VERSION ""

NS_ :

BS_:

BU_: ARS_FD SHVU_CCS_FD WPC_FD WPC2_FD SCM_FD SHVU_FRNT_FD GW_SAU_DRV_FD ATS_FD PSB_FD GW_PSU_RR_FD SHVU_RL_FD RWPC_FD CGW_CCU OHCL_FD SHVU_REAR_FD BLTN_CAM_FD GW_PSU_DRV_FD FCS_FD GW_PSU_AST_FD GW_PSU_3RD_FD RCS_FD SHVU_3RD_FD GW_PSU_RL_FD SHVU_RR_FD RCM_FD SGU_FD DCM_FD

BO_ 813 SBCM_DRV_FD_01_200ms: 32 CGW_CCU
 SG_ SBCM_DRV_FD_Crc1Val : 0|16@1+ (1,0) [0|0] ""  GW_PSU_DRV_FD
 SG_ Latch_TypeOption_DRV : 100|2@1+ (1,0) [0|0] ""  RWPC_FD,WPC2_FD,WPC_FD
 SG_ DRV_SWFailAlarm : 102|2@1+ (1,0) [0|0] ""  ATS_FD
 SG_ USM_PwrDRApprOpnSetSta : 104|2@1+ (1,0) [0|0] "" Vector__XXX
 SG_ USM_PwrDRApprOpnSetOpt : 106|2@1+ (1,0) [0|0] "" Vector__XXX
 SG_ USM_PwrDRCloseByRKELockSta : 108|2@1+ (1,0) [0|0] "" Vector__XXX
 SG_ USM_PwrDRCloseByRKELockOpt : 110|2@1+ (1,0) [0|0] "" Vector__XXX
 SG_ USM_PwrDRCloseByBrakeSta : 112|2@1+ (1,0) [0|0] "" Vector__XXX
 SG_ USM_PwrDRCloseByBrakeOpt : 114|2@1+ (1,0) [0|0] "" Vector__XXX
 SG_ USM_PwrDRBuzzerSta : 116|2@1+ (1,0) [0|0] "" Vector__XXX
 SG_ USM_PwrDRBuzzerOpt : 118|2@1+ (1,0) [0|0] "" Vector__XXX
 SG_ PDS_TypeOption_DRV : 120|2@1+ (1,0) [0|0] ""  ATS_FD
 SG_ C_DrvDoorApproachOpen : 122|2@1+ (1,0) [0|0] "" Vector__XXX
 SG_ C_DrvDoorApproachClose : 124|2@1+ (1,0) [0|0] "" Vector__XXX
 SG_ DoorLock_PDSLkSwSta_DRV : 126|2@1+ (1,0) [0|0] "" Vector__XXX
 SG_ SBCM_DRV_DiagSta : 136|2@1+ (1,0) [0|0] "" Vector__XXX
 SG_ DoorLock_CtrlDrLkUnLkSwSta_SBCM : 138|2@1+ (1,0) [0|0] "" Vector__XXX
 SG_ SBCM_PsvDrLkReq : 144|2@1+ (1,0) [0|0] "" Vector__XXX
 SG_ CDMAutoWashModeSet_SBCM : 146|3@1+ (1,0) [0|0] "" Vector__XXX
 SG_ USM_DrvGhostDoorSta : 150|2@1+ (1,0) [0|0] "" Vector__XXX
 SG_ Mirror_LH_FoldingSta : 152|2@1+ (1,0) [0|0] "" Vector__XXX
 SG_ Mirror_LH_UnfoldingSta : 154|2@1+ (1,0) [0|0] "" Vector__XXX
 SG_ DRV_CrashMRActAlarm : 156|2@1+ (1,0) [0|0] "" Vector__XXX
 SG_ AFH_DRV_FldUnFldSta : 158|2@1+ (1,0) [0|0] "" Vector__XXX
 SG_ SBCM_DRV_FD_AlvCnt1Val : 16|8@1+ (1,0) [0|0] ""  GW_PSU_DRV_FD
 SG_ MirrorFldReq : 160|2@1+ (1,0) [0|0] "" Vector__XXX
 SG_ OMU_TypeOption_DRV : 162|2@1+ (1,0) [0|0] "" Vector__XXX
 SG_ IMS_OSMirPlayBackSta_LH : 164|4@1+ (1,0) [0|0] ""  GW_PSU_DRV_FD
 SG_ ECMMRR_PLUS : 168|8@1+ (1,0) [0|0] "" Vector__XXX
 SG_ EHL_TxInfo_SBCM_DRV : 176|3@1+ (1,0) [0|0] "" Vector__XXX
 SG_ IMS_OSMirPlayBackSta_LH_New : 184|4@1+ (1,0) [0|0] ""  GW_PSU_DRV_FD
 SG_ CDM_InsideOpnSwSta : 200|2@1+ (1,0) [0|0] "" Vector__XXX
 SG_ CDM_TypeOption : 202|2@1+ (1,0) [0|0] "" Vector__XXX
 SG_ CDM_ImmeChgSw_SBCM : 208|2@1+ (1,0) [0|0] "" Vector__XXX
 SG_ CDM_FobSrchReq_DRV : 210|2@1+ (1,0) [0|0] "" Vector__XXX
 SG_ CDM_OpnClsState_SBCM : 212|2@1+ (1,0) [0|0] "" Vector__XXX
 SG_ CDM_WarnMsg_SBCM : 214|2@1+ (1,0) [0|0] "" Vector__XXX
 SG_ CDM_AutoWashModeSta : 216|3@1+ (1,0) [0|0] "" Vector__XXX
 SG_ CDM_CmdStatus_SBCM : 220|4@1+ (1,0) [0|0] "" Vector__XXX
 SG_ CDM_OutsideOpnSwSta : 224|2@1+ (1,0) [0|0] "" Vector__XXX
 SG_ PwrDRBuzzerOut_DRV : 226|2@1+ (1,0) [0|0] "" Vector__XXX
 SG_ Warn_HoodSwSta_SBCM : 228|2@1+ (1,0) [0|0] ""  BLTN_CAM_FD
 SG_ Hood_TypeOption : 230|2@1+ (1,0) [0|0] ""  BLTN_CAM_FD
 SG_ SBCM_FrunkSta : 232|2@1+ (1,0) [0|0] "" Vector__XXX
 SG_ Warn_HoodSwFullSta_SBCM : 234|2@1+ (1,0) [0|0] "" Vector__XXX
 SG_ FrunkWarning_SBCM : 236|2@1+ (1,0) [0|0] "" Vector__XXX
 SG_ SBCM_Longkey_DRVDrAtClsSwSta : 238|2@1+ (1,0) [0|0] "" Vector__XXX
 SG_ FrunkReleaseSwSta_SBCM : 24|2@1+ (1,0) [0|0] "" Vector__XXX
 SG_ PwrDRClosingDRVDrSta : 240|3@1+ (1,0) [0|0] ""  ATS_FD
 SG_ Drv_DrLkRetryFail_SBCM : 243|2@1+ (1,0) [0|0] "" Vector__XXX
 SG_ CDM_GbtImmeChgSw_SBCM : 246|2@1+ (1,0) [0|0] "" Vector__XXX
 SG_ CDM_GbtOpnClsState_SBCM : 248|2@1+ (1,0) [0|0] "" Vector__XXX
 SG_ CDM_GbtWarnMsg_SBCM : 250|2@1+ (1,0) [0|0] "" Vector__XXX
 SG_ CDM_GbtOutsideOpnSwSta : 252|2@1+ (1,0) [0|0] "" Vector__XXX
 SG_ DoorLock_DrvLkOutSta_SBCM : 254|2@1+ (1,0) [0|0] "" Vector__XXX
 SG_ FrunkEmergencySwSta_SBCM : 28|2@1+ (1,0) [0|0] "" Vector__XXX
 SG_ DRV_DetectObj_warn_LH : 30|2@1+ (1,0) [0|0] ""  ATS_FD
 SG_ PwrDROpenClosingDdvSdDRSta : 32|3@1+ (1,0) [0|0] ""  ATS_FD
 SG_ PwrDRBuzzerOut_DRV_New : 35|3@1+ (1,0) [0|0] "" Vector__XXX
 SG_ Coach_TypeOption_DRV : 38|2@1+ (1,0) [0|0] ""  ATS_FD,GW_PSU_RL_FD,GW_PSU_RR_FD
 SG_ PwrDrSta_Drv : 40|2@1+ (1,0) [0|0] ""  ATS_FD
 SG_ PwrDrSta_DrvSd : 42|2@1+ (1,0) [0|0] ""  ATS_FD
 SG_ USM_PwrDrOpnTypSta : 44|2@1+ (1,0) [0|0] "" Vector__XXX
 SG_ DischrgDr_OpnClsState_SBCM : 46|2@1+ (1,0) [0|0] "" Vector__XXX
 SG_ SBCM_FL_DoorAngle : 48|7@1+ (1,0) [0|0] "˚"  ATS_FD
 SG_ SBCM_DoorType_DRV : 60|2@1+ (1,0) [0|0] "" Vector__XXX
 SG_ CDM_DrType_DRV : 62|2@1+ (1,0) [0|0] "" Vector__XXX
 SG_ DRVDoorPushAlarm : 72|2@1+ (1,0) [0|0] "" Vector__XXX
 SG_ DRV_CrashUnlockCmd : 74|1@1+ (1,0) [0|0] ""  BLTN_CAM_FD
 SG_ C_ApprOpenStatus : 75|1@1+ (1,0) [0|0] "" Vector__XXX
 SG_ DoorLock_DrvKeyLkSwSta_SBCM : 80|2@1+ (1,0) [0|0] "" Vector__XXX
 SG_ DoorLock_DrvKeyUnLkSwSta_SBCM : 82|2@1+ (1,0) [0|0] "" Vector__XXX
 SG_ Warn_DrvDrSwSta_SBCM : 84|2@1+ (1,0) [0|0] ""  ATS_FD,BLTN_CAM_FD,DCM_FD,GW_PSU_DRV_FD,PSB_FD,RWPC_FD,WPC2_FD,WPC_FD
 SG_ DoorLock_DrvDrUnLkSta_SBCM : 86|2@1+ (1,0) [0|0] ""  ATS_FD,FCS_FD,GW_PSU_DRV_FD
 SG_ DRV_SEAWarn_LH : 88|2@1+ (1,0) [0|0] ""  ATS_FD
 SG_ DRV_SEAWarn_RH : 90|2@1+ (1,0) [0|0] "" Vector__XXX
 SG_ DRV_SEWWarn_LH : 92|2@1+ (1,0) [0|0] "" Vector__XXX
 SG_ DRV_SEWWarn_RH : 94|2@1+ (1,0) [0|0] "" Vector__XXX
 SG_ DRV_MRActivationAlarm : 96|2@1+ (1,0) [0|0] "" Vector__XXX
 SG_ DRV_ReleaseWarn : 98|2@1+ (1,0) [0|0] "" Vector__XXX

BO_ 994 PDC_FD_03_200ms: 16 CGW_CCU
 SG_ PDC_FD_Crc3Val : 0|16@1+ (1,0) [0|0] ""  GW_PSU_DRV_FD
 SG_ PDC_FD_AlvCnt3Val : 16|8@1+ (1,0) [0|0] ""  GW_PSU_DRV_FD
 SG_ Warn_DrvDrSwSta : 64|2@1+ (1,0) [0|0] ""  BLTN_CAM_FD,DCM_FD,GW_PSU_DRV_FD,PSB_FD,RWPC_FD,WPC2_FD,WPC_FD
 SG_ Warn_AsstDrSwSta : 66|2@1+ (1,0) [0|0] ""  BLTN_CAM_FD,DCM_FD,GW_PSU_AST_FD,GW_PSU_RL_FD,GW_SAU_DRV_FD,PSB_FD,RWPC_FD,WPC2_FD,WPC_FD
 SG_ Warn_RrLftDrSwSta : 68|2@1+ (1,0) [0|0] ""  BLTN_CAM_FD,DCM_FD,GW_PSU_AST_FD,GW_PSU_RL_FD,GW_PSU_RR_FD,PSB_FD,RWPC_FD,SHVU_RL_FD,WPC2_FD,WPC_FD
 SG_ Warn_RrRtDrSwSta : 70|2@1+ (1,0) [0|0] ""  BLTN_CAM_FD,DCM_FD,GW_PSU_AST_FD,GW_PSU_RL_FD,GW_PSU_RR_FD,PSB_FD,RWPC_FD,SHVU_RR_FD,WPC2_FD,WPC_FD
 SG_ Warn_HoodSwSta : 72|2@1+ (1,0) [0|0] ""  BLTN_CAM_FD
 SG_ DoorLock_DrvDrUnLkSta : 74|2@1+ (1,0) [0|0] ""  GW_PSU_DRV_FD
 SG_ DoorLock_AsstDrUnLkSta : 76|2@1+ (1,0) [0|0] "" Vector__XXX
 SG_ DoorLock_RrLftDrUnLkSta : 78|2@1+ (1,0) [0|0] "" Vector__XXX
 SG_ DoorLock_RrRtDrUnLkSta : 80|2@1+ (1,0) [0|0] "" Vector__XXX
 SG_ DoorLock_DrvKeyLkSwSta : 82|2@1+ (1,0) [0|0] "" Vector__XXX
 SG_ DoorLock_DrvKeyUnLkSwSta : 84|2@1+ (1,0) [0|0] "" Vector__XXX
 SG_ DoorLock_CtrlDrLkSwSta_ICU : 86|2@1+ (1,0) [0|0] "" Vector__XXX
 SG_ DoorLock_CtrlDrUnLkSwSta_ICU : 88|2@1+ (1,0) [0|0] "" Vector__XXX
 SG_ DoorLock_CtrlDrLkUnLkSwSta_ICU : 90|2@1+ (1,0) [0|0] "" Vector__XXX
 SG_ C_CrashUnlockState : 92|2@1+ (1,0) [0|0] ""  BLTN_CAM_FD
 SG_ Lamp_LedHdLmpSta : 94|2@1+ (1,0) [0|0] "" Vector__XXX
 SG_ Warn_ChaDrSwFrtSta : 96|2@1+ (1,0) [0|0] "" Vector__XXX
 SG_ Warn_ChaDrSwRrSta : 98|2@1+ (1,0) [0|0] "" Vector__XXX

BO_ 1242 CLU_09_00ms: 8 CGW_CCU
 SG_ CLU_Crc9Val : 0|16@1+ (1,0) [0|0] "" Vector__XXX
 SG_ CLU_AlvCnt9Val : 16|8@1+ (1,0) [0|0] "" Vector__XXX
 SG_ USM_MdLmpClrSetReq : 24|4@1+ (1,0) [0|0] "" Vector__XXX
 SG_ USM_RrWiperRevSetReq : 28|2@1+ (1,0) [0|0] "" Vector__XXX
 SG_ USM_RrStRemindSetReq : 30|2@1+ (1,0) [0|0] "" Vector__XXX
 SG_ USM_RrWpcSetReq : 32|2@1+ (1,0) [0|0] "" Vector__XXX
 SG_ USM_WpcSetReq : 34|2@1+ (1,0) [0|0] ""  WPC_FD,WPC2_FD
 SG_ USM_SeqLmpSetReq : 36|2@1+ (1,0) [0|0] "" Vector__XXX
 SG_ USM_UnlckWlcmSetReq : 38|2@1+ (1,0) [0|0] "" Vector__XXX
 SG_ USM_SmrtWlcmSetReq : 40|2@1+ (1,0) [0|0] "" Vector__XXX
 SG_ USM_UipSetReq : 42|2@1+ (1,0) [0|0] "" Vector__XXX
 SG_ USM_DigitalKeyEnblSetReq : 44|2@1+ (1,0) [0|0] "" Vector__XXX
 SG_ USM_OwnerPhnRegSetReq : 46|2@1+ (1,0) [0|0] "" Vector__XXX
 SG_ USM_NFCCard1RegSetReq : 48|2@1+ (1,0) [0|0] "" Vector__XXX
 SG_ USM_NFCCard2RegSetReq : 50|2@1+ (1,0) [0|0] "" Vector__XXX
 SG_ USM_ProcStpReq : 52|1@1+ (1,0) [0|0] "" Vector__XXX
 SG_ USM_PwrAutoOffTimeSetReq : 54|3@1+ (1,0) [0|0] "" Vector__XXX
 SG_ USM_RrStRemindSetReq_RestMode : 57|3@1+ (1,0) [0|0] "" Vector__XXX
 SG_ USM_1stRrStRemindSetReq : 60|2@1+ (1,0) [0|0] "" Vector__XXX
 SG_ USM_Wpc2SetReq : 62|2@1+ (1,0) [0|0] ""  WPC_FD,WPC2_FD

BO_ 811 SBCM_AST_FD_01_200ms: 32 CGW_CCU
 SG_ SBCM_AST_FD_Crc1Val : 0|16@1+ (1,0) [0|0] ""  GW_PSU_DRV_FD
 SG_ USM_AstGhostDoorSta : 100|2@1+ (1,0) [0|0] "" Vector__XXX
 SG_ AST_SWFailAlarm : 102|2@1+ (1,0) [0|0] ""  ATS_FD
 SG_ DoorLock_PDSLkSwSta_AST : 104|2@1+ (1,0) [0|0] "" Vector__XXX
 SG_ PDS_TypeOption_AST : 106|2@1+ (1,0) [0|0] "" Vector__XXX
 SG_ AFCU_AutoWashModeSta_SBCM_AST : 120|3@1+ (1,0) [0|0] "" Vector__XXX
 SG_ CDM_AutoWashModeSta_SBCM_AST : 123|3@1+ (1,0) [0|0] "" Vector__XXX
 SG_ AFH_AST_FldUnFldSta : 126|2@1+ (1,0) [0|0] "" Vector__XXX
 SG_ SBCM_AST_DiagSta : 136|2@1+ (1,0) [0|0] "" Vector__XXX
 SG_ CDM_TypeOption_AST : 138|2@1+ (1,0) [0|0] "" Vector__XXX
 SG_ CDM_ImmeChgSw_AST : 144|2@1+ (1,0) [0|0] "" Vector__XXX
 SG_ CDM_FobSrchReq_AST : 146|2@1+ (1,0) [0|0] "" Vector__XXX
 SG_ CDM_OpnClsState_AST : 148|2@1+ (1,0) [0|0] "" Vector__XXX
 SG_ CDM_WarnMsg_AST : 150|2@1+ (1,0) [0|0] "" Vector__XXX
 SG_ Mirror_RH_FoldingSta : 152|2@1+ (1,0) [0|0] "" Vector__XXX
 SG_ Mirror_RH_UnfoldingSta : 154|2@1+ (1,0) [0|0] "" Vector__XXX
 SG_ CDM_CmdStatus_AST : 156|4@1+ (1,0) [0|0] "" Vector__XXX
 SG_ SBCM_AST_FD_AlvCnt1Val : 16|8@1+ (1,0) [0|0] ""  GW_PSU_DRV_FD
 SG_ AST_CrashMRActAlarm : 160|2@1+ (1,0) [0|0] "" Vector__XXX
 SG_ PwrDRBuzzerOut_AST : 162|2@1+ (1,0) [0|0] "" Vector__XXX
 SG_ IMS_OSMirPlayBackSta_RH : 164|4@1+ (1,0) [0|0] ""  GW_PSU_DRV_FD
 SG_ PwrDRClosingASTDrSta : 168|3@1+ (1,0) [0|0] ""  ATS_FD
 SG_ CDM_OutsideOpnSwSta_AST : 172|2@1+ (1,0) [0|0] "" Vector__XXX
 SG_ SBCM_Longkey_ASTDrAtClsSwSta : 174|2@1+ (1,0) [0|0] "" Vector__XXX
 SG_ Hood_TypeOption_AST : 176|2@1+ (1,0) [0|0] "" Vector__XXX
 SG_ Warn_HoodSwSta_AST : 178|2@1+ (1,0) [0|0] "" Vector__XXX
 SG_ FrunkWarning_AST : 180|2@1+ (1,0) [0|0] "" Vector__XXX
 SG_ SBCM_FrunkSta_AST : 182|2@1+ (1,0) [0|0] "" Vector__XXX
 SG_ IMS_OSMirPlayBackSta_RH_New : 184|4@1+ (1,0) [0|0] ""  GW_PSU_DRV_FD
 SG_ Ast_DrLkRetryFail_SBCM : 188|2@1+ (1,0) [0|0] "" Vector__XXX
 SG_ DoorLock_AstLkOutSta_SBCM : 190|2@1+ (1,0) [0|0] "" Vector__XXX
 SG_ FrunkReleaseSwSta_SBCM_AST : 192|2@1+ (1,0) [0|0] "" Vector__XXX
 SG_ FrunkInsideRelSwSta_SBCM_AST : 194|2@1+ (1,0) [0|0] "" Vector__XXX
 SG_ FrunkEmergencySwSta_SBCM_AST : 196|2@1+ (1,0) [0|0] "" Vector__XXX
 SG_ PwrDrSta_Ast : 24|2@1+ (1,0) [0|0] ""  ATS_FD
 SG_ PwrDrSta_AstSd : 26|2@1+ (1,0) [0|0] ""  ATS_FD
 SG_ DischrgDr_OpnClsState_SBCM_AST : 28|2@1+ (1,0) [0|0] "" Vector__XXX
 SG_ AST_DetectObj_warn_LH : 30|2@1+ (1,0) [0|0] ""  ATS_FD
 SG_ PwrDROpenClosingAstSdDRSta : 32|3@1+ (1,0) [0|0] ""  ATS_FD
 SG_ PwrDRBuzzerOut_AST_New : 35|3@1+ (1,0) [0|0] "" Vector__XXX
 SG_ SBCM_FR_DoorAngle : 40|7@1+ (1,0) [0|0] "˚"  ATS_FD
 SG_ EHL_TxInfo_SBCM_AST : 47|3@1+ (1,0) [0|0] "" Vector__XXX
 SG_ CDM_DrType_AST : 62|2@1+ (1,0) [0|0] "" Vector__XXX
 SG_ ASTDoorPushAlarm : 72|2@1+ (1,0) [0|0] "" Vector__XXX
 SG_ AST_CrashUnlockCmd : 74|1@1+ (1,0) [0|0] ""  BLTN_CAM_FD
 SG_ DoorLock_CtrlDrLkSwSta_SBCM : 80|2@1+ (1,0) [0|0] "" Vector__XXX
 SG_ DoorLock_CtrlDrUnLkSwSta_SBCM : 82|2@1+ (1,0) [0|0] "" Vector__XXX
 SG_ Warn_AsstDrSwSta_SBCM : 84|2@1+ (1,0) [0|0] ""  ATS_FD,BLTN_CAM_FD,DCM_FD,GW_PSU_AST_FD,GW_SAU_DRV_FD,PSB_FD,RWPC_FD,WPC2_FD,WPC_FD
 SG_ DoorLock_AsstDrUnLkSta_SBCM : 86|2@1+ (1,0) [0|0] ""  ATS_FD,FCS_FD
 SG_ AST_SEAWarn_RH : 88|2@1+ (1,0) [0|0] "" Vector__XXX
 SG_ AST_SEAWarn_LH : 90|2@1+ (1,0) [0|0] ""  ATS_FD
 SG_ AST_SEWWarn_LH : 92|2@1+ (1,0) [0|0] "" Vector__XXX
 SG_ AST_SEWWarn_RH : 94|2@1+ (1,0) [0|0] "" Vector__XXX
 SG_ AST_MRActivationAlarm : 96|2@1+ (1,0) [0|0] "" Vector__XXX
 SG_ AST_ReleaseWarn : 98|2@1+ (1,0) [0|0] "" Vector__XXX

BO_ 789 CLU_20_200ms: 16 CGW_CCU
 SG_ CLU_Crc20Val : 0|16@1+ (1,0) [0|0] "" Vector__XXX
 SG_ CLU_AlvCnt20Val : 16|8@1+ (1,0) [0|0] "" Vector__XXX
 SG_ CLU_SndType : 24|2@1- (1,0) [0|0] "" Vector__XXX
 SG_ USM_AdasHDPSetReq : 46|2@1+ (1,0) [0|0] "" Vector__XXX
 SG_ CLU_ClusterUSM : 49|2@1+ (1,0) [0|0] ""  WPC_FD,WPC2_FD

BO_ 849 IAU_FD_04_200ms: 32 CGW_CCU
 SG_ IAU_FD_Crc4Val : 0|16@1+ (1,0) [0|0] "0"  GW_PSU_DRV_FD
 SG_ IAU_DISPWrng : 104|4@1+ (1,0) [0|0] "" Vector__XXX
 SG_ IAU_DigitalKey2Opt : 120|3@1+ (1,0) [0|0] ""  WPC2_FD,WPC_FD
 SG_ IAUwFRULearnState : 124|2@1+ (1,0) [0|0] "" Vector__XXX
 SG_ IAUwFPMLearnState : 126|2@1+ (1,0) [0|0] "" Vector__XXX
 SG_ IAU_ValetDigitalkey : 128|2@1+ (1,0) [0|0] "" Vector__XXX
 SG_ IAU_DigitalKeyNumberOpt : 130|3@1+ (1,0) [0|0] "" Vector__XXX
 SG_ IAU_eSEReprogramSta : 133|2@1+ (1,0) [0|0] "" Vector__XXX
 SG_ IAU_DKOwnerSwapOption : 136|2@1+ (1,0) [0|0] "" Vector__XXX
 SG_ IAU_DgtKeyGrpPrflRval2 : 139|5@1+ (1,0) [0|0] "" Vector__XXX
 SG_ IAU_StartIdentifiedProfile : 144|3@1+ (1,0) [0|0] "" Vector__XXX
 SG_ IAU_DigitalKeyProfileRval2 : 147|5@1+ (1,0) [0|0] "" Vector__XXX
 SG_ IAU_NFCCard1SN : 152|32@1+ (1,0) [0|0] "" Vector__XXX
 SG_ IAU_FD_AlvCnt4Val : 16|8@1+ (1,0) [0|0] "0"  GW_PSU_DRV_FD
 SG_ IAU_StartIdentifiedProfile_Ext : 24|4@1+ (1,0) [0|0] "" Vector__XXX
 SG_ RSPA_UWBRspaExtRngSta : 246|2@1+ (1,0) [0|0] "" Vector__XXX
 SG_ RSPA_CanFltSta : 250|2@1+ (1,0) [0|0] "" Vector__XXX
 SG_ RSPA_BLESigErrSta : 252|2@1+ (1,0) [0|0] "" Vector__XXX
 SG_ RSPA_ConStat : 254|2@1+ (1,0) [0|0] "" Vector__XXX
 SG_ IAU_ProfileIDRVal : 74|4@1+ (1,0) [0|0] ""  BLTN_CAM_FD,GW_PSU_DRV_FD,GW_SAU_DRV_FD,RCM_FD,RWPC_FD,SGU_FD,WPC2_FD,WPC_FD
 SG_ IAU_DigitalKeyProcessingSta : 80|4@1+ (1,0) [0|0] "" Vector__XXX
 SG_ IAU_DigitalKeyExit : 84|4@1+ (1,0) [0|0] "" Vector__XXX
 SG_ IAU_DigitalKeyEnblRVal : 88|2@1+ (1,0) [0|0] "" Vector__XXX
 SG_ IAU_OwnerPhnRegRVal : 90|2@1+ (1,0) [0|0] "" Vector__XXX
 SG_ IAU_NFCCard1RegRVal : 92|2@1+ (1,0) [0|0] "" Vector__XXX
 SG_ IAU_NFCCard2RegRVal : 94|2@1+ (1,0) [0|0] "" Vector__XXX

BO_ 788 RWPC_FD_01_200ms: 16 RWPC_FD
 SG_ RWPC_FD_Crc1Val : 0|16@1+ (1,0) [0|0] "" Vector__XXX
 SG_ RWPC_IndSyncVal : 104|3@1+ (1,0) [0|0] ""  WPC2_FD,WPC_FD
 SG_ RWPC_ResetOpSta : 110|2@1+ (1,0) [0|0] "" Vector__XXX
 SG_ RWPC_FD_AlvCnt1Val : 16|8@1+ (1,0) [0|0] "" Vector__XXX
 SG_ USM_ValCmdSta : 64|2@1+ (1,0) [0|0] ""  ATS_FD,CGW_CCU
 SG_ WPC_PhnLftWrngRWPCSta : 66|3@1+ (1,0) [0|0] ""  ATS_FD,CGW_CCU
 SG_ USM_ValCmdStaforATS : 69|2@1+ (1,0) [0|0] ""  ATS_FD
 SG_ RWPC_SWVerMajor1 : 72|7@1+ (1,0) [0|0] ""  CGW_CCU
 SG_ RWPC_SWVerMinor1 : 80|7@1+ (1,0) [0|0] ""  CGW_CCU
 SG_ RWPC_SWVerMinor2 : 88|7@1+ (1,0) [0|0] ""  CGW_CCU

BO_ 977 BDC_FD_02_200ms: 32 CGW_CCU
 SG_ BDC_FD_Crc2Val : 0|16@1+ (1,0) [0|0] ""  GW_PSU_DRV_FD
 SG_ BDC_FD_AlvCnt2Val : 16|8@1+ (1,0) [0|0] ""  GW_PSU_DRV_FD
 SG_ BCM_KeyInSta : 24|2@1+ (1,0) [0|0] ""  DCM_FD,GW_PSU_3RD_FD,GW_PSU_AST_FD,GW_PSU_DRV_FD,GW_PSU_RL_FD,GW_PSU_RR_FD,GW_SAU_DRV_FD,SGU_FD,SHVU_3RD_FD,SHVU_CCS_FD,SHVU_FRNT_FD,SHVU_REAR_FD,SHVU_RL_FD,SHVU_RR_FD
 SG_ BCM_AccInSta : 26|2@1+ (1,0) [0|0] ""  ATS_FD,DCM_FD,FCS_FD,GW_PSU_3RD_FD,GW_PSU_AST_FD,GW_PSU_DRV_FD,GW_PSU_RL_FD,GW_PSU_RR_FD,GW_SAU_DRV_FD,SCM_FD,SGU_FD,SHVU_3RD_FD,SHVU_CCS_FD,SHVU_FRNT_FD,SHVU_REAR_FD,SHVU_RL_FD,SHVU_RR_FD,WPC2_FD
 SG_ BCM_Ign1InSta : 28|2@1+ (1,0) [0|0] ""  ATS_FD,DCM_FD,FCS_FD,GW_PSU_3RD_FD,GW_PSU_AST_FD,GW_PSU_DRV_FD,GW_PSU_RL_FD,GW_PSU_RR_FD,GW_SAU_DRV_FD,RCM_FD,SCM_FD,SGU_FD,SHVU_3RD_FD,SHVU_CCS_FD,SHVU_FRNT_FD,SHVU_REAR_FD,SHVU_RL_FD,SHVU_RR_FD
 SG_ BCM_Ign2InSta : 30|2@1+ (1,0) [0|0] ""  ATS_FD,DCM_FD,FCS_FD,GW_PSU_3RD_FD,GW_PSU_AST_FD,GW_PSU_DRV_FD,GW_PSU_RL_FD,GW_PSU_RR_FD,GW_SAU_DRV_FD,RCM_FD,SCM_FD,SGU_FD,SHVU_3RD_FD,SHVU_CCS_FD,SHVU_FRNT_FD,SHVU_REAR_FD,SHVU_RL_FD,SHVU_RR_FD
 SG_ IBU_HDPSpprtSWVer : 32|6@1+ (1,0) [0|0] "" Vector__XXX
 SG_ IBU_HDPSpprtRdy : 38|2@1+ (1,0) [0|0] "" Vector__XXX
 SG_ BCM_GearPosPSta : 40|2@1+ (1,0) [0|0] ""  ATS_FD,GW_PSU_3RD_FD,GW_PSU_AST_FD,GW_PSU_DRV_FD,GW_PSU_RL_FD,GW_PSU_RR_FD,SCM_FD,SHVU_RL_FD,SHVU_RR_FD
 SG_ BCM_SmkOptTyp : 42|2@1+ (1,0) [0|0] ""  RWPC_FD,WPC2_FD,WPC_FD
 SG_ BDC_ResetOpSta : 44|2@1+ (1,0) [0|0] "" Vector__XXX
 SG_ IBU_SWVerMajor1 : 48|7@1+ (1,0) [0|0] "" Vector__XXX
 SG_ IBU_SWVerMinor1 : 56|7@1+ (1,0) [0|0] "" Vector__XXX
 SG_ IBU_SWVerMinor2 : 64|7@1+ (1,0) [0|0] "" Vector__XXX
 SG_ BDC_PlatformVerType : 72|4@1+ (1,0) [0|0] "" Vector__XXX
 SG_ BDC_PlatformVerDate : 80|8@1+ (1,0) [0|0] "" Vector__XXX

BO_ 914 WPC2_FD_01_200ms: 16 WPC_FD
 SG_ WPC2_FD_Crc1Val : 0|16@1+ (1,0) [0|0] "" Vector__XXX
 SG_ WPC2_IndSyncVal : 104|3@1+ (1,0) [0|0] ""  RWPC_FD
 SG_ WPC2_ResetOpSta : 110|2@1+ (1,0) [0|0] "" Vector__XXX
 SG_ WPC2_FD_AlvCnt1Val : 16|8@1+ (1,0) [0|0] "" Vector__XXX
 SG_ USM_CmdWPC2Sta : 64|2@1+ (1,0) [0|0] ""  CGW_CCU
 SG_ WPC2_PhnLftWrngSta : 66|3@1+ (1,0) [0|0] ""  CGW_CCU
 SG_ WPC2_OptSta : 76|2@1+ (1,0) [0|0] ""  CGW_CCU
 SG_ WPC2_SWVerMajor1 : 80|7@1+ (1,0) [0|0] ""  CGW_CCU
 SG_ WPC2_SWVerMinor1 : 88|7@1+ (1,0) [0|0] ""  CGW_CCU
 SG_ WPC2_SWVerMinor2 : 96|7@1+ (1,0) [0|0] ""  CGW_CCU

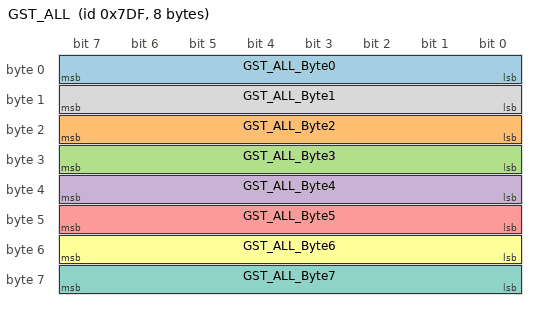
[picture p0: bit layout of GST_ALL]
BO_ 2015 GST_ALL: 8 CGW_CCU
 SG_ GST_ALL_Byte0 : 0|8@1+ (1,0) [0|0] ""  ARS_FD,ATS_FD,FCS_FD,GW_PSU_3RD_FD,GW_PSU_AST_FD,GW_PSU_DRV_FD,GW_PSU_RL_FD,GW_PSU_RR_FD,GW_SAU_DRV_FD,PSB_FD,RCM_FD,RCS_FD,RWPC_FD,SCM_FD,SGU_FD,SHVU_3RD_FD,SHVU_CCS_FD,SHVU_FRNT_FD,SHVU_REAR_FD,SHVU_RL_FD,SHVU_RR_FD,WPC2_FD,WPC_FD
 SG_ GST_ALL_Byte2 : 16|8@1+ (1,0) [0|0] ""  ARS_FD,ATS_FD,FCS_FD,GW_PSU_3RD_FD,GW_PSU_AST_FD,GW_PSU_DRV_FD,GW_PSU_RL_FD,GW_PSU_RR_FD,GW_SAU_DRV_FD,PSB_FD,RCM_FD,RCS_FD,RWPC_FD,SCM_FD,SGU_FD,SHVU_3RD_FD,SHVU_CCS_FD,SHVU_FRNT_FD,SHVU_REAR_FD,SHVU_RL_FD,SHVU_RR_FD,WPC2_FD,WPC_FD
 SG_ GST_ALL_Byte3 : 24|8@1+ (1,0) [0|0] ""  ARS_FD,ATS_FD,FCS_FD,GW_PSU_3RD_FD,GW_PSU_AST_FD,GW_PSU_DRV_FD,GW_PSU_RL_FD,GW_PSU_RR_FD,GW_SAU_DRV_FD,PSB_FD,RCM_FD,RCS_FD,RWPC_FD,SCM_FD,SGU_FD,SHVU_3RD_FD,SHVU_CCS_FD,SHVU_FRNT_FD,SHVU_REAR_FD,SHVU_RL_FD,SHVU_RR_FD,WPC2_FD,WPC_FD
 SG_ GST_ALL_Byte4 : 32|8@1+ (1,0) [0|0] ""  ARS_FD,ATS_FD,FCS_FD,GW_PSU_3RD_FD,GW_PSU_AST_FD,GW_PSU_DRV_FD,GW_PSU_RL_FD,GW_PSU_RR_FD,GW_SAU_DRV_FD,PSB_FD,RCM_FD,RCS_FD,RWPC_FD,SCM_FD,SGU_FD,SHVU_3RD_FD,SHVU_CCS_FD,SHVU_FRNT_FD,SHVU_REAR_FD,SHVU_RL_FD,SHVU_RR_FD,WPC2_FD,WPC_FD
 SG_ GST_ALL_Byte5 : 40|8@1+ (1,0) [0|0] ""  ARS_FD,ATS_FD,FCS_FD,GW_PSU_3RD_FD,GW_PSU_AST_FD,GW_PSU_DRV_FD,GW_PSU_RL_FD,GW_PSU_RR_FD,GW_SAU_DRV_FD,PSB_FD,RCM_FD,RCS_FD,RWPC_FD,SCM_FD,SGU_FD,SHVU_3RD_FD,SHVU_CCS_FD,SHVU_FRNT_FD,SHVU_REAR_FD,SHVU_RL_FD,SHVU_RR_FD,WPC2_FD,WPC_FD
 SG_ GST_ALL_Byte6 : 48|8@1+ (1,0) [0|0] ""  ARS_FD,ATS_FD,FCS_FD,GW_PSU_3RD_FD,GW_PSU_AST_FD,GW_PSU_DRV_FD,GW_PSU_RL_FD,GW_PSU_RR_FD,GW_SAU_DRV_FD,PSB_FD,RCM_FD,RCS_FD,RWPC_FD,SCM_FD,SGU_FD,SHVU_3RD_FD,SHVU_CCS_FD,SHVU_FRNT_FD,SHVU_REAR_FD,SHVU_RL_FD,SHVU_RR_FD,WPC2_FD,WPC_FD
 SG_ GST_ALL_Byte7 : 56|8@1+ (1,0) [0|0] ""  ARS_FD,ATS_FD,FCS_FD,GW_PSU_3RD_FD,GW_PSU_AST_FD,GW_PSU_DRV_FD,GW_PSU_RL_FD,GW_PSU_RR_FD,GW_SAU_DRV_FD,PSB_FD,RCM_FD,RCS_FD,RWPC_FD,SCM_FD,SGU_FD,SHVU_3RD_FD,SHVU_CCS_FD,SHVU_FRNT_FD,SHVU_REAR_FD,SHVU_RL_FD,SHVU_RR_FD,WPC2_FD,WPC_FD
 SG_ GST_ALL_Byte1 : 8|8@1+ (1,0) [0|0] ""  ARS_FD,ATS_FD,FCS_FD,GW_PSU_3RD_FD,GW_PSU_AST_FD,GW_PSU_DRV_FD,GW_PSU_RL_FD,GW_PSU_RR_FD,GW_SAU_DRV_FD,PSB_FD,RCM_FD,RCS_FD,RWPC_FD,SCM_FD,SGU_FD,SHVU_3RD_FD,SHVU_CCS_FD,SHVU_FRNT_FD,SHVU_REAR_FD,SHVU_RL_FD,SHVU_RR_FD,WPC2_FD,WPC_FD

BO_TX_BU_ 914 : WPC_FD,WPC2_FD;
CM_ BO_ 813 "[PE] Periodic and On Event";
CM_ SG_ 813 SBCM_DRV_FD_Crc1Val "SBCM_DRV_FD_CyclicRedundancyCheck1Value";
CM_ SG_ 813 C_DrvDoorApproachOpen "Approach open";
CM_ SG_ 813 DoorLock_CtrlDrLkUnLkSwSta_SBCM "Central Door Lock/Unlock Switch State";
CM_ SG_ 813 CDMAutoWashModeSet_SBCM "Auto wash mode set signal for CDM from SBCM_DRV";
CM_ SG_ 813 SBCM_DRV_FD_AlvCnt1Val "SBCM_DRV_FD_AliveCounter1Value";
CM_ SG_ 813 ECMMRR_PLUS "ECM Voltage value";
CM_ SG_ 813 EHL_TxInfo_SBCM_DRV "Electronic hood latch status signal transfer for dual hood latch type (Copy to CANFD)";
CM_ SG_ 813 CDM_TypeOption "CDM_HS_OptionType";
CM_ SG_ 813 CDM_ImmeChgSw_SBCM "State of Immediate Charging Switch";
CM_ SG_ 813 CDM_OpnClsState_SBCM "CDM_HS_ OpenCloseState";
CM_ SG_ 813 CDM_WarnMsg_SBCM "CDM_HS_WarningMessage";
CM_ SG_ 813 CDM_CmdStatus_SBCM "CDM_HS_CommandStatus";
CM_ SG_ 813 Hood_TypeOption "E-Hood_Option Type";
CM_ SG_ 813 FrunkReleaseSwSta_SBCM "FrunkReleaseState";
CM_ SG_ 813 CDM_GbtImmeChgSw_SBCM "State of Immediate Charging Switch";
CM_ SG_ 813 CDM_GbtOpnClsState_SBCM "CDM_HS_ OpenCloseState";
CM_ SG_ 813 CDM_GbtWarnMsg_SBCM "CDM_HS_WarningMessage";
CM_ SG_ 813 FrunkEmergencySwSta_SBCM "FrunkEmergencySwState";
CM_ SG_ 813 C_ApprOpenStatus "Stop fob searching signal";
CM_ SG_ 813 DoorLock_DrvKeyLkSwSta_SBCM "DoorLock_DriverKeyLockSwitchStatus ##2G## -  - C_DrvKeyLockSw";
CM_ SG_ 813 DoorLock_DrvKeyUnLkSwSta_SBCM "DoorLock_DriverKeyUnLockSwitchStatus ##2G## -  - C_DrvKeyUnlockSw";
CM_ SG_ 813 Warn_DrvDrSwSta_SBCM "DoorLock_DriverDoorSwitchStatus ##2G## -  - C_DrvDrSw,CF_Gway_DrvDrSw,Warn_DrvDrSwSta";
CM_ SG_ 813 DoorLock_DrvDrUnLkSta_SBCM "DoorLock_DriverDoorUnLockStatus ##2G## -  - C_DrvUnlockState,CF_Gway_DrvUnlockState";
CM_ BO_ 994 "[PE] Periodic and On Event";
CM_ SG_ 994 PDC_FD_Crc3Val "PDC_FD_CyclicRedundancyCheck3Value";
CM_ SG_ 994 PDC_FD_AlvCnt3Val "PDC_FD_AliveCounter3Value";
CM_ SG_ 994 Warn_DrvDrSwSta "DoorLock_DriverDoorSwitchStatus ##2G## -  - C_DrvDrSw,CF_Gway_DrvDrSw,Warn_DrvDrSwSta";
CM_ SG_ 994 Warn_AsstDrSwSta "Warn_AssistDoorSwitchStatus ##2G## -  - C_AstDrSw,CF_Gway_AstDrSw,Warn_AsstDrSwSta";
CM_ SG_ 994 Warn_RrLftDrSwSta "Warn_RearLeftDoorSwitchStatus ##2G## -  - C_RLDrSw,CF_Gway_RLDrSw,Warn_RrLftDrSwSta";
CM_ SG_ 994 Warn_RrRtDrSwSta "Warn_RearRightDoorSwitchStatus ##2G## -  - C_RRDrSw,CF_Gway_RRDrSw,Warn_RrRtDrSwSta";
CM_ SG_ 994 Warn_HoodSwSta "Warn_HoodSwitchStatus ##2G## -  - C_HoodSw,CF_Gway_HoodSw";
CM_ SG_ 994 DoorLock_DrvDrUnLkSta "DoorLock_DriverDoorUnLockStatus ##2G## -  - C_DrvUnlockState,CF_Gway_DrvUnlockState";
CM_ SG_ 994 DoorLock_AsstDrUnLkSta "DoorLock_AssistDoorUnLockStatus ##2G## -  - C_AstUnlockState,DoorLock_AsstDrUnLkSta";
CM_ SG_ 994 DoorLock_RrLftDrUnLkSta "DoorLock_RearLeftDoorUnLockStatus ##2G## -  - C_RLUnlockState,DoorLock_RrLftDrUnLkSta";
CM_ SG_ 994 DoorLock_RrRtDrUnLkSta "DoorLock_RearRightDoorUnLockStatus ##2G## -  - C_RRUnlockState,DoorLock_RrRtDrUnLkSta";
CM_ SG_ 994 DoorLock_DrvKeyLkSwSta "DoorLock_DriverKeyLockSwitchStatus ##2G## -  - C_DrvKeyLockSw";
CM_ SG_ 994 DoorLock_DrvKeyUnLkSwSta "DoorLock_DriverKeyUnLockSwitchStatus ##2G## -  - C_DrvKeyUnlockSw";
CM_ SG_ 994 DoorLock_CtrlDrLkSwSta_ICU "Central Door Lock Switch State(DRV or AST or RL or RR Door trim)";
CM_ SG_ 994 DoorLock_CtrlDrUnLkSwSta_ICU "Central Door Unlock Switch State(DRV or AST or RL or RR Door trim)";
CM_ SG_ 994 DoorLock_CtrlDrLkUnLkSwSta_ICU "Central Door Lock/Unlock Switch State(C/PAD, Integrated & self return type)";
CM_ SG_ 994 C_CrashUnlockState "Crash Unlock Active State";
CM_ SG_ 994 Lamp_LedHdLmpSta "Lamp_LedHeadLampStatus ##2G## -  - CF_Afs_LedHLStat";
CM_ SG_ 994 Warn_ChaDrSwFrtSta "##2G## - -  CF_Gway_ChaDrSwFrt";
CM_ SG_ 994 Warn_ChaDrSwRrSta "##2G## -  - CF_Gway_ChaDrSwRr";
CM_ BO_ 1242 "[EC] On Event and On Change";
CM_ SG_ 1242 CLU_Crc9Val "CLU_CyclicRedundancyCheck9Value";
CM_ SG_ 1242 CLU_AlvCnt9Val "CLU_AliveCounter9Value";
CM_ SG_ 1242 USM_MdLmpClrSetReq "USM_MoodLampColorSetRequest";
CM_ SG_ 1242 USM_RrWiperRevSetReq "USM_RearWiperReverseSetRequest";
CM_ SG_ 1242 USM_RrStRemindSetReq "USM_RrseatReminderSetRequest(2nd :General: CLU20/CF_Clu_RrSeatRemindNValueSet)";
CM_ SG_ 1242 USM_RrWpcSetReq "USM_RearWpcSetRequest";
CM_ SG_ 1242 USM_WpcSetReq "USM_WpcSetRequest";
CM_ SG_ 1242 USM_SeqLmpSetReq "USM_SequencialLampSetRequest";
CM_ SG_ 1242 USM_UnlckWlcmSetReq "USM_UnlockWelcomeSetRequest";
CM_ SG_ 1242 USM_SmrtWlcmSetReq "USM_SmartWelcomeSetRequest";
CM_ SG_ 1242 USM_UipSetReq "2nd General: CF_Clu_UIPNValueSet";
CM_ SG_ 1242 USM_DigitalKeyEnblSetReq "Request to set the Digital Key ON or OFF(2nd General DB: CF_Clu_DigitalKeyNValueSet)";
CM_ SG_ 1242 USM_OwnerPhnRegSetReq "2nd general DB: CF_Clu_OwnerPhoneNValueSet";
CM_ SG_ 1242 USM_NFCCard1RegSetReq "2nd General DB:CF_Clu_NFCCard1NValueSet";
CM_ SG_ 1242 USM_NFCCard2RegSetReq "2nd General DB:CF_Clu_NFCCard2NValueSet";
CM_ SG_ 1242 USM_ProcStpReq "2nd General DB:CF_Clu_ProcessStopReq";
CM_ SG_ 1242 USM_PwrAutoOffTimeSetReq "USM_PowerAutoofftimeSetRequest";
CM_ SG_ 1242 USM_RrStRemindSetReq_RestMode "Request to set  Restmod of Rear Seat remind";
CM_ SG_ 1242 USM_1stRrStRemindSetReq "USM_RrseatReminderSetRequest(2nd :General: CLU21/CF_Clu_1stRrSeatRemindNValueSet)";
CM_ SG_ 1242 USM_Wpc2SetReq "USM_Wpc2SetRequest";
CM_ BO_ 811 "[PE] Periodic and On Event";
CM_ SG_ 811 SBCM_AST_FD_Crc1Val "SBCM_AST_FD_CyclicRedundancyCheck1Value";
CM_ SG_ 811 SBCM_AST_FD_AlvCnt1Val "SBCM_AST_FD_AliveCounter1Value";
CM_ SG_ 811 SBCM_Longkey_ASTDrAtClsSwSta "FCS Power Door Long key Status";
CM_ SG_ 811 Hood_TypeOption_AST "E-Hood_Option Type";
CM_ SG_ 811 FrunkReleaseSwSta_SBCM_AST "FrunkReleaseState (SBCM_AST_FD to SBCM_DRV_FD) RHD Spec";
CM_ SG_ 811 FrunkInsideRelSwSta_SBCM_AST "FrunkInsideReleaseSwState (SBCM_AST_FD to SBCM_DRV_FD) RHD Spec";
CM_ SG_ 811 FrunkEmergencySwSta_SBCM_AST "FrunkEmergencySwState (SBCM_AST_FD to SBCM_DRV_FD) RHD Spec";
CM_ SG_ 811 EHL_TxInfo_SBCM_AST "Electronic hood latch status signal transfer for dual hood latch type";
CM_ SG_ 811 AST_CrashUnlockCmd "AssistCrashUnlockCommand";
CM_ SG_ 811 DoorLock_CtrlDrLkSwSta_SBCM "DoorLock_CentralDoorLockAssistSwitchStatus";
CM_ SG_ 811 DoorLock_CtrlDrUnLkSwSta_SBCM "DoorLock_CentralDoorUnLockAssistSwitchStatus";
CM_ SG_ 811 Warn_AsstDrSwSta_SBCM "Warn_AssistDoorSwitchStatus ##2G## -  - C_AstDrSw,CF_Gway_AstDrSw,Warn_AsstDrSwSta";
CM_ SG_ 811 DoorLock_AsstDrUnLkSta_SBCM "DoorLock_AssistDoorUnLockStatus ##2G## -  - C_AstUnlockState,DoorLock_AsstDrUnLkSta";
CM_ SG_ 811 AST_SEAWarn_RH "Assist SEA Warning (LHD)";
CM_ BO_ 789 "[P] Periodic";
CM_ SG_ 789 CLU_Crc20Val "CLU_CyclicRedundancyCheck20Value";
CM_ SG_ 789 CLU_AlvCnt20Val "CLU_AliveCounter20Value";
CM_ SG_ 789 CLU_SndType "CLU_SoundType";
CM_ SG_ 789 USM_AdasHDPSetReq "This signal is used for a request to set the value of USM Menus. This signal requests to change status of HDP Mode.";
CM_ BO_ 849 "[PE] Periodic and On Event";
CM_ SG_ 849 IAU_FD_Crc4Val "IAU_FD_CyclicRedundancyCheck4Value";
CM_ SG_ 849 IAU_DigitalKey2Opt "Digital Key2 Option Signal";
CM_ SG_ 849 IAU_ValetDigitalkey "Digital Key Valet Mode";
CM_ SG_ 849 IAU_DigitalKeyNumberOpt "This signal is for the digital key number type.";
CM_ SG_ 849 IAU_eSEReprogramSta "this signal is to mornitor the state of eSE reprograming.";
CM_ SG_ 849 IAU_DgtKeyGrpPrflRval2 "This signal indiactes digital key group number paired with selected profile";
CM_ SG_ 849 IAU_StartIdentifiedProfile "This signal Indicate Profile of vehicle start Identified";
CM_ SG_ 849 IAU_DigitalKeyProfileRval2 "This signal indiactes digital key number paired with selected profile";
CM_ SG_ 849 IAU_FD_AlvCnt4Val "IAU_FD_AliveCounter4Value";
CM_ SG_ 849 IAU_StartIdentifiedProfile_Ext "This signal indicate Profile of vehicle start Identified";
CM_ SG_ 849 RSPA_UWBRspaExtRngSta "RSPA remote control range of UWB";
CM_ SG_ 849 RSPA_CanFltSta "RSPA_CANErrorState";
CM_ SG_ 849 RSPA_BLESigErrSta "RSPA_RFSignalErrorState";
CM_ SG_ 849 IAU_ProfileIDRVal "This signal Indicate the Current detected Profile ID by IAU.";
CM_ SG_ 849 IAU_DigitalKeyProcessingSta "Digital Key USM settitng Process State";
CM_ SG_ 849 IAU_DigitalKeyExit "Digital Key USM setting Exit Condition";
CM_ SG_ 849 IAU_DigitalKeyEnblRVal "Digital Key Function Enable / Disable flag (Fob is required for changing flag)";
CM_ SG_ 849 IAU_OwnerPhnRegRVal "Vehicle Owner's Phone is Registered for Digital Key function";
CM_ SG_ 849 IAU_NFCCard1RegRVal "NFC Card 1 is Registered for Digital Key function";
CM_ SG_ 849 IAU_NFCCard2RegRVal "NFC Card 2 is Registered for Digital Key function";
CM_ BO_ 788 "[PE] Periodic and On Event";
CM_ SG_ 788 RWPC_FD_Crc1Val "RWPC_FD_CyclicRedundancyCheck1Value";
CM_ SG_ 788 RWPC_ResetOpSta "This signal indicates whether the reset operation has been completed or not";
CM_ SG_ 788 RWPC_FD_AlvCnt1Val "RWPC_FD_AliveCounter1Value";
CM_ SG_ 788 USM_ValCmdSta "USM_ValueCommandStatus";
CM_ SG_ 788 WPC_PhnLftWrngRWPCSta "WPC_PhoneLeftWaringRWPCStatus";
CM_ SG_ 788 USM_ValCmdStaforATS "USM_ValueCommandStatus";
CM_ SG_ 788 RWPC_SWVerMajor1 "First Word(ASCII) in RWPC S/W Ver";
CM_ SG_ 788 RWPC_SWVerMinor1 "Second Word(ASCII) in RWPC S/W Ver";
CM_ SG_ 788 RWPC_SWVerMinor2 "Third Word(ASCII) in RWPC S/W Ver";
CM_ BO_ 977 "[PE] Periodic and On Event";
CM_ SG_ 977 BDC_FD_Crc2Val "BDC_FD_CyclicRedundancyCheck2Value";
CM_ SG_ 977 BDC_FD_AlvCnt2Val "BDC_FD_AliveCounter2Value";
CM_ SG_ 977 BCM_KeyInSta "BCM_KeyInStatus ##2G##BCM - BCMmsg17 - C_KeyInSW";
CM_ SG_ 977 BCM_AccInSta "BCM_AccInputStatus ##2G##BCM - BCMmsg17 - C_Acc";
CM_ SG_ 977 BCM_Ign1InSta "BCM_Ignition1InputStatus ##2G##BCM - BCMmsg17 - C_Ign1";
CM_ SG_ 977 BCM_Ign2InSta "BCM_Ignition1InputStatus ##2G##BCM - BCMmsg17 - C_Ign2";
CM_ SG_ 977 BCM_GearPosPSta "BCM_GearPositionPStatus ##2G##BCM - BCMmsg17 - C_PpositiOn";
CM_ SG_ 977 BCM_SmkOptTyp "BCM_SmkOptionType ##2G##BCM - BCMmsg17 - C_SMKOption";
CM_ SG_ 977 BDC_ResetOpSta "This signal indicates whether the reset operation has been completed or not";
CM_ SG_ 977 IBU_SWVerMajor1 "First Word(ASCII) in IBU S/W Ver";
CM_ SG_ 977 IBU_SWVerMinor1 "Second Word(ASCII) in IBU S/W Ver";
CM_ SG_ 977 IBU_SWVerMinor2 "Third Word(ASCII) in IBU S/W Ver";
CM_ SG_ 977 BDC_PlatformVerType "BDC Platform Type Information";
CM_ SG_ 977 BDC_PlatformVerDate "BDC Platform Version Date Version Information";
CM_ BO_ 914 "[PE] Periodic and On Event";
CM_ SG_ 914 WPC2_FD_Crc1Val "WPC2_FD_CyclicRedundancyCheck1Value";
CM_ SG_ 914 WPC2_ResetOpSta "This signal indicates whether the reset operation has been completed or not";
CM_ SG_ 914 WPC2_FD_AlvCnt1Val "WPC2_FD_AliveCounter1Value";
CM_ SG_ 914 USM_CmdWPC2Sta "USM_CommandWPC2Status";
CM_ SG_ 914 WPC2_PhnLftWrngSta "WPC2_PhoneLeftWarningStatus";
CM_ SG_ 914 WPC2_SWVerMajor1 "First Word(ASCII) in WPC2 S/W Ver";
CM_ SG_ 914 WPC2_SWVerMinor1 "Second Word(ASCII) in WPC2 S/W Ver";
CM_ SG_ 914 WPC2_SWVerMinor2 "Third Word(ASCII) in WPC2 S/W Ver";
CM_ BO_ 2015 "[TP] Transport Protocol";
BA_DEF_ BO_  "CANFD_BRS" ENUM  "0","1";
BA_DEF_ BO_  "GenMsgEVName" STRING ;
BA_DEF_ BO_  "NmAsrMessage" ENUM  "No","Yes";
BA_DEF_ BO_  "DiagState" ENUM  "No","Yes";
BA_DEF_ BO_  "DiagResponse" ENUM  "No","Yes";
BA_DEF_ BO_  "DiagRequest" ENUM  "No","Yes";
BA_DEF_ BO_  "TpMessage" ENUM  "No","Yes";
BA_DEF_ BO_  "UsrMsgIDSforwardDeviation" INT 0 100;
BA_DEF_ BO_  "UsrMsgIDSbackwardDeviation" INT 50 1000;
BA_DEF_ BO_  "GenMsgCycleTime" INT 0 2000;
BA_DEF_ BO_  "GenMsgStartDelayTime" INT 0 2000;
BA_DEF_ BO_  "GenMsgSendType" ENUM  "Cyclic","NoMsgSendType";
BA_DEF_ BO_  "GenMsgCycleTimeFast" INT 0 500;
BA_DEF_ BO_  "GenMsgDelayTime" INT 0 20;
BA_DEF_ BO_  "GenMsgILSupport" ENUM  "No","Yes";
BA_DEF_ BO_  "GenMsgNrOfRepetition" INT 0 3;
BA_DEF_ BO_  "TpTxIndex" INT 0 65535;
BA_DEF_ BO_  "VFrameFormat" ENUM  "StandardCAN","ExtendedCAN","reserved","reserved","reserved","reserved","reserved","reserved","reserved","reserved","reserved","reserved","reserved","reserved","StandardCAN_FD","ExtendedCAN_FD";
BA_DEF_ SG_  "UserSigValidity" ENUM  "B+","ACC","IG","IG1","IG2","IG3","IG1 or IG2","IG1 or IG3","Undef";
BA_DEF_ SG_  "TimeoutValue" STRING ;
BA_DEF_ SG_  "UsrSigPurpose" ENUM  "Undef","FN","DIAG","DIAG(Req)","DIAG(Res)","DIAG(Func)","DEV","CCP","NM","TP";
BA_DEF_ SG_  "GenSigStartValue" INT 0 1215752192;
BA_DEF_ SG_  "NetworkRequest" ENUM  "Yes","No";
BA_DEF_ SG_  "NetworkRequestHoldingTime" INT 0 65535;
BA_DEF_ SG_  "Description" STRING ;
BA_DEF_ SG_  "Version" STRING ;
BA_DEF_ SG_  "GenSigEnvVarType" ENUM  "Int","Float","Undef";
BA_DEF_ SG_  "GenSigSendType" ENUM  "Cyclic","OnWrite","OnWriteWithRepetition","OnChange","OnChangeWithRepetition","IfActive","IfActiveWithRepetition","NoSigSendType","OnChangeAndIfActive","OnChangeAndIfActiveWithRepetition";
BA_DEF_ SG_  "GwSigLatencyTime" INT 0 65536;
BA_DEF_ SG_  "GwSigMissingSourceType" ENUM  "Undef","OldValue","DefaultValue","InitialValue";
BA_DEF_ SG_  "NWM-WakeupAllowed" ENUM  "<n.a.>";
BA_DEF_ SG_  "RoutingFactor" INT 1 1215752192;
BA_DEF_ SG_  "SystemSignalLongSymbol" STRING ;
BA_DEF_REL_ BU_SG_REL_  "GenSigTimeoutTime" INT 0 7000;
BA_DEF_DEF_  "CANFD_BRS" "1";
BA_DEF_DEF_  "GenMsgEVName" "@Signame";
BA_DEF_DEF_  "NmAsrMessage" "No";
BA_DEF_DEF_  "DiagState" "No";
BA_DEF_DEF_  "DiagResponse" "No";
BA_DEF_DEF_  "DiagRequest" "No";
BA_DEF_DEF_  "TpMessage" "No";
BA_DEF_DEF_  "UsrMsgIDSforwardDeviation" 10;
BA_DEF_DEF_  "UsrMsgIDSbackwardDeviation" 100;
BA_DEF_DEF_  "GenMsgCycleTime" 200;
BA_DEF_DEF_  "GenMsgStartDelayTime" 0;
BA_DEF_DEF_  "GenMsgSendType" "NoMsgSendType";
BA_DEF_DEF_  "GenMsgCycleTimeFast" 40;
BA_DEF_DEF_  "GenMsgDelayTime" 20;
BA_DEF_DEF_  "GenMsgILSupport" "Yes";
BA_DEF_DEF_  "GenMsgNrOfRepetition" 3;
BA_DEF_DEF_  "TpTxIndex" 0;
BA_DEF_DEF_  "VFrameFormat" "StandardCAN";
BA_DEF_DEF_  "UserSigValidity" "IG";
BA_DEF_DEF_  "TimeoutValue" "";
BA_DEF_DEF_  "UsrSigPurpose" "FN";
BA_DEF_DEF_  "GenSigStartValue" 0;
BA_DEF_DEF_  "NetworkRequest" "No";
BA_DEF_DEF_  "NetworkRequestHoldingTime" 0;
BA_DEF_DEF_  "Description" "";
BA_DEF_DEF_  "Version" "";
BA_DEF_DEF_  "GenSigEnvVarType" "Undef";
BA_DEF_DEF_  "GenSigSendType" "NoSigSendType";
BA_DEF_DEF_  "GwSigLatencyTime" 40;
BA_DEF_DEF_  "GwSigMissingSourceType" "Undef";
BA_DEF_DEF_  "NWM-WakeupAllowed" "<n.a.>";
BA_DEF_DEF_  "RoutingFactor" 1;
BA_DEF_DEF_REL_ "GenSigTimeoutTime" 500;
BA_DEF_DEF_  "SystemSignalLongSymbol" "";
BA_ "GenMsgSendType" BO_ 813 0;
BA_ "VFrameFormat" BO_ 813 14;
BA_ "GenMsgSendType" BO_ 994 0;
BA_ "VFrameFormat" BO_ 994 14;
BA_ "GenMsgCycleTime" BO_ 1242 0;
BA_ "VFrameFormat" BO_ 1242 14;
BA_ "GenMsgSendType" BO_ 811 0;
BA_ "VFrameFormat" BO_ 811 14;
BA_ "GenMsgSendType" BO_ 789 0;
BA_ "GenMsgCycleTimeFast" BO_ 789 0;
BA_ "GenMsgNrOfRepetition" BO_ 789 0;
BA_ "VFrameFormat" BO_ 789 14;
BA_ "GenMsgSendType" BO_ 849 0;
BA_ "GenMsgStartDelayTime" BO_ 849 40;
BA_ "VFrameFormat" BO_ 849 14;
BA_ "GenMsgSendType" BO_ 788 0;
BA_ "VFrameFormat" BO_ 788 14;
BA_ "GenMsgSendType" BO_ 977 0;
BA_ "VFrameFormat" BO_ 977 14;
BA_ "GenMsgSendType" BO_ 914 0;
BA_ "VFrameFormat" BO_ 914 14;
BA_ "GenMsgCycleTime" BO_ 2015 0;
BA_ "GenMsgCycleTimeFast" BO_ 2015 0;
BA_ "GenMsgNrOfRepetition" BO_ 2015 0;
BA_ "DiagState" BO_ 2015 1;
BA_ "GenMsgILSupport" BO_ 2015 0;
BA_ "TpMessage" BO_ 2015 1;
BA_ "VFrameFormat" BO_ 2015 14;
BA_ "Description" SG_ 813 SBCM_DRV_FD_Crc1Val "The data area for CRC calculation is based on the data length (DLC) of the message DB.

The CRC shall be calculated over the entire data block (excluding the CRC bytes) including the user data, alive counter and Data ID



- CRC Polynomial (0x1021) , Ini";
BA_ "GenSigSendType" SG_ 813 SBCM_DRV_FD_Crc1Val 4;
BA_ "GenSigStartValue" SG_ 813 SBCM_DRV_FD_Crc1Val 65535;
BA_ "UserSigValidity" SG_ 813 SBCM_DRV_FD_Crc1Val 3;
BA_ "Version" SG_ 813 SBCM_DRV_FD_Crc1Val "22.10.20";
BA_ "Description" SG_ 813 Latch_TypeOption_DRV "If the E-Lacth is applied, the signal will be send for identify the door lock/unlock function and option.";
BA_ "GenSigSendType" SG_ 813 Latch_TypeOption_DRV 4;
BA_ "UserSigValidity" SG_ 813 Latch_TypeOption_DRV 0;
BA_ "NetworkRequest" SG_ 813 Latch_TypeOption_DRV 0;
BA_ "Version" SG_ 813 Latch_TypeOption_DRV "21.07.07";
BA_ "GenSigSendType" SG_ 813 DRV_SWFailAlarm 4;
BA_ "UserSigValidity" SG_ 813 DRV_SWFailAlarm 0;
BA_ "NetworkRequest" SG_ 813 DRV_SWFailAlarm 0;
BA_ "NetworkRequestHoldingTime" SG_ 813 DRV_SWFailAlarm 5000;
BA_ "Version" SG_ 813 DRV_SWFailAlarm "21.07.07";
BA_ "GenSigSendType" SG_ 813 USM_PwrDRApprOpnSetSta 4;
BA_ "UserSigValidity" SG_ 813 USM_PwrDRApprOpnSetSta 0;
BA_ "NetworkRequest" SG_ 813 USM_PwrDRApprOpnSetSta 0;
BA_ "NetworkRequestHoldingTime" SG_ 813 USM_PwrDRApprOpnSetSta 5000;
BA_ "Version" SG_ 813 USM_PwrDRApprOpnSetSta "21.07.07";
BA_ "GenSigSendType" SG_ 813 USM_PwrDRApprOpnSetOpt 4;
BA_ "UserSigValidity" SG_ 813 USM_PwrDRApprOpnSetOpt 0;
BA_ "NetworkRequest" SG_ 813 USM_PwrDRApprOpnSetOpt 0;
BA_ "NetworkRequestHoldingTime" SG_ 813 USM_PwrDRApprOpnSetOpt 5000;
BA_ "Version" SG_ 813 USM_PwrDRApprOpnSetOpt "21.07.07";
BA_ "GenSigSendType" SG_ 813 USM_PwrDRCloseByRKELockSta 4;
BA_ "UserSigValidity" SG_ 813 USM_PwrDRCloseByRKELockSta 0;
BA_ "NetworkRequest" SG_ 813 USM_PwrDRCloseByRKELockSta 0;
BA_ "NetworkRequestHoldingTime" SG_ 813 USM_PwrDRCloseByRKELockSta 5000;
BA_ "Version" SG_ 813 USM_PwrDRCloseByRKELockSta "22.10.01";
BA_ "GenSigSendType" SG_ 813 USM_PwrDRCloseByRKELockOpt 4;
BA_ "UserSigValidity" SG_ 813 USM_PwrDRCloseByRKELockOpt 0;
BA_ "NetworkRequest" SG_ 813 USM_PwrDRCloseByRKELockOpt 0;
BA_ "NetworkRequestHoldingTime" SG_ 813 USM_PwrDRCloseByRKELockOpt 5000;
BA_ "Version" SG_ 813 USM_PwrDRCloseByRKELockOpt "22.10.01";
BA_ "GenSigSendType" SG_ 813 USM_PwrDRCloseByBrakeSta 4;
BA_ "UserSigValidity" SG_ 813 USM_PwrDRCloseByBrakeSta 0;
BA_ "NetworkRequest" SG_ 813 USM_PwrDRCloseByBrakeSta 0;
BA_ "NetworkRequestHoldingTime" SG_ 813 USM_PwrDRCloseByBrakeSta 5000;
BA_ "Version" SG_ 813 USM_PwrDRCloseByBrakeSta "21.07.07";
BA_ "GenSigSendType" SG_ 813 USM_PwrDRCloseByBrakeOpt 4;
BA_ "UserSigValidity" SG_ 813 USM_PwrDRCloseByBrakeOpt 0;
BA_ "NetworkRequest" SG_ 813 USM_PwrDRCloseByBrakeOpt 0;
BA_ "NetworkRequestHoldingTime" SG_ 813 USM_PwrDRCloseByBrakeOpt 5000;
BA_ "Version" SG_ 813 USM_PwrDRCloseByBrakeOpt "21.07.07";
BA_ "GenSigSendType" SG_ 813 USM_PwrDRBuzzerSta 4;
BA_ "UserSigValidity" SG_ 813 USM_PwrDRBuzzerSta 0;
BA_ "NetworkRequest" SG_ 813 USM_PwrDRBuzzerSta 0;
BA_ "NetworkRequestHoldingTime" SG_ 813 USM_PwrDRBuzzerSta 5000;
BA_ "Version" SG_ 813 USM_PwrDRBuzzerSta "21.07.07";
BA_ "GenSigSendType" SG_ 813 USM_PwrDRBuzzerOpt 4;
BA_ "UserSigValidity" SG_ 813 USM_PwrDRBuzzerOpt 0;
BA_ "NetworkRequest" SG_ 813 USM_PwrDRBuzzerOpt 0;
BA_ "NetworkRequestHoldingTime" SG_ 813 USM_PwrDRBuzzerOpt 5000;
BA_ "Version" SG_ 813 USM_PwrDRBuzzerOpt "21.07.07";
BA_ "GenSigSendType" SG_ 813 PDS_TypeOption_DRV 4;
BA_ "UserSigValidity" SG_ 813 PDS_TypeOption_DRV 0;
BA_ "NetworkRequest" SG_ 813 PDS_TypeOption_DRV 0;
BA_ "Version" SG_ 813 PDS_TypeOption_DRV "23.04.02";
BA_ "Description" SG_ 813 C_DrvDoorApproachOpen "Fob searching start and stop signal for PDS.";
BA_ "GenSigSendType" SG_ 813 C_DrvDoorApproachOpen 4;
BA_ "UserSigValidity" SG_ 813 C_DrvDoorApproachOpen 0;
BA_ "Version" SG_ 813 C_DrvDoorApproachOpen "21.07.07";
BA_ "Description" SG_ 813 C_DrvDoorApproachClose "To close the door automatically, request the fob searching signal";
BA_ "GenSigSendType" SG_ 813 C_DrvDoorApproachClose 4;
BA_ "UserSigValidity" SG_ 813 C_DrvDoorApproachClose 0;
BA_ "Version" SG_ 813 C_DrvDoorApproachClose "21.07.07";
BA_ "GenSigSendType" SG_ 813 DoorLock_PDSLkSwSta_DRV 4;
BA_ "UserSigValidity" SG_ 813 DoorLock_PDSLkSwSta_DRV 0;
BA_ "NetworkRequest" SG_ 813 DoorLock_PDSLkSwSta_DRV 0;
BA_ "Version" SG_ 813 DoorLock_PDSLkSwSta_DRV "21.07.07";
BA_ "GenSigSendType" SG_ 813 SBCM_DRV_DiagSta 4;
BA_ "UserSigValidity" SG_ 813 SBCM_DRV_DiagSta 0;
BA_ "NetworkRequest" SG_ 813 SBCM_DRV_DiagSta 0;
BA_ "NetworkRequestHoldingTime" SG_ 813 SBCM_DRV_DiagSta 5000;
BA_ "Version" SG_ 813 SBCM_DRV_DiagSta "21.07.07";
BA_ "Description" SG_ 813 DoorLock_CtrlDrLkUnLkSwSta_SBCM "Central Door Lock/Unlock Switch State";
BA_ "GenSigSendType" SG_ 813 DoorLock_CtrlDrLkUnLkSwSta_SBCM 4;
BA_ "UserSigValidity" SG_ 813 DoorLock_CtrlDrLkUnLkSwSta_SBCM 0;
BA_ "NetworkRequest" SG_ 813 DoorLock_CtrlDrLkUnLkSwSta_SBCM 0;
BA_ "NetworkRequestHoldingTime" SG_ 813 DoorLock_CtrlDrLkUnLkSwSta_SBCM 5000;
BA_ "Version" SG_ 813 DoorLock_CtrlDrLkUnLkSwSta_SBCM "21.07.07";
BA_ "GenSigSendType" SG_ 813 SBCM_PsvDrLkReq 4;
BA_ "UserSigValidity" SG_ 813 SBCM_PsvDrLkReq 0;
BA_ "NetworkRequest" SG_ 813 SBCM_PsvDrLkReq 0;
BA_ "Version" SG_ 813 SBCM_PsvDrLkReq "21.07.07";
BA_ "GenSigSendType" SG_ 813 CDMAutoWashModeSet_SBCM 4;
BA_ "UserSigValidity" SG_ 813 CDMAutoWashModeSet_SBCM 3;
BA_ "Version" SG_ 813 CDMAutoWashModeSet_SBCM "22.07.00";
BA_ "GenSigSendType" SG_ 813 USM_DrvGhostDoorSta 4;
BA_ "UserSigValidity" SG_ 813 USM_DrvGhostDoorSta 0;
BA_ "NetworkRequest" SG_ 813 USM_DrvGhostDoorSta 0;
BA_ "NetworkRequestHoldingTime" SG_ 813 USM_DrvGhostDoorSta 5000;
BA_ "Version" SG_ 813 USM_DrvGhostDoorSta "21.07.07";
BA_ "GenSigSendType" SG_ 813 Mirror_LH_FoldingSta 4;
BA_ "UserSigValidity" SG_ 813 Mirror_LH_FoldingSta 0;
BA_ "NetworkRequest" SG_ 813 Mirror_LH_FoldingSta 0;
BA_ "NetworkRequestHoldingTime" SG_ 813 Mirror_LH_FoldingSta 5000;
BA_ "Version" SG_ 813 Mirror_LH_FoldingSta "21.07.07";
BA_ "GenSigSendType" SG_ 813 Mirror_LH_UnfoldingSta 4;
BA_ "UserSigValidity" SG_ 813 Mirror_LH_UnfoldingSta 0;
BA_ "NetworkRequest" SG_ 813 Mirror_LH_UnfoldingSta 0;
BA_ "NetworkRequestHoldingTime" SG_ 813 Mirror_LH_UnfoldingSta 5000;
BA_ "Version" SG_ 813 Mirror_LH_UnfoldingSta "21.07.07";
BA_ "GenSigSendType" SG_ 813 DRV_CrashMRActAlarm 4;
BA_ "UserSigValidity" SG_ 813 DRV_CrashMRActAlarm 0;
BA_ "NetworkRequest" SG_ 813 DRV_CrashMRActAlarm 0;
BA_ "NetworkRequestHoldingTime" SG_ 813 DRV_CrashMRActAlarm 5000;
BA_ "Version" SG_ 813 DRV_CrashMRActAlarm "21.07.07";
BA_ "GenSigSendType" SG_ 813 AFH_DRV_FldUnFldSta 4;
BA_ "UserSigValidity" SG_ 813 AFH_DRV_FldUnFldSta 0;
BA_ "NetworkRequest" SG_ 813 AFH_DRV_FldUnFldSta 0;
BA_ "NetworkRequestHoldingTime" SG_ 813 AFH_DRV_FldUnFldSta 5000;
BA_ "Version" SG_ 813 AFH_DRV_FldUnFldSta "24.07.06";
BA_ "Description" SG_ 813 SBCM_DRV_FD_AlvCnt1Val "For the first transmission request for a data element the counter shall be initialized with 0 and shall be incremented by 1 for every subsequent send request. 

When the counter reaches the maximum value(0xFF), then it shall restart with 0 for the next s";
BA_ "GenSigSendType" SG_ 813 SBCM_DRV_FD_AlvCnt1Val 4;
BA_ "UserSigValidity" SG_ 813 SBCM_DRV_FD_AlvCnt1Val 3;
BA_ "Version" SG_ 813 SBCM_DRV_FD_AlvCnt1Val "22.10.20";
BA_ "GenSigSendType" SG_ 813 MirrorFldReq 4;
BA_ "UserSigValidity" SG_ 813 MirrorFldReq 0;
BA_ "NetworkRequest" SG_ 813 MirrorFldReq 0;
BA_ "NetworkRequestHoldingTime" SG_ 813 MirrorFldReq 5000;
BA_ "Version" SG_ 813 MirrorFldReq "21.07.07";
BA_ "GenSigSendType" SG_ 813 OMU_TypeOption_DRV 4;
BA_ "UserSigValidity" SG_ 813 OMU_TypeOption_DRV 0;
BA_ "NetworkRequest" SG_ 813 OMU_TypeOption_DRV 0;
BA_ "NetworkRequestHoldingTime" SG_ 813 OMU_TypeOption_DRV 5000;
BA_ "Version" SG_ 813 OMU_TypeOption_DRV "21.07.07";
BA_ "GenSigSendType" SG_ 813 IMS_OSMirPlayBackSta_LH 4;
BA_ "UserSigValidity" SG_ 813 IMS_OSMirPlayBackSta_LH 0;
BA_ "NetworkRequest" SG_ 813 IMS_OSMirPlayBackSta_LH 0;
BA_ "NetworkRequestHoldingTime" SG_ 813 IMS_OSMirPlayBackSta_LH 5000;
BA_ "Version" SG_ 813 IMS_OSMirPlayBackSta_LH "21.07.07";
BA_ "Description" SG_ 813 ECMMRR_PLUS "This signal for passenger outside mirror OEC function(or ECM)

SBCM_DRV receive the ECM voltage value via H/wiring and then send this signal to SBCM_AST";
BA_ "GenSigSendType" SG_ 813 ECMMRR_PLUS 4;
BA_ "UserSigValidity" SG_ 813 ECMMRR_PLUS 0;
BA_ "NetworkRequest" SG_ 813 ECMMRR_PLUS 0;
BA_ "NetworkRequestHoldingTime" SG_ 813 ECMMRR_PLUS 5000;
BA_ "Version" SG_ 813 ECMMRR_PLUS "21.07.07";
BA_ "Description" SG_ 813 EHL_TxInfo_SBCM_DRV "Electronic hood latch status signal transfer for dual hood latch type

(Copy to CANFD)";
BA_ "GenSigSendType" SG_ 813 EHL_TxInfo_SBCM_DRV 4;
BA_ "UserSigValidity" SG_ 813 EHL_TxInfo_SBCM_DRV 0;
BA_ "NetworkRequest" SG_ 813 EHL_TxInfo_SBCM_DRV 0;
BA_ "NetworkRequestHoldingTime" SG_ 813 EHL_TxInfo_SBCM_DRV 5000;
BA_ "Version" SG_ 813 EHL_TxInfo_SBCM_DRV "24.07.03";
BA_ "Description" SG_ 813 IMS_OSMirPlayBackSta_LH_New "Applied from standard DB 2.0";
BA_ "GenSigSendType" SG_ 813 IMS_OSMirPlayBackSta_LH_New 4;
BA_ "UserSigValidity" SG_ 813 IMS_OSMirPlayBackSta_LH_New 0;
BA_ "NetworkRequest" SG_ 813 IMS_OSMirPlayBackSta_LH_New 0;
BA_ "NetworkRequestHoldingTime" SG_ 813 IMS_OSMirPlayBackSta_LH_New 5000;
BA_ "Version" SG_ 813 IMS_OSMirPlayBackSta_LH_New "23.01.03";
BA_ "GenSigSendType" SG_ 813 CDM_InsideOpnSwSta 4;
BA_ "UserSigValidity" SG_ 813 CDM_InsideOpnSwSta 0;
BA_ "NetworkRequest" SG_ 813 CDM_InsideOpnSwSta 0;
BA_ "NetworkRequestHoldingTime" SG_ 813 CDM_InsideOpnSwSta 5000;
BA_ "Version" SG_ 813 CDM_InsideOpnSwSta "23.04.05";
BA_ "Description" SG_ 813 CDM_TypeOption "0x1 : On (CDM is applied)

0x2 : On_2EA (CDM 2EA are applied)";
BA_ "GenSigSendType" SG_ 813 CDM_TypeOption 4;
BA_ "UserSigValidity" SG_ 813 CDM_TypeOption 0;
BA_ "NetworkRequest" SG_ 813 CDM_TypeOption 0;
BA_ "NetworkRequestHoldingTime" SG_ 813 CDM_TypeOption 5000;
BA_ "Version" SG_ 813 CDM_TypeOption "23.04.02";
BA_ "Description" SG_ 813 CDM_ImmeChgSw_SBCM "State of Immediate Charging Switch";
BA_ "GenSigSendType" SG_ 813 CDM_ImmeChgSw_SBCM 4;
BA_ "UserSigValidity" SG_ 813 CDM_ImmeChgSw_SBCM 0;
BA_ "Version" SG_ 813 CDM_ImmeChgSw_SBCM "23.04.05";
BA_ "GenSigSendType" SG_ 813 CDM_FobSrchReq_DRV 4;
BA_ "UserSigValidity" SG_ 813 CDM_FobSrchReq_DRV 0;
BA_ "NetworkRequest" SG_ 813 CDM_FobSrchReq_DRV 0;
BA_ "NetworkRequestHoldingTime" SG_ 813 CDM_FobSrchReq_DRV 5000;
BA_ "Version" SG_ 813 CDM_FobSrchReq_DRV "24.05.03";
BA_ "Description" SG_ 813 CDM_OpnClsState_SBCM "This signal indicates CDM Open/Close Status";
BA_ "GenSigSendType" SG_ 813 CDM_OpnClsState_SBCM 4;
BA_ "UserSigValidity" SG_ 813 CDM_OpnClsState_SBCM 0;
BA_ "Version" SG_ 813 CDM_OpnClsState_SBCM "23.04.05";
BA_ "Description" SG_ 813 CDM_WarnMsg_SBCM "Command for CDM Warning on cluster";
BA_ "GenSigSendType" SG_ 813 CDM_WarnMsg_SBCM 4;
BA_ "UserSigValidity" SG_ 813 CDM_WarnMsg_SBCM 0;
BA_ "Version" SG_ 813 CDM_WarnMsg_SBCM "23.04.05";
BA_ "GenSigSendType" SG_ 813 CDM_AutoWashModeSta 4;
BA_ "UserSigValidity" SG_ 813 CDM_AutoWashModeSta 0;
BA_ "NetworkRequest" SG_ 813 CDM_AutoWashModeSta 0;
BA_ "NetworkRequestHoldingTime" SG_ 813 CDM_AutoWashModeSta 5000;
BA_ "Version" SG_ 813 CDM_AutoWashModeSta "22.02.00";
BA_ "Description" SG_ 813 CDM_CmdStatus_SBCM "User Condition Check For CDM Operation";
BA_ "GenSigSendType" SG_ 813 CDM_CmdStatus_SBCM 4;
BA_ "GenSigStartValue" SG_ 813 CDM_CmdStatus_SBCM 15;
BA_ "UserSigValidity" SG_ 813 CDM_CmdStatus_SBCM 0;
BA_ "Version" SG_ 813 CDM_CmdStatus_SBCM "23.04.05";
BA_ "Description" SG_ 813 CDM_OutsideOpnSwSta "Charing Dorr O/S SW State";
BA_ "GenSigSendType" SG_ 813 CDM_OutsideOpnSwSta 4;
BA_ "UserSigValidity" SG_ 813 CDM_OutsideOpnSwSta 0;
BA_ "NetworkRequest" SG_ 813 CDM_OutsideOpnSwSta 0;
BA_ "NetworkRequestHoldingTime" SG_ 813 CDM_OutsideOpnSwSta 5000;
BA_ "Version" SG_ 813 CDM_OutsideOpnSwSta "23.04.05";
BA_ "GenSigSendType" SG_ 813 PwrDRBuzzerOut_DRV 4;
BA_ "UserSigValidity" SG_ 813 PwrDRBuzzerOut_DRV 0;
BA_ "NetworkRequest" SG_ 813 PwrDRBuzzerOut_DRV 0;
BA_ "NetworkRequestHoldingTime" SG_ 813 PwrDRBuzzerOut_DRV 5000;
BA_ "Version" SG_ 813 PwrDRBuzzerOut_DRV "21.07.07";
BA_ "GenSigSendType" SG_ 813 Warn_HoodSwSta_SBCM 4;
BA_ "UserSigValidity" SG_ 813 Warn_HoodSwSta_SBCM 0;
BA_ "NetworkRequest" SG_ 813 Warn_HoodSwSta_SBCM 0;
BA_ "NetworkRequestHoldingTime" SG_ 813 Warn_HoodSwSta_SBCM 5000;
BA_ "Version" SG_ 813 Warn_HoodSwSta_SBCM "21.09.08";
BA_ "Description" SG_ 813 Hood_TypeOption "If the E-Hood is applied, the signal will be send.";
BA_ "GenSigSendType" SG_ 813 Hood_TypeOption 4;
BA_ "UserSigValidity" SG_ 813 Hood_TypeOption 0;
BA_ "NetworkRequest" SG_ 813 Hood_TypeOption 0;
BA_ "NetworkRequestHoldingTime" SG_ 813 Hood_TypeOption 5000;
BA_ "Version" SG_ 813 Hood_TypeOption "22.03.01";
BA_ "GenSigSendType" SG_ 813 SBCM_FrunkSta 4;
BA_ "UserSigValidity" SG_ 813 SBCM_FrunkSta 0;
BA_ "NetworkRequest" SG_ 813 SBCM_FrunkSta 0;
BA_ "NetworkRequestHoldingTime" SG_ 813 SBCM_FrunkSta 5000;
BA_ "Version" SG_ 813 SBCM_FrunkSta "22.01.06";
BA_ "GenSigSendType" SG_ 813 Warn_HoodSwFullSta_SBCM 4;
BA_ "UserSigValidity" SG_ 813 Warn_HoodSwFullSta_SBCM 0;
BA_ "NetworkRequest" SG_ 813 Warn_HoodSwFullSta_SBCM 0;
BA_ "NetworkRequestHoldingTime" SG_ 813 Warn_HoodSwFullSta_SBCM 5000;
BA_ "Version" SG_ 813 Warn_HoodSwFullSta_SBCM "22.01.06";
BA_ "GenSigSendType" SG_ 813 FrunkWarning_SBCM 4;
BA_ "UserSigValidity" SG_ 813 FrunkWarning_SBCM 0;
BA_ "NetworkRequest" SG_ 813 FrunkWarning_SBCM 0;
BA_ "NetworkRequestHoldingTime" SG_ 813 FrunkWarning_SBCM 5000;
BA_ "Version" SG_ 813 FrunkWarning_SBCM "22.03.01";
BA_ "Description" SG_ 813 SBCM_Longkey_DRVDrAtClsSwSta "FCS Power Door Long key Status";
BA_ "GenSigSendType" SG_ 813 SBCM_Longkey_DRVDrAtClsSwSta 4;
BA_ "UserSigValidity" SG_ 813 SBCM_Longkey_DRVDrAtClsSwSta 0;
BA_ "NetworkRequest" SG_ 813 SBCM_Longkey_DRVDrAtClsSwSta 0;
BA_ "NetworkRequestHoldingTime" SG_ 813 SBCM_Longkey_DRVDrAtClsSwSta 5000;
BA_ "Version" SG_ 813 SBCM_Longkey_DRVDrAtClsSwSta "22.04.02";
BA_ "Description" SG_ 813 FrunkReleaseSwSta_SBCM "FrunkReleaseState";
BA_ "GenSigSendType" SG_ 813 FrunkReleaseSwSta_SBCM 4;
BA_ "UserSigValidity" SG_ 813 FrunkReleaseSwSta_SBCM 0;
BA_ "NetworkRequest" SG_ 813 FrunkReleaseSwSta_SBCM 0;
BA_ "NetworkRequestHoldingTime" SG_ 813 FrunkReleaseSwSta_SBCM 50000;
BA_ "Version" SG_ 813 FrunkReleaseSwSta_SBCM "23.04.04";
BA_ "GenSigSendType" SG_ 813 PwrDRClosingDRVDrSta 4;
BA_ "UserSigValidity" SG_ 813 PwrDRClosingDRVDrSta 0;
BA_ "NetworkRequest" SG_ 813 PwrDRClosingDRVDrSta 0;
BA_ "NetworkRequestHoldingTime" SG_ 813 PwrDRClosingDRVDrSta 5000;
BA_ "Version" SG_ 813 PwrDRClosingDRVDrSta "23.10.11";
BA_ "GenSigSendType" SG_ 813 Drv_DrLkRetryFail_SBCM 4;
BA_ "TimeoutValue" SG_ 813 Drv_DrLkRetryFail_SBCM "0x0";
BA_ "UserSigValidity" SG_ 813 Drv_DrLkRetryFail_SBCM 0;
BA_ "NetworkRequest" SG_ 813 Drv_DrLkRetryFail_SBCM 0;
BA_ "NetworkRequestHoldingTime" SG_ 813 Drv_DrLkRetryFail_SBCM 5000;
BA_ "Version" SG_ 813 Drv_DrLkRetryFail_SBCM "23.03.00";
BA_ "Description" SG_ 813 CDM_GbtImmeChgSw_SBCM "State of Immediate Charging Switch";
BA_ "GenSigSendType" SG_ 813 CDM_GbtImmeChgSw_SBCM 4;
BA_ "UserSigValidity" SG_ 813 CDM_GbtImmeChgSw_SBCM 0;
BA_ "Version" SG_ 813 CDM_GbtImmeChgSw_SBCM "23.04.02";
BA_ "Description" SG_ 813 CDM_GbtOpnClsState_SBCM "This signal indicates CDM Open/Close Status(Gbt)";
BA_ "GenSigSendType" SG_ 813 CDM_GbtOpnClsState_SBCM 4;
BA_ "UserSigValidity" SG_ 813 CDM_GbtOpnClsState_SBCM 0;
BA_ "Version" SG_ 813 CDM_GbtOpnClsState_SBCM "23.04.02";
BA_ "Description" SG_ 813 CDM_GbtWarnMsg_SBCM "Command for CDM Warning on cluster(Gbt)";
BA_ "GenSigSendType" SG_ 813 CDM_GbtWarnMsg_SBCM 4;
BA_ "UserSigValidity" SG_ 813 CDM_GbtWarnMsg_SBCM 0;
BA_ "Version" SG_ 813 CDM_GbtWarnMsg_SBCM "23.04.02";
BA_ "GenSigSendType" SG_ 813 CDM_GbtOutsideOpnSwSta 4;
BA_ "UserSigValidity" SG_ 813 CDM_GbtOutsideOpnSwSta 0;
BA_ "NetworkRequest" SG_ 813 CDM_GbtOutsideOpnSwSta 0;
BA_ "NetworkRequestHoldingTime" SG_ 813 CDM_GbtOutsideOpnSwSta 5000;
BA_ "Version" SG_ 813 CDM_GbtOutsideOpnSwSta "24.01.03";
BA_ "Description" SG_ 813 DoorLock_DrvLkOutSta_SBCM "- Door Lock or Unlock Output State 

0x0 : Off (Door lock/unlock output Off state)

0x1 : On (Door lock/unlock output On state)";
BA_ "GenSigSendType" SG_ 813 DoorLock_DrvLkOutSta_SBCM 4;
BA_ "UserSigValidity" SG_ 813 DoorLock_DrvLkOutSta_SBCM 0;
BA_ "NetworkRequest" SG_ 813 DoorLock_DrvLkOutSta_SBCM 0;
BA_ "NetworkRequestHoldingTime" SG_ 813 DoorLock_DrvLkOutSta_SBCM 5000;
BA_ "Version" SG_ 813 DoorLock_DrvLkOutSta_SBCM "23.02.09";
BA_ "Description" SG_ 813 FrunkEmergencySwSta_SBCM "FrunkEmergencySwState";
BA_ "GenSigSendType" SG_ 813 FrunkEmergencySwSta_SBCM 4;
BA_ "UserSigValidity" SG_ 813 FrunkEmergencySwSta_SBCM 0;
BA_ "NetworkRequest" SG_ 813 FrunkEmergencySwSta_SBCM 0;
BA_ "NetworkRequestHoldingTime" SG_ 813 FrunkEmergencySwSta_SBCM 5000;
BA_ "Version" SG_ 813 FrunkEmergencySwSta_SBCM "23.04.04";
BA_ "GenSigSendType" SG_ 813 DRV_DetectObj_warn_LH 4;
BA_ "UserSigValidity" SG_ 813 DRV_DetectObj_warn_LH 0;
BA_ "NetworkRequest" SG_ 813 DRV_DetectObj_warn_LH 0;
BA_ "NetworkRequestHoldingTime" SG_ 813 DRV_DetectObj_warn_LH 5000;
BA_ "Version" SG_ 813 DRV_DetectObj_warn_LH "23.10.11";
BA_ "GenSigSendType" SG_ 813 PwrDROpenClosingDdvSdDRSta 4;
BA_ "UserSigValidity" SG_ 813 PwrDROpenClosingDdvSdDRSta 0;
BA_ "NetworkRequest" SG_ 813 PwrDROpenClosingDdvSdDRSta 0;
BA_ "NetworkRequestHoldingTime" SG_ 813 PwrDROpenClosingDdvSdDRSta 5000;
BA_ "Version" SG_ 813 PwrDROpenClosingDdvSdDRSta "23.10.11";
BA_ "Description" SG_ 813 PwrDRBuzzerOut_DRV_New "JG~ 적용";
BA_ "GenSigSendType" SG_ 813 PwrDRBuzzerOut_DRV_New 4;
BA_ "UserSigValidity" SG_ 813 PwrDRBuzzerOut_DRV_New 0;
BA_ "NetworkRequest" SG_ 813 PwrDRBuzzerOut_DRV_New 0;
BA_ "NetworkRequestHoldingTime" SG_ 813 PwrDRBuzzerOut_DRV_New 5000;
BA_ "Version" SG_ 813 PwrDRBuzzerOut_DRV_New "24.01.05";
BA_ "GenSigSendType" SG_ 813 Coach_TypeOption_DRV 4;
BA_ "GenSigStartValue" SG_ 813 Coach_TypeOption_DRV 3;
BA_ "UserSigValidity" SG_ 813 Coach_TypeOption_DRV 0;
BA_ "NetworkRequest" SG_ 813 Coach_TypeOption_DRV 0;
BA_ "NetworkRequestHoldingTime" SG_ 813 Coach_TypeOption_DRV 5000;
BA_ "Version" SG_ 813 Coach_TypeOption_DRV "24.01.07";
BA_ "GenSigSendType" SG_ 813 PwrDrSta_Drv 4;
BA_ "UserSigValidity" SG_ 813 PwrDrSta_Drv 0;
BA_ "NetworkRequest" SG_ 813 PwrDrSta_Drv 0;
BA_ "NetworkRequestHoldingTime" SG_ 813 PwrDrSta_Drv 5000;
BA_ "Version" SG_ 813 PwrDrSta_Drv "24.01.05";
BA_ "GenSigSendType" SG_ 813 PwrDrSta_DrvSd 4;
BA_ "UserSigValidity" SG_ 813 PwrDrSta_DrvSd 0;
BA_ "NetworkRequest" SG_ 813 PwrDrSta_DrvSd 0;
BA_ "NetworkRequestHoldingTime" SG_ 813 PwrDrSta_DrvSd 5000;
BA_ "Version" SG_ 813 PwrDrSta_DrvSd "24.01.05";
BA_ "GenSigSendType" SG_ 813 USM_PwrDrOpnTypSta 4;
BA_ "UserSigValidity" SG_ 813 USM_PwrDrOpnTypSta 0;
BA_ "NetworkRequest" SG_ 813 USM_PwrDrOpnTypSta 0;
BA_ "NetworkRequestHoldingTime" SG_ 813 USM_PwrDrOpnTypSta 5000;
BA_ "Version" SG_ 813 USM_PwrDrOpnTypSta "24.01.05";
BA_ "GenSigSendType" SG_ 813 DischrgDr_OpnClsState_SBCM 4;
BA_ "UserSigValidity" SG_ 813 DischrgDr_OpnClsState_SBCM 0;
BA_ "NetworkRequest" SG_ 813 DischrgDr_OpnClsState_SBCM 0;
BA_ "NetworkRequestHoldingTime" SG_ 813 DischrgDr_OpnClsState_SBCM 5000;
BA_ "Version" SG_ 813 DischrgDr_OpnClsState_SBCM "24.01.04";
BA_ "Description" SG_ 813 SBCM_FL_DoorAngle "PDSM_FL_DoorAngle";
BA_ "GenSigSendType" SG_ 813 SBCM_FL_DoorAngle 4;
BA_ "GenSigStartValue" SG_ 813 SBCM_FL_DoorAngle 100;
BA_ "UserSigValidity" SG_ 813 SBCM_FL_DoorAngle 0;
BA_ "NetworkRequest" SG_ 813 SBCM_FL_DoorAngle 0;
BA_ "NetworkRequestHoldingTime" SG_ 813 SBCM_FL_DoorAngle 5000;
BA_ "Version" SG_ 813 SBCM_FL_DoorAngle "24.01.05";
BA_ "Description" SG_ 813 SBCM_DoorType_DRV "SBCM Applied Type";
BA_ "GenSigSendType" SG_ 813 SBCM_DoorType_DRV 4;
BA_ "GenSigStartValue" SG_ 813 SBCM_DoorType_DRV 2;
BA_ "UserSigValidity" SG_ 813 SBCM_DoorType_DRV 0;
BA_ "NetworkRequest" SG_ 813 SBCM_DoorType_DRV 0;
BA_ "NetworkRequestHoldingTime" SG_ 813 SBCM_DoorType_DRV 5000;
BA_ "Version" SG_ 813 SBCM_DoorType_DRV "24.01.07";
BA_ "GenSigSendType" SG_ 813 CDM_DrType_DRV 4;
BA_ "UserSigValidity" SG_ 813 CDM_DrType_DRV 7;
BA_ "NetworkRequest" SG_ 813 CDM_DrType_DRV 0;
BA_ "NetworkRequestHoldingTime" SG_ 813 CDM_DrType_DRV 5000;
BA_ "Version" SG_ 813 CDM_DrType_DRV "24.05.01";
BA_ "GenSigSendType" SG_ 813 DRVDoorPushAlarm 4;
BA_ "UserSigValidity" SG_ 813 DRVDoorPushAlarm 0;
BA_ "NetworkRequest" SG_ 813 DRVDoorPushAlarm 0;
BA_ "NetworkRequestHoldingTime" SG_ 813 DRVDoorPushAlarm 5000;
BA_ "Version" SG_ 813 DRVDoorPushAlarm "21.07.07";
BA_ "Description" SG_ 813 DRV_CrashUnlockCmd "Drive Crash Unlock Command";
BA_ "GenSigSendType" SG_ 813 DRV_CrashUnlockCmd 4;
BA_ "UserSigValidity" SG_ 813 DRV_CrashUnlockCmd 0;
BA_ "NetworkRequest" SG_ 813 DRV_CrashUnlockCmd 0;
BA_ "Version" SG_ 813 DRV_CrashUnlockCmd "21.07.07";
BA_ "Description" SG_ 813 C_ApprOpenStatus "This is for Power Door System enable/disable signal.";
BA_ "GenSigSendType" SG_ 813 C_ApprOpenStatus 4;
BA_ "UserSigValidity" SG_ 813 C_ApprOpenStatus 0;
BA_ "Version" SG_ 813 C_ApprOpenStatus "21.07.07";
BA_ "Description" SG_ 813 DoorLock_DrvKeyLkSwSta_SBCM "Door Lock Driver Mechanical Key Input Signal";
BA_ "GenSigSendType" SG_ 813 DoorLock_DrvKeyLkSwSta_SBCM 4;
BA_ "UserSigValidity" SG_ 813 DoorLock_DrvKeyLkSwSta_SBCM 0;
BA_ "NetworkRequest" SG_ 813 DoorLock_DrvKeyLkSwSta_SBCM 0;
BA_ "Version" SG_ 813 DoorLock_DrvKeyLkSwSta_SBCM "21.07.07";
BA_ "Description" SG_ 813 DoorLock_DrvKeyUnLkSwSta_SBCM "Door Drive Mechanical Key Unlock Switch State";
BA_ "GenSigSendType" SG_ 813 DoorLock_DrvKeyUnLkSwSta_SBCM 4;
BA_ "UserSigValidity" SG_ 813 DoorLock_DrvKeyUnLkSwSta_SBCM 0;
BA_ "NetworkRequest" SG_ 813 DoorLock_DrvKeyUnLkSwSta_SBCM 0;
BA_ "Version" SG_ 813 DoorLock_DrvKeyUnLkSwSta_SBCM "21.07.07";
BA_ "Description" SG_ 813 Warn_DrvDrSwSta_SBCM "Warning Drive Door Switch State";
BA_ "GenSigSendType" SG_ 813 Warn_DrvDrSwSta_SBCM 4;
BA_ "UserSigValidity" SG_ 813 Warn_DrvDrSwSta_SBCM 0;
BA_ "NetworkRequest" SG_ 813 Warn_DrvDrSwSta_SBCM 0;
BA_ "Version" SG_ 813 Warn_DrvDrSwSta_SBCM "21.09.05";
BA_ "Description" SG_ 813 DoorLock_DrvDrUnLkSta_SBCM "Drive Door Lock Unlock Status";
BA_ "GenSigSendType" SG_ 813 DoorLock_DrvDrUnLkSta_SBCM 4;
BA_ "UserSigValidity" SG_ 813 DoorLock_DrvDrUnLkSta_SBCM 0;
BA_ "NetworkRequest" SG_ 813 DoorLock_DrvDrUnLkSta_SBCM 0;
BA_ "Version" SG_ 813 DoorLock_DrvDrUnLkSta_SBCM "21.09.05";
BA_ "Description" SG_ 813 DRV_SEAWarn_LH "Drive (FLH) Door SEA Warning";
BA_ "GenSigSendType" SG_ 813 DRV_SEAWarn_LH 4;
BA_ "UserSigValidity" SG_ 813 DRV_SEAWarn_LH 0;
BA_ "NetworkRequest" SG_ 813 DRV_SEAWarn_LH 0;
BA_ "Version" SG_ 813 DRV_SEAWarn_LH "21.07.07";
BA_ "Description" SG_ 813 DRV_SEAWarn_RH "Drive (FRH) Door SEA Warning";
BA_ "GenSigSendType" SG_ 813 DRV_SEAWarn_RH 4;
BA_ "UserSigValidity" SG_ 813 DRV_SEAWarn_RH 0;
BA_ "NetworkRequest" SG_ 813 DRV_SEAWarn_RH 0;
BA_ "Version" SG_ 813 DRV_SEAWarn_RH "21.07.07";
BA_ "Description" SG_ 813 DRV_SEWWarn_LH "Drive (FLH) Door Safety Exit Warning";
BA_ "GenSigSendType" SG_ 813 DRV_SEWWarn_LH 4;
BA_ "UserSigValidity" SG_ 813 DRV_SEWWarn_LH 0;
BA_ "NetworkRequest" SG_ 813 DRV_SEWWarn_LH 0;
BA_ "Version" SG_ 813 DRV_SEWWarn_LH "21.07.07";
BA_ "Description" SG_ 813 DRV_SEWWarn_RH "Drive (FRH) Door Safety Exit Warning";
BA_ "GenSigSendType" SG_ 813 DRV_SEWWarn_RH 4;
BA_ "UserSigValidity" SG_ 813 DRV_SEWWarn_RH 0;
BA_ "NetworkRequest" SG_ 813 DRV_SEWWarn_RH 0;
BA_ "Version" SG_ 813 DRV_SEWWarn_RH "21.07.07";
BA_ "GenSigSendType" SG_ 813 DRV_MRActivationAlarm 4;
BA_ "UserSigValidity" SG_ 813 DRV_MRActivationAlarm 0;
BA_ "NetworkRequest" SG_ 813 DRV_MRActivationAlarm 0;
BA_ "NetworkRequestHoldingTime" SG_ 813 DRV_MRActivationAlarm 5000;
BA_ "Version" SG_ 813 DRV_MRActivationAlarm "21.07.07";
BA_ "GenSigSendType" SG_ 813 DRV_ReleaseWarn 4;
BA_ "UserSigValidity" SG_ 813 DRV_ReleaseWarn 0;
BA_ "NetworkRequest" SG_ 813 DRV_ReleaseWarn 0;
BA_ "NetworkRequestHoldingTime" SG_ 813 DRV_ReleaseWarn 5000;
BA_ "Version" SG_ 813 DRV_ReleaseWarn "21.09.05";
BA_ "Description" SG_ 994 PDC_FD_Crc3Val "The data area for CRC calculation is based on the data length (DLC) of the message DB.

The CRC shall be calculated over the entire data block (excluding the CRC bytes) including the user data, alive counter and Data ID



- CRC Polynomial (0x1021) , Ini";
BA_ "GenSigSendType" SG_ 994 PDC_FD_Crc3Val 4;
BA_ "GenSigStartValue" SG_ 994 PDC_FD_Crc3Val 65535;
BA_ "UserSigValidity" SG_ 994 PDC_FD_Crc3Val 3;
BA_ "Version" SG_ 994 PDC_FD_Crc3Val "22.10.20";
BA_ "Description" SG_ 994 PDC_FD_AlvCnt3Val "For the first transmission request for a data element the counter shall be initialized with 0 and shall be incremented by 1 for every subsequent send request. 

When the counter reaches the maximum value(0xFF), then it shall restart with 0 for the next s";
BA_ "GenSigSendType" SG_ 994 PDC_FD_AlvCnt3Val 4;
BA_ "UserSigValidity" SG_ 994 PDC_FD_AlvCnt3Val 3;
BA_ "Version" SG_ 994 PDC_FD_AlvCnt3Val "22.10.20";
BA_ "GenSigSendType" SG_ 994 Warn_DrvDrSwSta 4;
BA_ "UserSigValidity" SG_ 994 Warn_DrvDrSwSta 0;
BA_ "NetworkRequest" SG_ 994 Warn_DrvDrSwSta 0;
BA_ "NetworkRequestHoldingTime" SG_ 994 Warn_DrvDrSwSta 5000;
BA_ "Version" SG_ 994 Warn_DrvDrSwSta "17.12.00";
BA_ "GenSigSendType" SG_ 994 Warn_AsstDrSwSta 4;
BA_ "UserSigValidity" SG_ 994 Warn_AsstDrSwSta 0;
BA_ "NetworkRequest" SG_ 994 Warn_AsstDrSwSta 0;
BA_ "NetworkRequestHoldingTime" SG_ 994 Warn_AsstDrSwSta 5000;
BA_ "Version" SG_ 994 Warn_AsstDrSwSta "17.12.00";
BA_ "GenSigSendType" SG_ 994 Warn_RrLftDrSwSta 4;
BA_ "UserSigValidity" SG_ 994 Warn_RrLftDrSwSta 0;
BA_ "NetworkRequest" SG_ 994 Warn_RrLftDrSwSta 0;
BA_ "NetworkRequestHoldingTime" SG_ 994 Warn_RrLftDrSwSta 5000;
BA_ "Version" SG_ 994 Warn_RrLftDrSwSta "17.12.00";
BA_ "GenSigSendType" SG_ 994 Warn_RrRtDrSwSta 4;
BA_ "UserSigValidity" SG_ 994 Warn_RrRtDrSwSta 0;
BA_ "NetworkRequest" SG_ 994 Warn_RrRtDrSwSta 0;
BA_ "NetworkRequestHoldingTime" SG_ 994 Warn_RrRtDrSwSta 5000;
BA_ "Version" SG_ 994 Warn_RrRtDrSwSta "17.12.00";
BA_ "GenSigSendType" SG_ 994 Warn_HoodSwSta 4;
BA_ "UserSigValidity" SG_ 994 Warn_HoodSwSta 0;
BA_ "NetworkRequest" SG_ 994 Warn_HoodSwSta 0;
BA_ "NetworkRequestHoldingTime" SG_ 994 Warn_HoodSwSta 5000;
BA_ "Version" SG_ 994 Warn_HoodSwSta "17.12.00";
BA_ "GenSigSendType" SG_ 994 DoorLock_DrvDrUnLkSta 4;
BA_ "UserSigValidity" SG_ 994 DoorLock_DrvDrUnLkSta 0;
BA_ "NetworkRequest" SG_ 994 DoorLock_DrvDrUnLkSta 0;
BA_ "NetworkRequestHoldingTime" SG_ 994 DoorLock_DrvDrUnLkSta 5000;
BA_ "Version" SG_ 994 DoorLock_DrvDrUnLkSta "21.09.05";
BA_ "GenSigSendType" SG_ 994 DoorLock_AsstDrUnLkSta 4;
BA_ "UserSigValidity" SG_ 994 DoorLock_AsstDrUnLkSta 0;
BA_ "NetworkRequest" SG_ 994 DoorLock_AsstDrUnLkSta 0;
BA_ "NetworkRequestHoldingTime" SG_ 994 DoorLock_AsstDrUnLkSta 5000;
BA_ "Version" SG_ 994 DoorLock_AsstDrUnLkSta "17.12.00";
BA_ "GenSigSendType" SG_ 994 DoorLock_RrLftDrUnLkSta 4;
BA_ "UserSigValidity" SG_ 994 DoorLock_RrLftDrUnLkSta 0;
BA_ "NetworkRequest" SG_ 994 DoorLock_RrLftDrUnLkSta 0;
BA_ "NetworkRequestHoldingTime" SG_ 994 DoorLock_RrLftDrUnLkSta 5000;
BA_ "Version" SG_ 994 DoorLock_RrLftDrUnLkSta "17.12.00";
BA_ "GenSigSendType" SG_ 994 DoorLock_RrRtDrUnLkSta 4;
BA_ "UserSigValidity" SG_ 994 DoorLock_RrRtDrUnLkSta 0;
BA_ "NetworkRequest" SG_ 994 DoorLock_RrRtDrUnLkSta 0;
BA_ "NetworkRequestHoldingTime" SG_ 994 DoorLock_RrRtDrUnLkSta 5000;
BA_ "Version" SG_ 994 DoorLock_RrRtDrUnLkSta "17.12.00";
BA_ "GenSigSendType" SG_ 994 DoorLock_DrvKeyLkSwSta 4;
BA_ "UserSigValidity" SG_ 994 DoorLock_DrvKeyLkSwSta 0;
BA_ "NetworkRequest" SG_ 994 DoorLock_DrvKeyLkSwSta 0;
BA_ "NetworkRequestHoldingTime" SG_ 994 DoorLock_DrvKeyLkSwSta 5000;
BA_ "Version" SG_ 994 DoorLock_DrvKeyLkSwSta "17.12.00";
BA_ "GenSigSendType" SG_ 994 DoorLock_DrvKeyUnLkSwSta 4;
BA_ "UserSigValidity" SG_ 994 DoorLock_DrvKeyUnLkSwSta 0;
BA_ "NetworkRequest" SG_ 994 DoorLock_DrvKeyUnLkSwSta 0;
BA_ "NetworkRequestHoldingTime" SG_ 994 DoorLock_DrvKeyUnLkSwSta 5000;
BA_ "Version" SG_ 994 DoorLock_DrvKeyUnLkSwSta "17.12.00";
BA_ "Description" SG_ 994 DoorLock_CtrlDrLkSwSta_ICU "Central Door Lock Switch State

(DRV or AST or RL or RR Door trim)";
BA_ "GenSigSendType" SG_ 994 DoorLock_CtrlDrLkSwSta_ICU 4;
BA_ "UserSigValidity" SG_ 994 DoorLock_CtrlDrLkSwSta_ICU 0;
BA_ "NetworkRequest" SG_ 994 DoorLock_CtrlDrLkSwSta_ICU 0;
BA_ "NetworkRequestHoldingTime" SG_ 994 DoorLock_CtrlDrLkSwSta_ICU 5000;
BA_ "Version" SG_ 994 DoorLock_CtrlDrLkSwSta_ICU "19.07.01";
BA_ "Description" SG_ 994 DoorLock_CtrlDrUnLkSwSta_ICU "Central Door Unlock Switch State

(DRV or AST or RL or RR Door trim)";
BA_ "GenSigSendType" SG_ 994 DoorLock_CtrlDrUnLkSwSta_ICU 4;
BA_ "UserSigValidity" SG_ 994 DoorLock_CtrlDrUnLkSwSta_ICU 0;
BA_ "NetworkRequest" SG_ 994 DoorLock_CtrlDrUnLkSwSta_ICU 0;
BA_ "NetworkRequestHoldingTime" SG_ 994 DoorLock_CtrlDrUnLkSwSta_ICU 5000;
BA_ "Version" SG_ 994 DoorLock_CtrlDrUnLkSwSta_ICU "19.07.01";
BA_ "Description" SG_ 994 DoorLock_CtrlDrLkUnLkSwSta_ICU "Central Door Lock/Unlock Switch State

(C/PAD, Integrated & self return type)";
BA_ "GenSigSendType" SG_ 994 DoorLock_CtrlDrLkUnLkSwSta_ICU 4;
BA_ "UserSigValidity" SG_ 994 DoorLock_CtrlDrLkUnLkSwSta_ICU 0;
BA_ "NetworkRequest" SG_ 994 DoorLock_CtrlDrLkUnLkSwSta_ICU 0;
BA_ "NetworkRequestHoldingTime" SG_ 994 DoorLock_CtrlDrLkUnLkSwSta_ICU 5000;
BA_ "Version" SG_ 994 DoorLock_CtrlDrLkUnLkSwSta_ICU "19.07.01";
BA_ "Description" SG_ 994 C_CrashUnlockState "Crash Unlock Active State

-0x0:Off

-0x1:Unlock(crash)";
BA_ "GenSigSendType" SG_ 994 C_CrashUnlockState 4;
BA_ "UserSigValidity" SG_ 994 C_CrashUnlockState 0;
BA_ "NetworkRequest" SG_ 994 C_CrashUnlockState 0;
BA_ "Version" SG_ 994 C_CrashUnlockState "21.07.05";
BA_ "Description" SG_ 994 Lamp_LedHdLmpSta "This signal is LED headlamp status inform whether LED fail or not which is regulation of ECE, Domestic.



If LED H/Lamp detects LED failure then a cluster shall be turn on to 'LED' indicator in the display panel and It should be to display the words 'Ch";
BA_ "GenSigSendType" SG_ 994 Lamp_LedHdLmpSta 4;
BA_ "UserSigValidity" SG_ 994 Lamp_LedHdLmpSta 3;
BA_ "NetworkRequest" SG_ 994 Lamp_LedHdLmpSta 0;
BA_ "NetworkRequestHoldingTime" SG_ 994 Lamp_LedHdLmpSta 5000;
BA_ "Version" SG_ 994 Lamp_LedHdLmpSta "21.11.00";
BA_ "Description" SG_ 994 Warn_ChaDrSwFrtSta "Front Charging Door Open Switch";
BA_ "GenSigSendType" SG_ 994 Warn_ChaDrSwFrtSta 4;
BA_ "UserSigValidity" SG_ 994 Warn_ChaDrSwFrtSta 7;
BA_ "Version" SG_ 994 Warn_ChaDrSwFrtSta "18.08.12";
BA_ "Description" SG_ 994 Warn_ChaDrSwRrSta "Rear Charging Door Open Switch";
BA_ "GenSigSendType" SG_ 994 Warn_ChaDrSwRrSta 4;
BA_ "UserSigValidity" SG_ 994 Warn_ChaDrSwRrSta 7;
BA_ "Version" SG_ 994 Warn_ChaDrSwRrSta "18.08.12";
BA_ "Description" SG_ 1242 CLU_Crc9Val "The data area for CRC calculation is based on the data length (DLC) of the message DB.

The CRC shall be calculated over the entire data block (excluding the CRC bytes) including the user data, alive counter and Data ID



- CRC Polynomial (0x1021) , Ini";
BA_ "GenSigSendType" SG_ 1242 CLU_Crc9Val 4;
BA_ "GenSigStartValue" SG_ 1242 CLU_Crc9Val 65535;
BA_ "UserSigValidity" SG_ 1242 CLU_Crc9Val 3;
BA_ "Version" SG_ 1242 CLU_Crc9Val "21.09.03";
BA_ "Description" SG_ 1242 CLU_AlvCnt9Val "For the first transmission request for a data element the counter shall be initialized with 0 and shall be incremented by 1 for every subsequent send request. 

When the counter reaches the maximum value(0xFF), then it shall restart with 0 for the next s";
BA_ "GenSigSendType" SG_ 1242 CLU_AlvCnt9Val 4;
BA_ "UserSigValidity" SG_ 1242 CLU_AlvCnt9Val 3;
BA_ "Version" SG_ 1242 CLU_AlvCnt9Val "21.09.03";
BA_ "Description" SG_ 1242 USM_MdLmpClrSetReq "Request set the Mood Lamp Color";
BA_ "GenSigSendType" SG_ 1242 USM_MdLmpClrSetReq 4;
BA_ "UserSigValidity" SG_ 1242 USM_MdLmpClrSetReq 3;
BA_ "Version" SG_ 1242 USM_MdLmpClrSetReq "20.08.06";
BA_ "Description" SG_ 1242 USM_RrWiperRevSetReq "Request to set RearWiper Reverse Mode";
BA_ "GenSigSendType" SG_ 1242 USM_RrWiperRevSetReq 4;
BA_ "UserSigValidity" SG_ 1242 USM_RrWiperRevSetReq 3;
BA_ "Version" SG_ 1242 USM_RrWiperRevSetReq "17.11.00";
BA_ "Description" SG_ 1242 USM_RrStRemindSetReq "USM Function for RearSeatReminder on/off SW";
BA_ "GenSigSendType" SG_ 1242 USM_RrStRemindSetReq 4;
BA_ "UserSigValidity" SG_ 1242 USM_RrStRemindSetReq 3;
BA_ "Version" SG_ 1242 USM_RrStRemindSetReq "19.01.04";
BA_ "Description" SG_ 1242 USM_RrWpcSetReq "USM Function for REAR WPC(Wireless Phone Chager) on/off SW";
BA_ "GenSigSendType" SG_ 1242 USM_RrWpcSetReq 4;
BA_ "UserSigValidity" SG_ 1242 USM_RrWpcSetReq 3;
BA_ "Version" SG_ 1242 USM_RrWpcSetReq "17.11.00";
BA_ "Description" SG_ 1242 USM_WpcSetReq "USM Function for WPC(Wireless Phone Chager) on/off SW";
BA_ "GenSigSendType" SG_ 1242 USM_WpcSetReq 4;
BA_ "UserSigValidity" SG_ 1242 USM_WpcSetReq 3;
BA_ "Version" SG_ 1242 USM_WpcSetReq "17.11.00";
BA_ "Description" SG_ 1242 USM_SeqLmpSetReq "This signal is used for a request to set the value of USM Menus. This signal requests to change status of SequencialLamp ON/OFF setting.





When this signal change, the message (CLU18) is sent 3 times.";
BA_ "GenSigSendType" SG_ 1242 USM_SeqLmpSetReq 4;
BA_ "UserSigValidity" SG_ 1242 USM_SeqLmpSetReq 3;
BA_ "Version" SG_ 1242 USM_SeqLmpSetReq "17.11.00";
BA_ "Description" SG_ 1242 USM_UnlckWlcmSetReq "This signal is used for a request to set the value of USM Menus. This signal requests to change status of Welcome System setting.





When this signal change, the message (CLU18) is sent 3 times.";
BA_ "GenSigSendType" SG_ 1242 USM_UnlckWlcmSetReq 4;
BA_ "UserSigValidity" SG_ 1242 USM_UnlckWlcmSetReq 3;
BA_ "Version" SG_ 1242 USM_UnlckWlcmSetReq "17.11.00";
BA_ "Description" SG_ 1242 USM_SmrtWlcmSetReq "This signal is used for a request to set the value of USM Menus. This signal requests to change status of Welcome System setting.





When this signal change, the message (CLU18) is sent 3 times.";
BA_ "GenSigSendType" SG_ 1242 USM_SmrtWlcmSetReq 4;
BA_ "UserSigValidity" SG_ 1242 USM_SmrtWlcmSetReq 3;
BA_ "Version" SG_ 1242 USM_SmrtWlcmSetReq "17.11.00";
BA_ "Description" SG_ 1242 USM_UipSetReq "Request to set Uip(Ultrasonic Intrusion Protection)

This signal is used for a request to set the value of USM Menus. 

When this signal change, the message is sent 3 times.";
BA_ "GenSigSendType" SG_ 1242 USM_UipSetReq 4;
BA_ "UserSigValidity" SG_ 1242 USM_UipSetReq 3;
BA_ "Version" SG_ 1242 USM_UipSetReq "18.11.07";
BA_ "Description" SG_ 1242 USM_DigitalKeyEnblSetReq "This signal is used for a request to set the value of USM Menus. This signal requests to set Digital Key On/Off.";
BA_ "GenSigSendType" SG_ 1242 USM_DigitalKeyEnblSetReq 4;
BA_ "UserSigValidity" SG_ 1242 USM_DigitalKeyEnblSetReq 3;
BA_ "Version" SG_ 1242 USM_DigitalKeyEnblSetReq "18.11.00";
BA_ "Description" SG_ 1242 USM_OwnerPhnRegSetReq "This signal is used for a request to set the value of USM Menus.

This signal requests to set Digital Key On/Off";
BA_ "GenSigSendType" SG_ 1242 USM_OwnerPhnRegSetReq 4;
BA_ "UserSigValidity" SG_ 1242 USM_OwnerPhnRegSetReq 3;
BA_ "Version" SG_ 1242 USM_OwnerPhnRegSetReq "18.11.00";
BA_ "Description" SG_ 1242 USM_NFCCard1RegSetReq "This signal is used for a request to set the value of USM Menus. This signal requests to go through the process for NFC Card 1 recoding.";
BA_ "GenSigSendType" SG_ 1242 USM_NFCCard1RegSetReq 4;
BA_ "UserSigValidity" SG_ 1242 USM_NFCCard1RegSetReq 3;
BA_ "Version" SG_ 1242 USM_NFCCard1RegSetReq "18.11.00";
BA_ "Description" SG_ 1242 USM_NFCCard2RegSetReq "This signal is used for arequest to set the value of usm menus.

This signal requests to go through the process NFC Card 2 recording";
BA_ "GenSigSendType" SG_ 1242 USM_NFCCard2RegSetReq 4;
BA_ "UserSigValidity" SG_ 1242 USM_NFCCard2RegSetReq 3;
BA_ "Version" SG_ 1242 USM_NFCCard2RegSetReq "18.11.00";
BA_ "Description" SG_ 1242 USM_ProcStpReq "This signal is used for a request to escape the IAU Authorizaton processing";
BA_ "GenSigSendType" SG_ 1242 USM_ProcStpReq 4;
BA_ "UserSigValidity" SG_ 1242 USM_ProcStpReq 3;
BA_ "Version" SG_ 1242 USM_ProcStpReq "18.11.00";
BA_ "Description" SG_ 1242 USM_PwrAutoOffTimeSetReq "This signal is used for a request to set the value of USM Menus. This signal requests to change status of Power auto off time setting.";
BA_ "GenSigSendType" SG_ 1242 USM_PwrAutoOffTimeSetReq 4;
BA_ "UserSigValidity" SG_ 1242 USM_PwrAutoOffTimeSetReq 3;
BA_ "Version" SG_ 1242 USM_PwrAutoOffTimeSetReq "18.12.02";
BA_ "Description" SG_ 1242 USM_RrStRemindSetReq_RestMode "This is a signal for Rear Seat remind USM 

Request to set  Restmod of Rear Seat remind";
BA_ "GenSigSendType" SG_ 1242 USM_RrStRemindSetReq_RestMode 4;
BA_ "UserSigValidity" SG_ 1242 USM_RrStRemindSetReq_RestMode 3;
BA_ "Version" SG_ 1242 USM_RrStRemindSetReq_RestMode "19.09.04";
BA_ "Description" SG_ 1242 USM_1stRrStRemindSetReq "USM Function for RearSeatReminder on/off SW for IBU only Type";
BA_ "GenSigSendType" SG_ 1242 USM_1stRrStRemindSetReq 4;
BA_ "UserSigValidity" SG_ 1242 USM_1stRrStRemindSetReq 3;
BA_ "Version" SG_ 1242 USM_1stRrStRemindSetReq "20.02.06";
BA_ "Description" SG_ 1242 USM_Wpc2SetReq "USM Function for WPC(Wireless Phone Chager) on/off SW";
BA_ "GenSigSendType" SG_ 1242 USM_Wpc2SetReq 4;
BA_ "UserSigValidity" SG_ 1242 USM_Wpc2SetReq 3;
BA_ "Version" SG_ 1242 USM_Wpc2SetReq "22.02.06";
BA_ "Description" SG_ 811 SBCM_AST_FD_Crc1Val "The data area for CRC calculation is based on the data length (DLC) of the message DB.

The CRC shall be calculated over the entire data block (excluding the CRC bytes) including the user data, alive counter and Data ID



- CRC Polynomial (0x1021) , Ini";
BA_ "GenSigSendType" SG_ 811 SBCM_AST_FD_Crc1Val 4;
BA_ "GenSigStartValue" SG_ 811 SBCM_AST_FD_Crc1Val 65535;
BA_ "UserSigValidity" SG_ 811 SBCM_AST_FD_Crc1Val 3;
BA_ "Version" SG_ 811 SBCM_AST_FD_Crc1Val "22.10.20";
BA_ "GenSigSendType" SG_ 811 USM_AstGhostDoorSta 4;
BA_ "UserSigValidity" SG_ 811 USM_AstGhostDoorSta 0;
BA_ "NetworkRequest" SG_ 811 USM_AstGhostDoorSta 0;
BA_ "NetworkRequestHoldingTime" SG_ 811 USM_AstGhostDoorSta 5000;
BA_ "Version" SG_ 811 USM_AstGhostDoorSta "21.07.07";
BA_ "GenSigSendType" SG_ 811 AST_SWFailAlarm 4;
BA_ "UserSigValidity" SG_ 811 AST_SWFailAlarm 0;
BA_ "NetworkRequest" SG_ 811 AST_SWFailAlarm 0;
BA_ "NetworkRequestHoldingTime" SG_ 811 AST_SWFailAlarm 5000;
BA_ "Version" SG_ 811 AST_SWFailAlarm "21.07.07";
BA_ "GenSigSendType" SG_ 811 DoorLock_PDSLkSwSta_AST 4;
BA_ "UserSigValidity" SG_ 811 DoorLock_PDSLkSwSta_AST 0;
BA_ "NetworkRequest" SG_ 811 DoorLock_PDSLkSwSta_AST 0;
BA_ "Version" SG_ 811 DoorLock_PDSLkSwSta_AST "21.09.05";
BA_ "GenSigSendType" SG_ 811 PDS_TypeOption_AST 4;
BA_ "UserSigValidity" SG_ 811 PDS_TypeOption_AST 0;
BA_ "NetworkRequest" SG_ 811 PDS_TypeOption_AST 0;
BA_ "Version" SG_ 811 PDS_TypeOption_AST "21.07.07";
BA_ "GenSigSendType" SG_ 811 AFCU_AutoWashModeSta_SBCM_AST 4;
BA_ "UserSigValidity" SG_ 811 AFCU_AutoWashModeSta_SBCM_AST 0;
BA_ "NetworkRequest" SG_ 811 AFCU_AutoWashModeSta_SBCM_AST 0;
BA_ "NetworkRequestHoldingTime" SG_ 811 AFCU_AutoWashModeSta_SBCM_AST 5000;
BA_ "Version" SG_ 811 AFCU_AutoWashModeSta_SBCM_AST "22.07.00";
BA_ "GenSigSendType" SG_ 811 CDM_AutoWashModeSta_SBCM_AST 4;
BA_ "UserSigValidity" SG_ 811 CDM_AutoWashModeSta_SBCM_AST 0;
BA_ "NetworkRequest" SG_ 811 CDM_AutoWashModeSta_SBCM_AST 0;
BA_ "NetworkRequestHoldingTime" SG_ 811 CDM_AutoWashModeSta_SBCM_AST 5000;
BA_ "Version" SG_ 811 CDM_AutoWashModeSta_SBCM_AST "22.07.00";
BA_ "GenSigSendType" SG_ 811 AFH_AST_FldUnFldSta 4;
BA_ "UserSigValidity" SG_ 811 AFH_AST_FldUnFldSta 0;
BA_ "NetworkRequest" SG_ 811 AFH_AST_FldUnFldSta 0;
BA_ "NetworkRequestHoldingTime" SG_ 811 AFH_AST_FldUnFldSta 5000;
BA_ "Version" SG_ 811 AFH_AST_FldUnFldSta "24.07.06";
BA_ "GenSigSendType" SG_ 811 SBCM_AST_DiagSta 4;
BA_ "UserSigValidity" SG_ 811 SBCM_AST_DiagSta 0;
BA_ "NetworkRequest" SG_ 811 SBCM_AST_DiagSta 0;
BA_ "NetworkRequestHoldingTime" SG_ 811 SBCM_AST_DiagSta 5000;
BA_ "Version" SG_ 811 SBCM_AST_DiagSta "21.07.07";
BA_ "GenSigSendType" SG_ 811 CDM_TypeOption_AST 4;
BA_ "UserSigValidity" SG_ 811 CDM_TypeOption_AST 7;
BA_ "NetworkRequest" SG_ 811 CDM_TypeOption_AST 0;
BA_ "NetworkRequestHoldingTime" SG_ 811 CDM_TypeOption_AST 5000;
BA_ "Version" SG_ 811 CDM_TypeOption_AST "24.07.03";
BA_ "GenSigSendType" SG_ 811 CDM_ImmeChgSw_AST 4;
BA_ "UserSigValidity" SG_ 811 CDM_ImmeChgSw_AST 7;
BA_ "NetworkRequest" SG_ 811 CDM_ImmeChgSw_AST 0;
BA_ "NetworkRequestHoldingTime" SG_ 811 CDM_ImmeChgSw_AST 5000;
BA_ "Version" SG_ 811 CDM_ImmeChgSw_AST "21.07.07";
BA_ "GenSigSendType" SG_ 811 CDM_FobSrchReq_AST 4;
BA_ "UserSigValidity" SG_ 811 CDM_FobSrchReq_AST 0;
BA_ "NetworkRequest" SG_ 811 CDM_FobSrchReq_AST 0;
BA_ "NetworkRequestHoldingTime" SG_ 811 CDM_FobSrchReq_AST 5000;
BA_ "Version" SG_ 811 CDM_FobSrchReq_AST "24.05.03";
BA_ "GenSigSendType" SG_ 811 CDM_OpnClsState_AST 4;
BA_ "UserSigValidity" SG_ 811 CDM_OpnClsState_AST 7;
BA_ "NetworkRequest" SG_ 811 CDM_OpnClsState_AST 0;
BA_ "NetworkRequestHoldingTime" SG_ 811 CDM_OpnClsState_AST 5000;
BA_ "Version" SG_ 811 CDM_OpnClsState_AST "21.07.07";
BA_ "GenSigSendType" SG_ 811 CDM_WarnMsg_AST 4;
BA_ "UserSigValidity" SG_ 811 CDM_WarnMsg_AST 7;
BA_ "NetworkRequest" SG_ 811 CDM_WarnMsg_AST 0;
BA_ "NetworkRequestHoldingTime" SG_ 811 CDM_WarnMsg_AST 5000;
BA_ "Version" SG_ 811 CDM_WarnMsg_AST "21.07.07";
BA_ "GenSigSendType" SG_ 811 Mirror_RH_FoldingSta 4;
BA_ "UserSigValidity" SG_ 811 Mirror_RH_FoldingSta 0;
BA_ "NetworkRequest" SG_ 811 Mirror_RH_FoldingSta 0;
BA_ "NetworkRequestHoldingTime" SG_ 811 Mirror_RH_FoldingSta 5000;
BA_ "Version" SG_ 811 Mirror_RH_FoldingSta "21.07.07";
BA_ "GenSigSendType" SG_ 811 Mirror_RH_UnfoldingSta 4;
BA_ "UserSigValidity" SG_ 811 Mirror_RH_UnfoldingSta 0;
BA_ "NetworkRequest" SG_ 811 Mirror_RH_UnfoldingSta 0;
BA_ "NetworkRequestHoldingTime" SG_ 811 Mirror_RH_UnfoldingSta 5000;
BA_ "Version" SG_ 811 Mirror_RH_UnfoldingSta "21.07.07";
BA_ "GenSigSendType" SG_ 811 CDM_CmdStatus_AST 4;
BA_ "GenSigStartValue" SG_ 811 CDM_CmdStatus_AST 15;
BA_ "UserSigValidity" SG_ 811 CDM_CmdStatus_AST 7;
BA_ "NetworkRequest" SG_ 811 CDM_CmdStatus_AST 0;
BA_ "NetworkRequestHoldingTime" SG_ 811 CDM_CmdStatus_AST 5000;
BA_ "Version" SG_ 811 CDM_CmdStatus_AST "22.08.03";
BA_ "Description" SG_ 811 SBCM_AST_FD_AlvCnt1Val "For the first transmission request for a data element the counter shall be initialized with 0 and shall be incremented by 1 for every subsequent send request. 

When the counter reaches the maximum value(0xFF), then it shall restart with 0 for the next s";
BA_ "GenSigSendType" SG_ 811 SBCM_AST_FD_AlvCnt1Val 4;
BA_ "UserSigValidity" SG_ 811 SBCM_AST_FD_AlvCnt1Val 3;
BA_ "Version" SG_ 811 SBCM_AST_FD_AlvCnt1Val "22.10.20";
BA_ "GenSigSendType" SG_ 811 AST_CrashMRActAlarm 4;
BA_ "UserSigValidity" SG_ 811 AST_CrashMRActAlarm 0;
BA_ "NetworkRequest" SG_ 811 AST_CrashMRActAlarm 0;
BA_ "NetworkRequestHoldingTime" SG_ 811 AST_CrashMRActAlarm 5000;
BA_ "Version" SG_ 811 AST_CrashMRActAlarm "21.07.07";
BA_ "GenSigSendType" SG_ 811 PwrDRBuzzerOut_AST 4;
BA_ "UserSigValidity" SG_ 811 PwrDRBuzzerOut_AST 0;
BA_ "NetworkRequest" SG_ 811 PwrDRBuzzerOut_AST 0;
BA_ "NetworkRequestHoldingTime" SG_ 811 PwrDRBuzzerOut_AST 5000;
BA_ "Version" SG_ 811 PwrDRBuzzerOut_AST "21.07.07";
BA_ "GenSigSendType" SG_ 811 IMS_OSMirPlayBackSta_RH 4;
BA_ "UserSigValidity" SG_ 811 IMS_OSMirPlayBackSta_RH 0;
BA_ "NetworkRequest" SG_ 811 IMS_OSMirPlayBackSta_RH 0;
BA_ "NetworkRequestHoldingTime" SG_ 811 IMS_OSMirPlayBackSta_RH 5000;
BA_ "Version" SG_ 811 IMS_OSMirPlayBackSta_RH "21.07.07";
BA_ "GenSigSendType" SG_ 811 PwrDRClosingASTDrSta 4;
BA_ "UserSigValidity" SG_ 811 PwrDRClosingASTDrSta 0;
BA_ "NetworkRequest" SG_ 811 PwrDRClosingASTDrSta 0;
BA_ "NetworkRequestHoldingTime" SG_ 811 PwrDRClosingASTDrSta 5000;
BA_ "Version" SG_ 811 PwrDRClosingASTDrSta "23.07.06";
BA_ "Description" SG_ 811 CDM_OutsideOpnSwSta_AST "Charging Door O/S SW State";
BA_ "GenSigSendType" SG_ 811 CDM_OutsideOpnSwSta_AST 4;
BA_ "UserSigValidity" SG_ 811 CDM_OutsideOpnSwSta_AST 7;
BA_ "NetworkRequest" SG_ 811 CDM_OutsideOpnSwSta_AST 0;
BA_ "NetworkRequestHoldingTime" SG_ 811 CDM_OutsideOpnSwSta_AST 5000;
BA_ "Version" SG_ 811 CDM_OutsideOpnSwSta_AST "23.02.02";
BA_ "GenSigSendType" SG_ 811 SBCM_Longkey_ASTDrAtClsSwSta 4;
BA_ "UserSigValidity" SG_ 811 SBCM_Longkey_ASTDrAtClsSwSta 0;
BA_ "NetworkRequest" SG_ 811 SBCM_Longkey_ASTDrAtClsSwSta 0;
BA_ "NetworkRequestHoldingTime" SG_ 811 SBCM_Longkey_ASTDrAtClsSwSta 5000;
BA_ "Version" SG_ 811 SBCM_Longkey_ASTDrAtClsSwSta "22.04.02";
BA_ "Description" SG_ 811 Hood_TypeOption_AST "If the E-Hood is applied, the signal will be send.

Frunk signal from SBCM_AST to SBCM_DRV (RHD specification)";
BA_ "GenSigSendType" SG_ 811 Hood_TypeOption_AST 4;
BA_ "UserSigValidity" SG_ 811 Hood_TypeOption_AST 0;
BA_ "NetworkRequest" SG_ 811 Hood_TypeOption_AST 0;
BA_ "NetworkRequestHoldingTime" SG_ 811 Hood_TypeOption_AST 5000;
BA_ "Version" SG_ 811 Hood_TypeOption_AST "22.10.19";
BA_ "Description" SG_ 811 Warn_HoodSwSta_AST "Frunk signal from SBCM_AST to SBCM_DRV (RHD specification)";
BA_ "GenSigSendType" SG_ 811 Warn_HoodSwSta_AST 4;
BA_ "UserSigValidity" SG_ 811 Warn_HoodSwSta_AST 0;
BA_ "NetworkRequest" SG_ 811 Warn_HoodSwSta_AST 0;
BA_ "NetworkRequestHoldingTime" SG_ 811 Warn_HoodSwSta_AST 5000;
BA_ "Version" SG_ 811 Warn_HoodSwSta_AST "22.10.19";
BA_ "Description" SG_ 811 FrunkWarning_AST "Frunk signal from SBCM_AST to SBCM_DRV (RHD specification)";
BA_ "GenSigSendType" SG_ 811 FrunkWarning_AST 4;
BA_ "UserSigValidity" SG_ 811 FrunkWarning_AST 0;
BA_ "NetworkRequest" SG_ 811 FrunkWarning_AST 0;
BA_ "NetworkRequestHoldingTime" SG_ 811 FrunkWarning_AST 5000;
BA_ "Version" SG_ 811 FrunkWarning_AST "22.10.19";
BA_ "Description" SG_ 811 SBCM_FrunkSta_AST "Frunk signal from SBCM_AST to SBCM_DRV (RHD specification)";
BA_ "GenSigSendType" SG_ 811 SBCM_FrunkSta_AST 4;
BA_ "UserSigValidity" SG_ 811 SBCM_FrunkSta_AST 0;
BA_ "NetworkRequest" SG_ 811 SBCM_FrunkSta_AST 0;
BA_ "NetworkRequestHoldingTime" SG_ 811 SBCM_FrunkSta_AST 5000;
BA_ "Version" SG_ 811 SBCM_FrunkSta_AST "22.10.19";
BA_ "Description" SG_ 811 IMS_OSMirPlayBackSta_RH_New "Applied from standard DB 2.0";
BA_ "GenSigSendType" SG_ 811 IMS_OSMirPlayBackSta_RH_New 4;
BA_ "UserSigValidity" SG_ 811 IMS_OSMirPlayBackSta_RH_New 0;
BA_ "NetworkRequest" SG_ 811 IMS_OSMirPlayBackSta_RH_New 0;
BA_ "NetworkRequestHoldingTime" SG_ 811 IMS_OSMirPlayBackSta_RH_New 5000;
BA_ "Version" SG_ 811 IMS_OSMirPlayBackSta_RH_New "23.01.03";
BA_ "GenSigSendType" SG_ 811 Ast_DrLkRetryFail_SBCM 4;
BA_ "TimeoutValue" SG_ 811 Ast_DrLkRetryFail_SBCM "0x0";
BA_ "UserSigValidity" SG_ 811 Ast_DrLkRetryFail_SBCM 0;
BA_ "NetworkRequest" SG_ 811 Ast_DrLkRetryFail_SBCM 0;
BA_ "NetworkRequestHoldingTime" SG_ 811 Ast_DrLkRetryFail_SBCM 5000;
BA_ "Version" SG_ 811 Ast_DrLkRetryFail_SBCM "23.03.00";
BA_ "Description" SG_ 811 DoorLock_AstLkOutSta_SBCM "- Door Lock or Unlock Output State 

0x0 : Off (Door lock/unlock output Off state)

0x1 : On (Door lock/unlock output On state)";
BA_ "GenSigSendType" SG_ 811 DoorLock_AstLkOutSta_SBCM 4;
BA_ "UserSigValidity" SG_ 811 DoorLock_AstLkOutSta_SBCM 0;
BA_ "NetworkRequest" SG_ 811 DoorLock_AstLkOutSta_SBCM 0;
BA_ "NetworkRequestHoldingTime" SG_ 811 DoorLock_AstLkOutSta_SBCM 5000;
BA_ "Version" SG_ 811 DoorLock_AstLkOutSta_SBCM "23.02.09";
BA_ "Description" SG_ 811 FrunkReleaseSwSta_SBCM_AST "FrunkReleaseState (SBCM_AST_FD to SBCM_DRV_FD) RHD Spec";
BA_ "GenSigSendType" SG_ 811 FrunkReleaseSwSta_SBCM_AST 4;
BA_ "UserSigValidity" SG_ 811 FrunkReleaseSwSta_SBCM_AST 0;
BA_ "NetworkRequest" SG_ 811 FrunkReleaseSwSta_SBCM_AST 0;
BA_ "NetworkRequestHoldingTime" SG_ 811 FrunkReleaseSwSta_SBCM_AST 5000;
BA_ "Version" SG_ 811 FrunkReleaseSwSta_SBCM_AST "23.03.01";
BA_ "Description" SG_ 811 FrunkInsideRelSwSta_SBCM_AST "FrunkInsideReleaseSwState (SBCM_AST_FD to SBCM_DRV_FD) RHD Spec";
BA_ "GenSigSendType" SG_ 811 FrunkInsideRelSwSta_SBCM_AST 4;
BA_ "UserSigValidity" SG_ 811 FrunkInsideRelSwSta_SBCM_AST 0;
BA_ "NetworkRequest" SG_ 811 FrunkInsideRelSwSta_SBCM_AST 0;
BA_ "NetworkRequestHoldingTime" SG_ 811 FrunkInsideRelSwSta_SBCM_AST 5000;
BA_ "Version" SG_ 811 FrunkInsideRelSwSta_SBCM_AST "23.03.01";
BA_ "Description" SG_ 811 FrunkEmergencySwSta_SBCM_AST "FrunkEmergencySwState (SBCM_AST_FD to SBCM_DRV_FD) RHD Spec";
BA_ "GenSigSendType" SG_ 811 FrunkEmergencySwSta_SBCM_AST 4;
BA_ "UserSigValidity" SG_ 811 FrunkEmergencySwSta_SBCM_AST 0;
BA_ "NetworkRequest" SG_ 811 FrunkEmergencySwSta_SBCM_AST 0;
BA_ "NetworkRequestHoldingTime" SG_ 811 FrunkEmergencySwSta_SBCM_AST 5000;
BA_ "Version" SG_ 811 FrunkEmergencySwSta_SBCM_AST "23.03.01";
BA_ "GenSigSendType" SG_ 811 PwrDrSta_Ast 4;
BA_ "UserSigValidity" SG_ 811 PwrDrSta_Ast 0;
BA_ "NetworkRequest" SG_ 811 PwrDrSta_Ast 0;
BA_ "NetworkRequestHoldingTime" SG_ 811 PwrDrSta_Ast 5000;
BA_ "Version" SG_ 811 PwrDrSta_Ast "24.01.05";
BA_ "GenSigSendType" SG_ 811 PwrDrSta_AstSd 4;
BA_ "UserSigValidity" SG_ 811 PwrDrSta_AstSd 0;
BA_ "NetworkRequest" SG_ 811 PwrDrSta_AstSd 0;
BA_ "NetworkRequestHoldingTime" SG_ 811 PwrDrSta_AstSd 5000;
BA_ "Version" SG_ 811 PwrDrSta_AstSd "24.01.05";
BA_ "GenSigSendType" SG_ 811 DischrgDr_OpnClsState_SBCM_AST 4;
BA_ "UserSigValidity" SG_ 811 DischrgDr_OpnClsState_SBCM_AST 0;
BA_ "NetworkRequest" SG_ 811 DischrgDr_OpnClsState_SBCM_AST 0;
BA_ "NetworkRequestHoldingTime" SG_ 811 DischrgDr_OpnClsState_SBCM_AST 5000;
BA_ "Version" SG_ 811 DischrgDr_OpnClsState_SBCM_AST "24.07.03";
BA_ "GenSigSendType" SG_ 811 AST_DetectObj_warn_LH 4;
BA_ "UserSigValidity" SG_ 811 AST_DetectObj_warn_LH 0;
BA_ "NetworkRequest" SG_ 811 AST_DetectObj_warn_LH 0;
BA_ "NetworkRequestHoldingTime" SG_ 811 AST_DetectObj_warn_LH 5000;
BA_ "Version" SG_ 811 AST_DetectObj_warn_LH "23.10.11";
BA_ "GenSigSendType" SG_ 811 PwrDROpenClosingAstSdDRSta 4;
BA_ "UserSigValidity" SG_ 811 PwrDROpenClosingAstSdDRSta 0;
BA_ "NetworkRequest" SG_ 811 PwrDROpenClosingAstSdDRSta 0;
BA_ "NetworkRequestHoldingTime" SG_ 811 PwrDROpenClosingAstSdDRSta 5000;
BA_ "Version" SG_ 811 PwrDROpenClosingAstSdDRSta "23.10.11";
BA_ "Description" SG_ 811 PwrDRBuzzerOut_AST_New "JG~";
BA_ "GenSigSendType" SG_ 811 PwrDRBuzzerOut_AST_New 4;
BA_ "UserSigValidity" SG_ 811 PwrDRBuzzerOut_AST_New 0;
BA_ "NetworkRequest" SG_ 811 PwrDRBuzzerOut_AST_New 0;
BA_ "NetworkRequestHoldingTime" SG_ 811 PwrDRBuzzerOut_AST_New 5000;
BA_ "Version" SG_ 811 PwrDRBuzzerOut_AST_New "24.01.05";
BA_ "Description" SG_ 811 SBCM_FR_DoorAngle "PDSM_FR_DoorAngle";
BA_ "GenSigSendType" SG_ 811 SBCM_FR_DoorAngle 4;
BA_ "GenSigStartValue" SG_ 811 SBCM_FR_DoorAngle 100;
BA_ "UserSigValidity" SG_ 811 SBCM_FR_DoorAngle 0;
BA_ "NetworkRequest" SG_ 811 SBCM_FR_DoorAngle 0;
BA_ "NetworkRequestHoldingTime" SG_ 811 SBCM_FR_DoorAngle 5000;
BA_ "Version" SG_ 811 SBCM_FR_DoorAngle "24.01.05";
BA_ "Description" SG_ 811 EHL_TxInfo_SBCM_AST "Electronic hood latch status signal transfer for dual hood latch type";
BA_ "GenSigSendType" SG_ 811 EHL_TxInfo_SBCM_AST 4;
BA_ "UserSigValidity" SG_ 811 EHL_TxInfo_SBCM_AST 0;
BA_ "NetworkRequest" SG_ 811 EHL_TxInfo_SBCM_AST 0;
BA_ "NetworkRequestHoldingTime" SG_ 811 EHL_TxInfo_SBCM_AST 5000;
BA_ "Version" SG_ 811 EHL_TxInfo_SBCM_AST "24.07.03";
BA_ "GenSigSendType" SG_ 811 CDM_DrType_AST 4;
BA_ "UserSigValidity" SG_ 811 CDM_DrType_AST 7;
BA_ "NetworkRequest" SG_ 811 CDM_DrType_AST 0;
BA_ "NetworkRequestHoldingTime" SG_ 811 CDM_DrType_AST 5000;
BA_ "Version" SG_ 811 CDM_DrType_AST "24.05.01";
BA_ "GenSigSendType" SG_ 811 ASTDoorPushAlarm 4;
BA_ "UserSigValidity" SG_ 811 ASTDoorPushAlarm 0;
BA_ "NetworkRequest" SG_ 811 ASTDoorPushAlarm 0;
BA_ "NetworkRequestHoldingTime" SG_ 811 ASTDoorPushAlarm 5000;
BA_ "Version" SG_ 811 ASTDoorPushAlarm "21.07.07";
BA_ "Description" SG_ 811 AST_CrashUnlockCmd "Assist Crash Unlock Command";
BA_ "GenSigSendType" SG_ 811 AST_CrashUnlockCmd 4;
BA_ "UserSigValidity" SG_ 811 AST_CrashUnlockCmd 0;
BA_ "NetworkRequest" SG_ 811 AST_CrashUnlockCmd 0;
BA_ "Version" SG_ 811 AST_CrashUnlockCmd "21.07.07";
BA_ "Description" SG_ 811 DoorLock_CtrlDrLkSwSta_SBCM "Central Door Lock Assist Switch Status";
BA_ "GenSigSendType" SG_ 811 DoorLock_CtrlDrLkSwSta_SBCM 4;
BA_ "UserSigValidity" SG_ 811 DoorLock_CtrlDrLkSwSta_SBCM 0;
BA_ "NetworkRequest" SG_ 811 DoorLock_CtrlDrLkSwSta_SBCM 0;
BA_ "Version" SG_ 811 DoorLock_CtrlDrLkSwSta_SBCM "21.07.07";
BA_ "Description" SG_ 811 DoorLock_CtrlDrUnLkSwSta_SBCM "Central Door Unlock Assist Switch Status";
BA_ "GenSigSendType" SG_ 811 DoorLock_CtrlDrUnLkSwSta_SBCM 4;
BA_ "UserSigValidity" SG_ 811 DoorLock_CtrlDrUnLkSwSta_SBCM 0;
BA_ "NetworkRequest" SG_ 811 DoorLock_CtrlDrUnLkSwSta_SBCM 0;
BA_ "Version" SG_ 811 DoorLock_CtrlDrUnLkSwSta_SBCM "21.07.07";
BA_ "Description" SG_ 811 Warn_AsstDrSwSta_SBCM "Warning Assist Door Switch Status";
BA_ "GenSigSendType" SG_ 811 Warn_AsstDrSwSta_SBCM 4;
BA_ "UserSigValidity" SG_ 811 Warn_AsstDrSwSta_SBCM 0;
BA_ "NetworkRequest" SG_ 811 Warn_AsstDrSwSta_SBCM 0;
BA_ "Version" SG_ 811 Warn_AsstDrSwSta_SBCM "21.09.05";
BA_ "Description" SG_ 811 DoorLock_AsstDrUnLkSta_SBCM "Assist Door Unlock Status";
BA_ "GenSigSendType" SG_ 811 DoorLock_AsstDrUnLkSta_SBCM 4;
BA_ "UserSigValidity" SG_ 811 DoorLock_AsstDrUnLkSta_SBCM 0;
BA_ "NetworkRequest" SG_ 811 DoorLock_AsstDrUnLkSta_SBCM 0;
BA_ "Version" SG_ 811 DoorLock_AsstDrUnLkSta_SBCM "21.07.07";
BA_ "Description" SG_ 811 AST_SEAWarn_RH "Assist (FRH) SEA Warning";
BA_ "GenSigSendType" SG_ 811 AST_SEAWarn_RH 4;
BA_ "UserSigValidity" SG_ 811 AST_SEAWarn_RH 0;
BA_ "NetworkRequest" SG_ 811 AST_SEAWarn_RH 0;
BA_ "Version" SG_ 811 AST_SEAWarn_RH "21.07.07";
BA_ "Description" SG_ 811 AST_SEAWarn_LH "Assist (FLH) Door SEA Warning";
BA_ "GenSigSendType" SG_ 811 AST_SEAWarn_LH 4;
BA_ "UserSigValidity" SG_ 811 AST_SEAWarn_LH 0;
BA_ "NetworkRequest" SG_ 811 AST_SEAWarn_LH 0;
BA_ "Version" SG_ 811 AST_SEAWarn_LH "21.07.07";
BA_ "GenSigSendType" SG_ 811 AST_SEWWarn_LH 4;
BA_ "UserSigValidity" SG_ 811 AST_SEWWarn_LH 0;
BA_ "NetworkRequest" SG_ 811 AST_SEWWarn_LH 0;
BA_ "Version" SG_ 811 AST_SEWWarn_LH "21.07.07";
BA_ "GenSigSendType" SG_ 811 AST_SEWWarn_RH 4;
BA_ "UserSigValidity" SG_ 811 AST_SEWWarn_RH 0;
BA_ "NetworkRequest" SG_ 811 AST_SEWWarn_RH 0;
BA_ "Version" SG_ 811 AST_SEWWarn_RH "21.07.07";
BA_ "GenSigSendType" SG_ 811 AST_MRActivationAlarm 4;
BA_ "UserSigValidity" SG_ 811 AST_MRActivationAlarm 0;
BA_ "NetworkRequest" SG_ 811 AST_MRActivationAlarm 0;
BA_ "NetworkRequestHoldingTime" SG_ 811 AST_MRActivationAlarm 5000;
BA_ "Version" SG_ 811 AST_MRActivationAlarm "21.07.07";
BA_ "GenSigSendType" SG_ 811 AST_ReleaseWarn 4;
BA_ "UserSigValidity" SG_ 811 AST_ReleaseWarn 0;
BA_ "NetworkRequest" SG_ 811 AST_ReleaseWarn 0;
BA_ "NetworkRequestHoldingTime" SG_ 811 AST_ReleaseWarn 5000;
BA_ "Version" SG_ 811 AST_ReleaseWarn "21.09.05";
BA_ "Description" SG_ 789 CLU_Crc20Val "The data area for CRC calculation is based on the data length (DLC) of the message DB.

The CRC shall be calculated over the entire data block (excluding the CRC bytes) including the user data, alive counter and Data ID



- CRC Polynomial (0x1021) , Ini";
BA_ "GenSigStartValue" SG_ 789 CLU_Crc20Val 65535;
BA_ "UserSigValidity" SG_ 789 CLU_Crc20Val 3;
BA_ "Version" SG_ 789 CLU_Crc20Val "21.09.03";
BA_ "Description" SG_ 789 CLU_AlvCnt20Val "For the first transmission request for a data element the counter shall be initialized with 0 and shall be incremented by 1 for every subsequent send request. 

When the counter reaches the maximum value(0xFF), then it shall restart with 0 for the next s";
BA_ "UserSigValidity" SG_ 789 CLU_AlvCnt20Val 3;
BA_ "Version" SG_ 789 CLU_AlvCnt20Val "21.09.03";
BA_ "Description" SG_ 789 CLU_SndType "This signal is for sound type of Cluster.

The Cluster applied buzzer is can generate only on channel sound

and the Cluster applied speaker can generate multi channel sound.";
BA_ "UserSigValidity" SG_ 789 CLU_SndType 3;
BA_ "Version" SG_ 789 CLU_SndType "19.01.08";
BA_ "UserSigValidity" SG_ 789 USM_AdasHDPSetReq 3;
BA_ "Version" SG_ 789 USM_AdasHDPSetReq "23.02.02";
BA_ "Description" SG_ 789 CLU_ClusterUSM "USM application of Cluster

If USM is applied in Cluster, Signal send 0x1";
BA_ "UserSigValidity" SG_ 789 CLU_ClusterUSM 3;
BA_ "Version" SG_ 789 CLU_ClusterUSM "20.06.05";
BA_ "Description" SG_ 849 IAU_FD_Crc4Val "The data area for CRC calculation is based on the data length (DLC) of the message DB.

The CRC shall be calculated over the entire data block (excluding the CRC bytes) including the user data, alive counter and Data ID



- CRC Polynomial (0x1021) , Ini";
BA_ "GenSigSendType" SG_ 849 IAU_FD_Crc4Val 4;
BA_ "GenSigStartValue" SG_ 849 IAU_FD_Crc4Val 65535;
BA_ "UserSigValidity" SG_ 849 IAU_FD_Crc4Val 0;
BA_ "Version" SG_ 849 IAU_FD_Crc4Val "22.11.04";
BA_ "Description" SG_ 849 IAU_DISPWrng "This siganl warning from IAU

- 0x9 (WPCNFC_PreStartAuth_Success) : CLU display when workaround or LPCD Start Auth succeeded (before SSB pressed).";
BA_ "GenSigSendType" SG_ 849 IAU_DISPWrng 4;
BA_ "UserSigValidity" SG_ 849 IAU_DISPWrng 0;
BA_ "NetworkRequest" SG_ 849 IAU_DISPWrng 0;
BA_ "NetworkRequestHoldingTime" SG_ 849 IAU_DISPWrng 5000;
BA_ "Version" SG_ 849 IAU_DISPWrng "22.06.04";
BA_ "Description" SG_ 849 IAU_DigitalKey2Opt "This signal describe Digital Key capability";
BA_ "GenSigSendType" SG_ 849 IAU_DigitalKey2Opt 4;
BA_ "UserSigValidity" SG_ 849 IAU_DigitalKey2Opt 0;
BA_ "NetworkRequest" SG_ 849 IAU_DigitalKey2Opt 0;
BA_ "NetworkRequestHoldingTime" SG_ 849 IAU_DigitalKey2Opt 5000;
BA_ "Version" SG_ 849 IAU_DigitalKey2Opt "20.08.00";
BA_ "Description" SG_ 849 IAUwFRULearnState "This signal indicates learning process stste between IAU and FRU";
BA_ "GenSigSendType" SG_ 849 IAUwFRULearnState 4;
BA_ "UserSigValidity" SG_ 849 IAUwFRULearnState 0;
BA_ "NetworkRequest" SG_ 849 IAUwFRULearnState 0;
BA_ "NetworkRequestHoldingTime" SG_ 849 IAUwFRULearnState 5000;
BA_ "Version" SG_ 849 IAUwFRULearnState "20.04.05";
BA_ "Description" SG_ 849 IAUwFPMLearnState "This signal indicates learning process stste between IAU and FPM";
BA_ "GenSigSendType" SG_ 849 IAUwFPMLearnState 4;
BA_ "UserSigValidity" SG_ 849 IAUwFPMLearnState 0;
BA_ "NetworkRequest" SG_ 849 IAUwFPMLearnState 0;
BA_ "NetworkRequestHoldingTime" SG_ 849 IAUwFPMLearnState 5000;
BA_ "Version" SG_ 849 IAUwFPMLearnState "20.04.05";
BA_ "GenSigSendType" SG_ 849 IAU_ValetDigitalkey 4;
BA_ "UserSigValidity" SG_ 849 IAU_ValetDigitalkey 0;
BA_ "NetworkRequest" SG_ 849 IAU_ValetDigitalkey 0;
BA_ "NetworkRequestHoldingTime" SG_ 849 IAU_ValetDigitalkey 5000;
BA_ "Version" SG_ 849 IAU_ValetDigitalkey "20.08.05";
BA_ "Description" SG_ 849 IAU_DigitalKeyNumberOpt "This signal is for the digital key number type. 

(Ex. Max 16 of digital keys in total can be saved and shared)";
BA_ "GenSigSendType" SG_ 849 IAU_DigitalKeyNumberOpt 4;
BA_ "UserSigValidity" SG_ 849 IAU_DigitalKeyNumberOpt 0;
BA_ "NetworkRequest" SG_ 849 IAU_DigitalKeyNumberOpt 0;
BA_ "NetworkRequestHoldingTime" SG_ 849 IAU_DigitalKeyNumberOpt 5000;
BA_ "Version" SG_ 849 IAU_DigitalKeyNumberOpt "23.04.04";
BA_ "Description" SG_ 849 IAU_eSEReprogramSta "eSE Reprograming Status";
BA_ "GenSigSendType" SG_ 849 IAU_eSEReprogramSta 4;
BA_ "TimeoutValue" SG_ 849 IAU_eSEReprogramSta "0";
BA_ "UserSigValidity" SG_ 849 IAU_eSEReprogramSta 0;
BA_ "NetworkRequest" SG_ 849 IAU_eSEReprogramSta 0;
BA_ "NetworkRequestHoldingTime" SG_ 849 IAU_eSEReprogramSta 5000;
BA_ "Version" SG_ 849 IAU_eSEReprogramSta "22.07.04";
BA_ "Description" SG_ 849 IAU_DKOwnerSwapOption "Digital key owner swap option signal";
BA_ "GenSigSendType" SG_ 849 IAU_DKOwnerSwapOption 4;
BA_ "UserSigValidity" SG_ 849 IAU_DKOwnerSwapOption 0;
BA_ "Version" SG_ 849 IAU_DKOwnerSwapOption "24.01.04";
BA_ "Description" SG_ 849 IAU_DgtKeyGrpPrflRval2 "Digital Key Group number(max : 16 )";
BA_ "GenSigSendType" SG_ 849 IAU_DgtKeyGrpPrflRval2 4;
BA_ "UserSigValidity" SG_ 849 IAU_DgtKeyGrpPrflRval2 0;
BA_ "NetworkRequest" SG_ 849 IAU_DgtKeyGrpPrflRval2 0;
BA_ "NetworkRequestHoldingTime" SG_ 849 IAU_DgtKeyGrpPrflRval2 5000;
BA_ "Version" SG_ 849 IAU_DgtKeyGrpPrflRval2 "23.02.13";
BA_ "GenSigSendType" SG_ 849 IAU_StartIdentifiedProfile 4;
BA_ "TimeoutValue" SG_ 849 IAU_StartIdentifiedProfile "0x0";
BA_ "UserSigValidity" SG_ 849 IAU_StartIdentifiedProfile 0;
BA_ "NetworkRequest" SG_ 849 IAU_StartIdentifiedProfile 0;
BA_ "NetworkRequestHoldingTime" SG_ 849 IAU_StartIdentifiedProfile 5000;
BA_ "Version" SG_ 849 IAU_StartIdentifiedProfile "20.05.02";
BA_ "Description" SG_ 849 IAU_DigitalKeyProfileRval2 "digital key number : max. 16";
BA_ "GenSigSendType" SG_ 849 IAU_DigitalKeyProfileRval2 4;
BA_ "UserSigValidity" SG_ 849 IAU_DigitalKeyProfileRval2 0;
BA_ "NetworkRequest" SG_ 849 IAU_DigitalKeyProfileRval2 0;
BA_ "NetworkRequestHoldingTime" SG_ 849 IAU_DigitalKeyProfileRval2 5000;
BA_ "Version" SG_ 849 IAU_DigitalKeyProfileRval2 "22.05.04";
BA_ "GenSigSendType" SG_ 849 IAU_NFCCard1SN 4;
BA_ "UserSigValidity" SG_ 849 IAU_NFCCard1SN 0;
BA_ "NetworkRequest" SG_ 849 IAU_NFCCard1SN 0;
BA_ "NetworkRequestHoldingTime" SG_ 849 IAU_NFCCard1SN 5000;
BA_ "Version" SG_ 849 IAU_NFCCard1SN "21.07.05";
BA_ "Description" SG_ 849 IAU_FD_AlvCnt4Val "For the first transmission request for a data element the counter shall be initialized with 0 and shall be incremented by 1 for every subsequent send request. 

When the counter reaches the maximum value(0xFF), then it shall restart with 0 for the next s";
BA_ "GenSigSendType" SG_ 849 IAU_FD_AlvCnt4Val 4;
BA_ "UserSigValidity" SG_ 849 IAU_FD_AlvCnt4Val 0;
BA_ "Version" SG_ 849 IAU_FD_AlvCnt4Val "22.11.04";
BA_ "GenSigSendType" SG_ 849 IAU_StartIdentifiedProfile_Ext 4;
BA_ "UserSigValidity" SG_ 849 IAU_StartIdentifiedProfile_Ext 0;
BA_ "NetworkRequest" SG_ 849 IAU_StartIdentifiedProfile_Ext 0;
BA_ "NetworkRequestHoldingTime" SG_ 849 IAU_StartIdentifiedProfile_Ext 5000;
BA_ "Version" SG_ 849 IAU_StartIdentifiedProfile_Ext "23.04.04";
BA_ "GenSigSendType" SG_ 849 RSPA_UWBRspaExtRngSta 4;
BA_ "UserSigValidity" SG_ 849 RSPA_UWBRspaExtRngSta 0;
BA_ "NetworkRequest" SG_ 849 RSPA_UWBRspaExtRngSta 0;
BA_ "NetworkRequestHoldingTime" SG_ 849 RSPA_UWBRspaExtRngSta 5000;
BA_ "Version" SG_ 849 RSPA_UWBRspaExtRngSta "20.03.05";
BA_ "Description" SG_ 849 RSPA_CanFltSta "Error status of RSPA control signals.";
BA_ "GenSigSendType" SG_ 849 RSPA_CanFltSta 4;
BA_ "UserSigValidity" SG_ 849 RSPA_CanFltSta 0;
BA_ "Version" SG_ 849 RSPA_CanFltSta "20.02.00";
BA_ "Description" SG_ 849 RSPA_BLESigErrSta "Error status of Digital Key BLE_BtnReq signal.



If BLE frame data from Digital Key defferent with CAN signal data, 

RSPA_BLESigErrSta signal send 0x1 Signal Invalid.";
BA_ "GenSigSendType" SG_ 849 RSPA_BLESigErrSta 4;
BA_ "UserSigValidity" SG_ 849 RSPA_BLESigErrSta 0;
BA_ "NetworkRequest" SG_ 849 RSPA_BLESigErrSta 0;
BA_ "NetworkRequestHoldingTime" SG_ 849 RSPA_BLESigErrSta 5000;
BA_ "Version" SG_ 849 RSPA_BLESigErrSta "20.02.00";
BA_ "Description" SG_ 849 RSPA_ConStat "Connection Status among RSPA, IAU, BLE and SmartPhone";
BA_ "GenSigSendType" SG_ 849 RSPA_ConStat 4;
BA_ "UserSigValidity" SG_ 849 RSPA_ConStat 0;
BA_ "NetworkRequest" SG_ 849 RSPA_ConStat 0;
BA_ "NetworkRequestHoldingTime" SG_ 849 RSPA_ConStat 5000;
BA_ "Version" SG_ 849 RSPA_ConStat "20.02.00";
BA_ "GenSigSendType" SG_ 849 IAU_ProfileIDRVal 4;
BA_ "UserSigValidity" SG_ 849 IAU_ProfileIDRVal 0;
BA_ "NetworkRequest" SG_ 849 IAU_ProfileIDRVal 0;
BA_ "NetworkRequestHoldingTime" SG_ 849 IAU_ProfileIDRVal 5000;
BA_ "Version" SG_ 849 IAU_ProfileIDRVal "23.02.02";
BA_ "GenSigSendType" SG_ 849 IAU_DigitalKeyProcessingSta 4;
BA_ "UserSigValidity" SG_ 849 IAU_DigitalKeyProcessingSta 3;
BA_ "NetworkRequest" SG_ 849 IAU_DigitalKeyProcessingSta 0;
BA_ "NetworkRequestHoldingTime" SG_ 849 IAU_DigitalKeyProcessingSta 5000;
BA_ "Version" SG_ 849 IAU_DigitalKeyProcessingSta "23.02.13";
BA_ "Description" SG_ 849 IAU_DigitalKeyExit "Digital Key USM setting Exit Condition";
BA_ "GenSigSendType" SG_ 849 IAU_DigitalKeyExit 4;
BA_ "UserSigValidity" SG_ 849 IAU_DigitalKeyExit 3;
BA_ "NetworkRequest" SG_ 849 IAU_DigitalKeyExit 0;
BA_ "NetworkRequestHoldingTime" SG_ 849 IAU_DigitalKeyExit 5000;
BA_ "Version" SG_ 849 IAU_DigitalKeyExit "23.07.03";
BA_ "GenSigSendType" SG_ 849 IAU_DigitalKeyEnblRVal 4;
BA_ "UserSigValidity" SG_ 849 IAU_DigitalKeyEnblRVal 0;
BA_ "NetworkRequest" SG_ 849 IAU_DigitalKeyEnblRVal 0;
BA_ "NetworkRequestHoldingTime" SG_ 849 IAU_DigitalKeyEnblRVal 5000;
BA_ "Version" SG_ 849 IAU_DigitalKeyEnblRVal "20.05.02";
BA_ "GenSigSendType" SG_ 849 IAU_OwnerPhnRegRVal 4;
BA_ "UserSigValidity" SG_ 849 IAU_OwnerPhnRegRVal 0;
BA_ "NetworkRequest" SG_ 849 IAU_OwnerPhnRegRVal 0;
BA_ "NetworkRequestHoldingTime" SG_ 849 IAU_OwnerPhnRegRVal 5000;
BA_ "Version" SG_ 849 IAU_OwnerPhnRegRVal "20.05.02";
BA_ "GenSigSendType" SG_ 849 IAU_NFCCard1RegRVal 4;
BA_ "UserSigValidity" SG_ 849 IAU_NFCCard1RegRVal 0;
BA_ "NetworkRequest" SG_ 849 IAU_NFCCard1RegRVal 0;
BA_ "NetworkRequestHoldingTime" SG_ 849 IAU_NFCCard1RegRVal 5000;
BA_ "Version" SG_ 849 IAU_NFCCard1RegRVal "17.12.08";
BA_ "GenSigSendType" SG_ 849 IAU_NFCCard2RegRVal 4;
BA_ "UserSigValidity" SG_ 849 IAU_NFCCard2RegRVal 0;
BA_ "NetworkRequest" SG_ 849 IAU_NFCCard2RegRVal 0;
BA_ "NetworkRequestHoldingTime" SG_ 849 IAU_NFCCard2RegRVal 5000;
BA_ "Version" SG_ 849 IAU_NFCCard2RegRVal "17.12.08";
BA_ "Description" SG_ 788 RWPC_FD_Crc1Val "The data area for CRC calculation is based on the data length (DLC) of the message DB.

The CRC shall be calculated over the entire data block (excluding the CRC bytes) including the user data, alive counter and Data ID



- CRC Polynomial (0x1021) , Ini";
BA_ "GenSigSendType" SG_ 788 RWPC_FD_Crc1Val 4;
BA_ "GenSigStartValue" SG_ 788 RWPC_FD_Crc1Val 65535;
BA_ "UserSigValidity" SG_ 788 RWPC_FD_Crc1Val 3;
BA_ "Version" SG_ 788 RWPC_FD_Crc1Val "22.10.20";
BA_ "Description" SG_ 788 RWPC_IndSyncVal "WPC IND ANIVATION SYNC SIGNAL";
BA_ "GenSigSendType" SG_ 788 RWPC_IndSyncVal 4;
BA_ "TimeoutValue" SG_ 788 RWPC_IndSyncVal "0x0";
BA_ "UserSigValidity" SG_ 788 RWPC_IndSyncVal 3;
BA_ "Version" SG_ 788 RWPC_IndSyncVal "22.04.01";
BA_ "Description" SG_ 788 RWPC_ResetOpSta "This signal indicates whether the reset operation has been completed or not";
BA_ "GenSigSendType" SG_ 788 RWPC_ResetOpSta 4;
BA_ "UserSigValidity" SG_ 788 RWPC_ResetOpSta 0;
BA_ "Version" SG_ 788 RWPC_ResetOpSta "24.05.01";
BA_ "Description" SG_ 788 RWPC_FD_AlvCnt1Val "For the first transmission request for a data element the counter shall be initialized with 0 and shall be incremented by 1 for every subsequent send request. 

When the counter reaches the maximum value(0xFF), then it shall restart with 0 for the next s";
BA_ "GenSigSendType" SG_ 788 RWPC_FD_AlvCnt1Val 4;
BA_ "UserSigValidity" SG_ 788 RWPC_FD_AlvCnt1Val 3;
BA_ "Version" SG_ 788 RWPC_FD_AlvCnt1Val "22.10.20";
BA_ "Description" SG_ 788 USM_ValCmdSta "USM request value of RWPC";
BA_ "GenSigSendType" SG_ 788 USM_ValCmdSta 4;
BA_ "UserSigValidity" SG_ 788 USM_ValCmdSta 0;
BA_ "NetworkRequest" SG_ 788 USM_ValCmdSta 0;
BA_ "NetworkRequestHoldingTime" SG_ 788 USM_ValCmdSta 5000;
BA_ "Version" SG_ 788 USM_ValCmdSta "17.11.00";
BA_ "Description" SG_ 788 WPC_PhnLftWrngRWPCSta "Warning by RWPC for User (Phone left in vehicle)";
BA_ "GenSigSendType" SG_ 788 WPC_PhnLftWrngRWPCSta 4;
BA_ "UserSigValidity" SG_ 788 WPC_PhnLftWrngRWPCSta 0;
BA_ "NetworkRequest" SG_ 788 WPC_PhnLftWrngRWPCSta 0;
BA_ "NetworkRequestHoldingTime" SG_ 788 WPC_PhnLftWrngRWPCSta 5000;
BA_ "Version" SG_ 788 WPC_PhnLftWrngRWPCSta "24.01.00";
BA_ "Description" SG_ 788 USM_ValCmdStaforATS "USM request value of RWPC for ATS";
BA_ "GenSigSendType" SG_ 788 USM_ValCmdStaforATS 4;
BA_ "UserSigValidity" SG_ 788 USM_ValCmdStaforATS 0;
BA_ "NetworkRequest" SG_ 788 USM_ValCmdStaforATS 0;
BA_ "NetworkRequestHoldingTime" SG_ 788 USM_ValCmdStaforATS 5000;
BA_ "Version" SG_ 788 USM_ValCmdStaforATS "20.07.05";
BA_ "Description" SG_ 788 RWPC_SWVerMajor1 "Indicate the RWPC software version as follows:

- The software version is displayed in three digits.

- The Major and Minor digits are separated by '.'

- Signal values are transmitted to ASCII codes.



※ Example

RWPC_SWVerMajor1 : 0x41 (HEX) -> ASCII";
BA_ "GenSigSendType" SG_ 788 RWPC_SWVerMajor1 4;
BA_ "UserSigValidity" SG_ 788 RWPC_SWVerMajor1 0;
BA_ "Version" SG_ 788 RWPC_SWVerMajor1 "21.07.00";
BA_ "Description" SG_ 788 RWPC_SWVerMinor1 "Indicate the RWPC software version as follows:

- The software version is displayed in three digits.

- The Major and Minor digits are separated by '.'

- Signal values are transmitted to ASCII codes.



※ Example

RWPC_SWVerMajor1 : 0x41 (HEX) -> ASCII";
BA_ "GenSigSendType" SG_ 788 RWPC_SWVerMinor1 4;
BA_ "UserSigValidity" SG_ 788 RWPC_SWVerMinor1 0;
BA_ "Version" SG_ 788 RWPC_SWVerMinor1 "18.10.06";
BA_ "Description" SG_ 788 RWPC_SWVerMinor2 "Indicate the RWPC software version as follows:

- The software version is displayed in three digits.

- The Major and Minor digits are separated by '.'

- Signal values are transmitted to ASCII codes.



※ Example

RWPC_SWVerMajor1 : 0x41 (HEX) -> ASCII";
BA_ "GenSigSendType" SG_ 788 RWPC_SWVerMinor2 4;
BA_ "UserSigValidity" SG_ 788 RWPC_SWVerMinor2 0;
BA_ "Version" SG_ 788 RWPC_SWVerMinor2 "18.10.06";
BA_ "Description" SG_ 977 BDC_FD_Crc2Val "The data area for CRC calculation is based on the data length (DLC) of the message DB.

The CRC shall be calculated over the entire data block (excluding the CRC bytes) including the user data, alive counter and Data ID



- CRC Polynomial (0x1021) , Ini";
BA_ "GenSigSendType" SG_ 977 BDC_FD_Crc2Val 4;
BA_ "GenSigStartValue" SG_ 977 BDC_FD_Crc2Val 65535;
BA_ "UserSigValidity" SG_ 977 BDC_FD_Crc2Val 0;
BA_ "Version" SG_ 977 BDC_FD_Crc2Val "22.11.04";
BA_ "Description" SG_ 977 BDC_FD_AlvCnt2Val "For the first transmission request for a data element the counter shall be initialized with 0 and shall be incremented by 1 for every subsequent send request. 

When the counter reaches the maximum value(0xFF), then it shall restart with 0 for the next s";
BA_ "GenSigSendType" SG_ 977 BDC_FD_AlvCnt2Val 4;
BA_ "UserSigValidity" SG_ 977 BDC_FD_AlvCnt2Val 0;
BA_ "Version" SG_ 977 BDC_FD_AlvCnt2Val "22.11.04";
BA_ "Description" SG_ 977 BCM_KeyInSta "Mechanical Key In SW State (If SMK option is On, C_KeyInSw always have  Off

 value)";
BA_ "GenSigSendType" SG_ 977 BCM_KeyInSta 4;
BA_ "UserSigValidity" SG_ 977 BCM_KeyInSta 0;
BA_ "NetworkRequest" SG_ 977 BCM_KeyInSta 0;
BA_ "NetworkRequestHoldingTime" SG_ 977 BCM_KeyInSta 5000;
BA_ "Version" SG_ 977 BCM_KeyInSta "17.12.00";
BA_ "GenSigSendType" SG_ 977 BCM_AccInSta 4;
BA_ "UserSigValidity" SG_ 977 BCM_AccInSta 0;
BA_ "NetworkRequest" SG_ 977 BCM_AccInSta 0;
BA_ "NetworkRequestHoldingTime" SG_ 977 BCM_AccInSta 5000;
BA_ "Version" SG_ 977 BCM_AccInSta "21.09.05";
BA_ "GenSigSendType" SG_ 977 BCM_Ign1InSta 4;
BA_ "UserSigValidity" SG_ 977 BCM_Ign1InSta 0;
BA_ "NetworkRequest" SG_ 977 BCM_Ign1InSta 0;
BA_ "NetworkRequestHoldingTime" SG_ 977 BCM_Ign1InSta 5000;
BA_ "Version" SG_ 977 BCM_Ign1InSta "21.09.05";
BA_ "GenSigSendType" SG_ 977 BCM_Ign2InSta 4;
BA_ "UserSigValidity" SG_ 977 BCM_Ign2InSta 0;
BA_ "NetworkRequest" SG_ 977 BCM_Ign2InSta 0;
BA_ "NetworkRequestHoldingTime" SG_ 977 BCM_Ign2InSta 5000;
BA_ "Version" SG_ 977 BCM_Ign2InSta "21.09.05";
BA_ "Description" SG_ 977 IBU_HDPSpprtSWVer "This signal indicates HDP-IBU requirement version";
BA_ "GenSigSendType" SG_ 977 IBU_HDPSpprtSWVer 4;
BA_ "UserSigValidity" SG_ 977 IBU_HDPSpprtSWVer 0;
BA_ "NetworkRequest" SG_ 977 IBU_HDPSpprtSWVer 0;
BA_ "NetworkRequestHoldingTime" SG_ 977 IBU_HDPSpprtSWVer 5000;
BA_ "Version" SG_ 977 IBU_HDPSpprtSWVer "21.10.04";
BA_ "Description" SG_ 977 IBU_HDPSpprtRdy "ADAS Message (received) Error State";
BA_ "GenSigSendType" SG_ 977 IBU_HDPSpprtRdy 4;
BA_ "UserSigValidity" SG_ 977 IBU_HDPSpprtRdy 0;
BA_ "NetworkRequest" SG_ 977 IBU_HDPSpprtRdy 0;
BA_ "NetworkRequestHoldingTime" SG_ 977 IBU_HDPSpprtRdy 5000;
BA_ "Version" SG_ 977 IBU_HDPSpprtRdy "22.03.02";
BA_ "Description" SG_ 977 BCM_GearPosPSta "This signal is valid only when connected to Key Interlock SW or P Position SW as a circuit";
BA_ "GenSigSendType" SG_ 977 BCM_GearPosPSta 4;
BA_ "UserSigValidity" SG_ 977 BCM_GearPosPSta 0;
BA_ "NetworkRequest" SG_ 977 BCM_GearPosPSta 0;
BA_ "NetworkRequestHoldingTime" SG_ 977 BCM_GearPosPSta 5000;
BA_ "Version" SG_ 977 BCM_GearPosPSta "21.09.05";
BA_ "Description" SG_ 977 BCM_SmkOptTyp "-(Old)C_PICOption";
BA_ "GenSigSendType" SG_ 977 BCM_SmkOptTyp 4;
BA_ "UserSigValidity" SG_ 977 BCM_SmkOptTyp 0;
BA_ "NetworkRequest" SG_ 977 BCM_SmkOptTyp 0;
BA_ "NetworkRequestHoldingTime" SG_ 977 BCM_SmkOptTyp 5000;
BA_ "Version" SG_ 977 BCM_SmkOptTyp "17.12.00";
BA_ "Description" SG_ 977 BDC_ResetOpSta "This signal indicates whether the reset operation has been completed or not";
BA_ "GenSigSendType" SG_ 977 BDC_ResetOpSta 4;
BA_ "UserSigValidity" SG_ 977 BDC_ResetOpSta 0;
BA_ "Version" SG_ 977 BDC_ResetOpSta "24.05.05";
BA_ "Description" SG_ 977 IBU_SWVerMajor1 "Indicate the IBU software version as follows:

- The software version is displayed in three digits.

- The Major and Minor digits are separated by '.'

- Signal values are transmitted to ASCII codes.



※ Example

C_IBU_SWVerMajor1 : 0x41 (HEX) -> ASCII";
BA_ "GenSigSendType" SG_ 977 IBU_SWVerMajor1 4;
BA_ "UserSigValidity" SG_ 977 IBU_SWVerMajor1 0;
BA_ "Version" SG_ 977 IBU_SWVerMajor1 "20.12.04";
BA_ "Description" SG_ 977 IBU_SWVerMinor1 "Indicate the IBU software version as follows:

- The software version is displayed in three digits.

- The Major and Minor digits are separated by '.'

- Signal values are transmitted to ASCII codes.



※ Example

C_IBU_SWVerMajor1 : 0x41 (HEX) -> ASCII";
BA_ "GenSigSendType" SG_ 977 IBU_SWVerMinor1 4;
BA_ "UserSigValidity" SG_ 977 IBU_SWVerMinor1 0;
BA_ "Version" SG_ 977 IBU_SWVerMinor1 "18.10.02";
BA_ "Description" SG_ 977 IBU_SWVerMinor2 "Indicate the IBU software version as follows:

- The software version is displayed in three digits.

- The Major and Minor digits are separated by '.'

- Signal values are transmitted to ASCII codes.



※ Example

C_IBU_SWVerMajor1 : 0x41 (HEX) -> ASCII";
BA_ "GenSigSendType" SG_ 977 IBU_SWVerMinor2 4;
BA_ "UserSigValidity" SG_ 977 IBU_SWVerMinor2 0;
BA_ "Version" SG_ 977 IBU_SWVerMinor2 "18.10.02";
BA_ "Description" SG_ 977 BDC_PlatformVerType "BDC Platform Type Information

- A / B / C";
BA_ "GenSigSendType" SG_ 977 BDC_PlatformVerType 4;
BA_ "UserSigValidity" SG_ 977 BDC_PlatformVerType 0;
BA_ "Version" SG_ 977 BDC_PlatformVerType "23.04.03";
BA_ "Description" SG_ 977 BDC_PlatformVerDate "BDC Platform Version Date 

Version Information

- YYMM 

- 0x1 : 2301 / 0x2 : 2302 …";
BA_ "GenSigSendType" SG_ 977 BDC_PlatformVerDate 4;
BA_ "UserSigValidity" SG_ 977 BDC_PlatformVerDate 0;
BA_ "Version" SG_ 977 BDC_PlatformVerDate "23.02.01";
BA_ "Description" SG_ 914 WPC2_FD_Crc1Val "The data area for CRC calculation is based on the data length (DLC) of the message DB.

The CRC shall be calculated over the entire data block (excluding the CRC bytes) including the user data, alive counter and Data ID



- CRC Polynomial (0x1021) , Ini";
BA_ "GenSigSendType" SG_ 914 WPC2_FD_Crc1Val 4;
BA_ "GenSigStartValue" SG_ 914 WPC2_FD_Crc1Val 65535;
BA_ "UserSigValidity" SG_ 914 WPC2_FD_Crc1Val 3;
BA_ "Version" SG_ 914 WPC2_FD_Crc1Val "22.10.20";
BA_ "Description" SG_ 914 WPC2_IndSyncVal "WPC IND ANIMATION SYNC SIGNAL";
BA_ "GenSigSendType" SG_ 914 WPC2_IndSyncVal 4;
BA_ "TimeoutValue" SG_ 914 WPC2_IndSyncVal "0x0";
BA_ "UserSigValidity" SG_ 914 WPC2_IndSyncVal 3;
BA_ "Version" SG_ 914 WPC2_IndSyncVal "22.04.01";
BA_ "Description" SG_ 914 WPC2_ResetOpSta "This signal indicates whether the reset operation has been completed or not";
BA_ "GenSigSendType" SG_ 914 WPC2_ResetOpSta 4;
BA_ "UserSigValidity" SG_ 914 WPC2_ResetOpSta 0;
BA_ "Version" SG_ 914 WPC2_ResetOpSta "24.05.01";
BA_ "Description" SG_ 914 WPC2_FD_AlvCnt1Val "For the first transmission request for a data element the counter shall be initialized with 0 and shall be incremented by 1 for every subsequent send request. 

When the counter reaches the maximum value(0xFF), then it shall restart with 0 for the next s";
BA_ "GenSigSendType" SG_ 914 WPC2_FD_AlvCnt1Val 4;
BA_ "UserSigValidity" SG_ 914 WPC2_FD_AlvCnt1Val 3;
BA_ "Version" SG_ 914 WPC2_FD_AlvCnt1Val "22.10.20";
BA_ "Description" SG_ 914 USM_CmdWPC2Sta "USM request value of WPC2";
BA_ "GenSigSendType" SG_ 914 USM_CmdWPC2Sta 4;
BA_ "UserSigValidity" SG_ 914 USM_CmdWPC2Sta 0;
BA_ "NetworkRequest" SG_ 914 USM_CmdWPC2Sta 0;
BA_ "NetworkRequestHoldingTime" SG_ 914 USM_CmdWPC2Sta 5000;
BA_ "Version" SG_ 914 USM_CmdWPC2Sta "22.02.06";
BA_ "Description" SG_ 914 WPC2_PhnLftWrngSta "Warning by WPC2 for User (Phone left in vehicle)";
BA_ "GenSigSendType" SG_ 914 WPC2_PhnLftWrngSta 4;
BA_ "UserSigValidity" SG_ 914 WPC2_PhnLftWrngSta 0;
BA_ "NetworkRequest" SG_ 914 WPC2_PhnLftWrngSta 0;
BA_ "NetworkRequestHoldingTime" SG_ 914 WPC2_PhnLftWrngSta 5000;
BA_ "Version" SG_ 914 WPC2_PhnLftWrngSta "24.01.00";
BA_ "Description" SG_ 914 WPC2_OptSta "Apply dual WPC information	2";
BA_ "GenSigSendType" SG_ 914 WPC2_OptSta 4;
BA_ "UserSigValidity" SG_ 914 WPC2_OptSta 0;
BA_ "NetworkRequest" SG_ 914 WPC2_OptSta 0;
BA_ "NetworkRequestHoldingTime" SG_ 914 WPC2_OptSta 5000;
BA_ "Version" SG_ 914 WPC2_OptSta "22.03.02";
BA_ "Description" SG_ 914 WPC2_SWVerMajor1 "Indicate the WPC2 software version as follows:

- The software version is displayed in three digits.

- The Major and Minor digits are separated by '.'

- Signal values are transmitted to ASCII codes.



※ Example

WPC2_SWVerMajor1 : 0x41 (HEX) -> ASCII";
BA_ "GenSigSendType" SG_ 914 WPC2_SWVerMajor1 4;
BA_ "UserSigValidity" SG_ 914 WPC2_SWVerMajor1 0;
BA_ "Version" SG_ 914 WPC2_SWVerMajor1 "22.02.06";
BA_ "Description" SG_ 914 WPC2_SWVerMinor1 "Indicate the WPC2 software version as follows:

- The software version is displayed in three digits.

- The Major and Minor digits are separated by '.'

- Signal values are transmitted to ASCII codes.



※ Example

WPC2_SWVerMajor1 : 0x41 (HEX) -> ASCII";
BA_ "GenSigSendType" SG_ 914 WPC2_SWVerMinor1 4;
BA_ "UserSigValidity" SG_ 914 WPC2_SWVerMinor1 0;
BA_ "Version" SG_ 914 WPC2_SWVerMinor1 "22.02.06";
BA_ "Description" SG_ 914 WPC2_SWVerMinor2 "Indicate the WPC2 software version as follows:

- The software version is displayed in three digits.

- The Major and Minor digits are separated by '.'

- Signal values are transmitted to ASCII codes.



※ Example

WPC2_SWVerMajor1 : 0x41 (HEX) -> ASCII";
BA_ "GenSigSendType" SG_ 914 WPC2_SWVerMinor2 4;
BA_ "UserSigValidity" SG_ 914 WPC2_SWVerMinor2 0;
BA_ "Version" SG_ 914 WPC2_SWVerMinor2 "22.02.06";
BA_ "Description" SG_ 2015 GST_ALL_Byte0 "TP Index : 0";
BA_ "UsrSigPurpose" SG_ 2015 GST_ALL_Byte0 5;
BA_ "UserSigValidity" SG_ 2015 GST_ALL_Byte0 0;
BA_ "NetworkRequest" SG_ 2015 GST_ALL_Byte0 0;
BA_ "NetworkRequestHoldingTime" SG_ 2015 GST_ALL_Byte0 5000;
BA_ "Version" SG_ 2015 GST_ALL_Byte0 "22.06.01";
BA_ "Description" SG_ 2015 GST_ALL_Byte2 "TP Index : 0";
BA_ "UsrSigPurpose" SG_ 2015 GST_ALL_Byte2 5;
BA_ "UserSigValidity" SG_ 2015 GST_ALL_Byte2 0;
BA_ "NetworkRequest" SG_ 2015 GST_ALL_Byte2 0;
BA_ "NetworkRequestHoldingTime" SG_ 2015 GST_ALL_Byte2 5000;
BA_ "Version" SG_ 2015 GST_ALL_Byte2 "22.06.01";
BA_ "Description" SG_ 2015 GST_ALL_Byte3 "TP Index : 0";
BA_ "UsrSigPurpose" SG_ 2015 GST_ALL_Byte3 5;
BA_ "UserSigValidity" SG_ 2015 GST_ALL_Byte3 0;
BA_ "NetworkRequest" SG_ 2015 GST_ALL_Byte3 0;
BA_ "NetworkRequestHoldingTime" SG_ 2015 GST_ALL_Byte3 5000;
BA_ "Version" SG_ 2015 GST_ALL_Byte3 "22.06.01";
BA_ "Description" SG_ 2015 GST_ALL_Byte4 "TP Index : 0";
BA_ "UsrSigPurpose" SG_ 2015 GST_ALL_Byte4 5;
BA_ "UserSigValidity" SG_ 2015 GST_ALL_Byte4 0;
BA_ "NetworkRequest" SG_ 2015 GST_ALL_Byte4 0;
BA_ "NetworkRequestHoldingTime" SG_ 2015 GST_ALL_Byte4 5000;
BA_ "Version" SG_ 2015 GST_ALL_Byte4 "22.06.01";
BA_ "Description" SG_ 2015 GST_ALL_Byte5 "TP Index : 0";
BA_ "UsrSigPurpose" SG_ 2015 GST_ALL_Byte5 5;
BA_ "UserSigValidity" SG_ 2015 GST_ALL_Byte5 0;
BA_ "NetworkRequest" SG_ 2015 GST_ALL_Byte5 0;
BA_ "NetworkRequestHoldingTime" SG_ 2015 GST_ALL_Byte5 5000;
BA_ "Version" SG_ 2015 GST_ALL_Byte5 "22.06.01";
BA_ "Description" SG_ 2015 GST_ALL_Byte6 "TP Index : 0";
BA_ "UsrSigPurpose" SG_ 2015 GST_ALL_Byte6 5;
BA_ "UserSigValidity" SG_ 2015 GST_ALL_Byte6 0;
BA_ "NetworkRequest" SG_ 2015 GST_ALL_Byte6 0;
BA_ "NetworkRequestHoldingTime" SG_ 2015 GST_ALL_Byte6 5000;
BA_ "Version" SG_ 2015 GST_ALL_Byte6 "22.06.01";
BA_ "Description" SG_ 2015 GST_ALL_Byte7 "TP Index : 0";
BA_ "UsrSigPurpose" SG_ 2015 GST_ALL_Byte7 5;
BA_ "UserSigValidity" SG_ 2015 GST_ALL_Byte7 0;
BA_ "NetworkRequest" SG_ 2015 GST_ALL_Byte7 0;
BA_ "NetworkRequestHoldingTime" SG_ 2015 GST_ALL_Byte7 5000;
BA_ "Version" SG_ 2015 GST_ALL_Byte7 "22.06.01";
BA_ "Description" SG_ 2015 GST_ALL_Byte1 "TP Index : 0";
BA_ "UsrSigPurpose" SG_ 2015 GST_ALL_Byte1 5;
BA_ "UserSigValidity" SG_ 2015 GST_ALL_Byte1 0;
BA_ "NetworkRequest" SG_ 2015 GST_ALL_Byte1 0;
BA_ "NetworkRequestHoldingTime" SG_ 2015 GST_ALL_Byte1 5000;
BA_ "Version" SG_ 2015 GST_ALL_Byte1 "22.06.01";
BA_REL_ "GenSigTimeoutTime" BU_SG_REL_ GW_PSU_DRV_FD SG_ 813 SBCM_DRV_FD_Crc1Val 1500;
BA_REL_ "GenSigTimeoutTime" BU_SG_REL_ RWPC_FD SG_ 813 Latch_TypeOption_DRV 1500;
BA_REL_ "GenSigTimeoutTime" BU_SG_REL_ WPC2_FD SG_ 813 Latch_TypeOption_DRV 1500;
BA_REL_ "GenSigTimeoutTime" BU_SG_REL_ WPC_FD SG_ 813 Latch_TypeOption_DRV 1500;
BA_REL_ "GenSigTimeoutTime" BU_SG_REL_ ATS_FD SG_ 813 DRV_SWFailAlarm 1500;
BA_REL_ "GenSigTimeoutTime" BU_SG_REL_ ATS_FD SG_ 813 PDS_TypeOption_DRV 1500;
BA_REL_ "GenSigTimeoutTime" BU_SG_REL_ GW_PSU_DRV_FD SG_ 813 SBCM_DRV_FD_AlvCnt1Val 1500;
BA_REL_ "GenSigTimeoutTime" BU_SG_REL_ GW_PSU_DRV_FD SG_ 813 IMS_OSMirPlayBackSta_LH 1500;
BA_REL_ "GenSigTimeoutTime" BU_SG_REL_ GW_PSU_DRV_FD SG_ 813 IMS_OSMirPlayBackSta_LH_New 1500;
BA_REL_ "GenSigTimeoutTime" BU_SG_REL_ BLTN_CAM_FD SG_ 813 Warn_HoodSwSta_SBCM 1500;
BA_REL_ "GenSigTimeoutTime" BU_SG_REL_ BLTN_CAM_FD SG_ 813 Hood_TypeOption 1500;
BA_REL_ "GenSigTimeoutTime" BU_SG_REL_ ATS_FD SG_ 813 PwrDRClosingDRVDrSta 1500;
BA_REL_ "GenSigTimeoutTime" BU_SG_REL_ ATS_FD SG_ 813 DRV_DetectObj_warn_LH 1500;
BA_REL_ "GenSigTimeoutTime" BU_SG_REL_ ATS_FD SG_ 813 PwrDROpenClosingDdvSdDRSta 1500;
BA_REL_ "GenSigTimeoutTime" BU_SG_REL_ ATS_FD SG_ 813 Coach_TypeOption_DRV 1500;
BA_REL_ "GenSigTimeoutTime" BU_SG_REL_ GW_PSU_RL_FD SG_ 813 Coach_TypeOption_DRV 1500;
BA_REL_ "GenSigTimeoutTime" BU_SG_REL_ GW_PSU_RR_FD SG_ 813 Coach_TypeOption_DRV 1500;
BA_REL_ "GenSigTimeoutTime" BU_SG_REL_ ATS_FD SG_ 813 PwrDrSta_Drv 1500;
BA_REL_ "GenSigTimeoutTime" BU_SG_REL_ ATS_FD SG_ 813 PwrDrSta_DrvSd 1500;
BA_REL_ "GenSigTimeoutTime" BU_SG_REL_ ATS_FD SG_ 813 SBCM_FL_DoorAngle 1500;
BA_REL_ "GenSigTimeoutTime" BU_SG_REL_ BLTN_CAM_FD SG_ 813 DRV_CrashUnlockCmd 1500;
BA_REL_ "GenSigTimeoutTime" BU_SG_REL_ ATS_FD SG_ 813 Warn_DrvDrSwSta_SBCM 1500;
BA_REL_ "GenSigTimeoutTime" BU_SG_REL_ BLTN_CAM_FD SG_ 813 Warn_DrvDrSwSta_SBCM 1500;
BA_REL_ "GenSigTimeoutTime" BU_SG_REL_ DCM_FD SG_ 813 Warn_DrvDrSwSta_SBCM 1500;
BA_REL_ "GenSigTimeoutTime" BU_SG_REL_ GW_PSU_DRV_FD SG_ 813 Warn_DrvDrSwSta_SBCM 1500;
BA_REL_ "GenSigTimeoutTime" BU_SG_REL_ PSB_FD SG_ 813 Warn_DrvDrSwSta_SBCM 1500;
BA_REL_ "GenSigTimeoutTime" BU_SG_REL_ RWPC_FD SG_ 813 Warn_DrvDrSwSta_SBCM 1500;
BA_REL_ "GenSigTimeoutTime" BU_SG_REL_ WPC2_FD SG_ 813 Warn_DrvDrSwSta_SBCM 1500;
BA_REL_ "GenSigTimeoutTime" BU_SG_REL_ WPC_FD SG_ 813 Warn_DrvDrSwSta_SBCM 1500;
BA_REL_ "GenSigTimeoutTime" BU_SG_REL_ ATS_FD SG_ 813 DoorLock_DrvDrUnLkSta_SBCM 1500;
BA_REL_ "GenSigTimeoutTime" BU_SG_REL_ FCS_FD SG_ 813 DoorLock_DrvDrUnLkSta_SBCM 1500;
BA_REL_ "GenSigTimeoutTime" BU_SG_REL_ GW_PSU_DRV_FD SG_ 813 DoorLock_DrvDrUnLkSta_SBCM 1500;
BA_REL_ "GenSigTimeoutTime" BU_SG_REL_ ATS_FD SG_ 813 DRV_SEAWarn_LH 1500;
BA_REL_ "GenSigTimeoutTime" BU_SG_REL_ GW_PSU_DRV_FD SG_ 994 PDC_FD_Crc3Val 1500;
BA_REL_ "GenSigTimeoutTime" BU_SG_REL_ GW_PSU_DRV_FD SG_ 994 PDC_FD_AlvCnt3Val 1500;
BA_REL_ "GenSigTimeoutTime" BU_SG_REL_ BLTN_CAM_FD SG_ 994 Warn_DrvDrSwSta 1500;
BA_REL_ "GenSigTimeoutTime" BU_SG_REL_ DCM_FD SG_ 994 Warn_DrvDrSwSta 1500;
BA_REL_ "GenSigTimeoutTime" BU_SG_REL_ GW_PSU_DRV_FD SG_ 994 Warn_DrvDrSwSta 1500;
BA_REL_ "GenSigTimeoutTime" BU_SG_REL_ PSB_FD SG_ 994 Warn_DrvDrSwSta 1500;
BA_REL_ "GenSigTimeoutTime" BU_SG_REL_ RWPC_FD SG_ 994 Warn_DrvDrSwSta 1500;
BA_REL_ "GenSigTimeoutTime" BU_SG_REL_ WPC2_FD SG_ 994 Warn_DrvDrSwSta 1500;
BA_REL_ "GenSigTimeoutTime" BU_SG_REL_ WPC_FD SG_ 994 Warn_DrvDrSwSta 1500;
BA_REL_ "GenSigTimeoutTime" BU_SG_REL_ BLTN_CAM_FD SG_ 994 Warn_AsstDrSwSta 1500;
BA_REL_ "GenSigTimeoutTime" BU_SG_REL_ DCM_FD SG_ 994 Warn_AsstDrSwSta 1500;
BA_REL_ "GenSigTimeoutTime" BU_SG_REL_ GW_PSU_AST_FD SG_ 994 Warn_AsstDrSwSta 1500;
BA_REL_ "GenSigTimeoutTime" BU_SG_REL_ GW_PSU_RL_FD SG_ 994 Warn_AsstDrSwSta 1500;
BA_REL_ "GenSigTimeoutTime" BU_SG_REL_ GW_SAU_DRV_FD SG_ 994 Warn_AsstDrSwSta 1500;
BA_REL_ "GenSigTimeoutTime" BU_SG_REL_ PSB_FD SG_ 994 Warn_AsstDrSwSta 1500;
BA_REL_ "GenSigTimeoutTime" BU_SG_REL_ RWPC_FD SG_ 994 Warn_AsstDrSwSta 1500;
BA_REL_ "GenSigTimeoutTime" BU_SG_REL_ WPC2_FD SG_ 994 Warn_AsstDrSwSta 1500;
BA_REL_ "GenSigTimeoutTime" BU_SG_REL_ WPC_FD SG_ 994 Warn_AsstDrSwSta 1500;
BA_REL_ "GenSigTimeoutTime" BU_SG_REL_ BLTN_CAM_FD SG_ 994 Warn_RrLftDrSwSta 1500;
BA_REL_ "GenSigTimeoutTime" BU_SG_REL_ DCM_FD SG_ 994 Warn_RrLftDrSwSta 1500;
BA_REL_ "GenSigTimeoutTime" BU_SG_REL_ GW_PSU_AST_FD SG_ 994 Warn_RrLftDrSwSta 1500;
BA_REL_ "GenSigTimeoutTime" BU_SG_REL_ GW_PSU_RL_FD SG_ 994 Warn_RrLftDrSwSta 1500;
BA_REL_ "GenSigTimeoutTime" BU_SG_REL_ GW_PSU_RR_FD SG_ 994 Warn_RrLftDrSwSta 1500;
BA_REL_ "GenSigTimeoutTime" BU_SG_REL_ PSB_FD SG_ 994 Warn_RrLftDrSwSta 1500;
BA_REL_ "GenSigTimeoutTime" BU_SG_REL_ RWPC_FD SG_ 994 Warn_RrLftDrSwSta 1500;
BA_REL_ "GenSigTimeoutTime" BU_SG_REL_ SHVU_RL_FD SG_ 994 Warn_RrLftDrSwSta 1500;
BA_REL_ "GenSigTimeoutTime" BU_SG_REL_ WPC2_FD SG_ 994 Warn_RrLftDrSwSta 1500;
BA_REL_ "GenSigTimeoutTime" BU_SG_REL_ WPC_FD SG_ 994 Warn_RrLftDrSwSta 1500;
BA_REL_ "GenSigTimeoutTime" BU_SG_REL_ BLTN_CAM_FD SG_ 994 Warn_RrRtDrSwSta 1500;
BA_REL_ "GenSigTimeoutTime" BU_SG_REL_ DCM_FD SG_ 994 Warn_RrRtDrSwSta 1500;
BA_REL_ "GenSigTimeoutTime" BU_SG_REL_ GW_PSU_AST_FD SG_ 994 Warn_RrRtDrSwSta 1500;
BA_REL_ "GenSigTimeoutTime" BU_SG_REL_ GW_PSU_RL_FD SG_ 994 Warn_RrRtDrSwSta 1500;
BA_REL_ "GenSigTimeoutTime" BU_SG_REL_ GW_PSU_RR_FD SG_ 994 Warn_RrRtDrSwSta 1500;
BA_REL_ "GenSigTimeoutTime" BU_SG_REL_ PSB_FD SG_ 994 Warn_RrRtDrSwSta 1500;
BA_REL_ "GenSigTimeoutTime" BU_SG_REL_ RWPC_FD SG_ 994 Warn_RrRtDrSwSta 1500;
BA_REL_ "GenSigTimeoutTime" BU_SG_REL_ SHVU_RR_FD SG_ 994 Warn_RrRtDrSwSta 1500;
BA_REL_ "GenSigTimeoutTime" BU_SG_REL_ WPC2_FD SG_ 994 Warn_RrRtDrSwSta 1500;
BA_REL_ "GenSigTimeoutTime" BU_SG_REL_ WPC_FD SG_ 994 Warn_RrRtDrSwSta 1500;
BA_REL_ "GenSigTimeoutTime" BU_SG_REL_ BLTN_CAM_FD SG_ 994 Warn_HoodSwSta 1500;
BA_REL_ "GenSigTimeoutTime" BU_SG_REL_ GW_PSU_DRV_FD SG_ 994 DoorLock_DrvDrUnLkSta 1500;
BA_REL_ "GenSigTimeoutTime" BU_SG_REL_ BLTN_CAM_FD SG_ 994 C_CrashUnlockState 1500;
BA_REL_ "GenSigTimeoutTime" BU_SG_REL_ WPC_FD SG_ 1242 USM_WpcSetReq 0;
BA_REL_ "GenSigTimeoutTime" BU_SG_REL_ WPC2_FD SG_ 1242 USM_WpcSetReq 0;
BA_REL_ "GenSigTimeoutTime" BU_SG_REL_ WPC2_FD SG_ 1242 USM_Wpc2SetReq 0;
BA_REL_ "GenSigTimeoutTime" BU_SG_REL_ GW_PSU_DRV_FD SG_ 811 SBCM_AST_FD_Crc1Val 1500;
BA_REL_ "GenSigTimeoutTime" BU_SG_REL_ ATS_FD SG_ 811 AST_SWFailAlarm 1500;
BA_REL_ "GenSigTimeoutTime" BU_SG_REL_ GW_PSU_DRV_FD SG_ 811 SBCM_AST_FD_AlvCnt1Val 1500;
BA_REL_ "GenSigTimeoutTime" BU_SG_REL_ GW_PSU_DRV_FD SG_ 811 IMS_OSMirPlayBackSta_RH 1500;
BA_REL_ "GenSigTimeoutTime" BU_SG_REL_ ATS_FD SG_ 811 PwrDRClosingASTDrSta 1500;
BA_REL_ "GenSigTimeoutTime" BU_SG_REL_ GW_PSU_DRV_FD SG_ 811 IMS_OSMirPlayBackSta_RH_New 1500;
BA_REL_ "GenSigTimeoutTime" BU_SG_REL_ ATS_FD SG_ 811 PwrDrSta_Ast 1500;
BA_REL_ "GenSigTimeoutTime" BU_SG_REL_ ATS_FD SG_ 811 PwrDrSta_AstSd 1500;
BA_REL_ "GenSigTimeoutTime" BU_SG_REL_ ATS_FD SG_ 811 AST_DetectObj_warn_LH 1500;
BA_REL_ "GenSigTimeoutTime" BU_SG_REL_ ATS_FD SG_ 811 PwrDROpenClosingAstSdDRSta 1500;
BA_REL_ "GenSigTimeoutTime" BU_SG_REL_ ATS_FD SG_ 811 SBCM_FR_DoorAngle 1500;
BA_REL_ "GenSigTimeoutTime" BU_SG_REL_ BLTN_CAM_FD SG_ 811 AST_CrashUnlockCmd 1500;
BA_REL_ "GenSigTimeoutTime" BU_SG_REL_ ATS_FD SG_ 811 Warn_AsstDrSwSta_SBCM 1500;
BA_REL_ "GenSigTimeoutTime" BU_SG_REL_ BLTN_CAM_FD SG_ 811 Warn_AsstDrSwSta_SBCM 1500;
BA_REL_ "GenSigTimeoutTime" BU_SG_REL_ DCM_FD SG_ 811 Warn_AsstDrSwSta_SBCM 1500;
BA_REL_ "GenSigTimeoutTime" BU_SG_REL_ GW_PSU_AST_FD SG_ 811 Warn_AsstDrSwSta_SBCM 1500;
BA_REL_ "GenSigTimeoutTime" BU_SG_REL_ GW_SAU_DRV_FD SG_ 811 Warn_AsstDrSwSta_SBCM 1500;
BA_REL_ "GenSigTimeoutTime" BU_SG_REL_ PSB_FD SG_ 811 Warn_AsstDrSwSta_SBCM 1500;
BA_REL_ "GenSigTimeoutTime" BU_SG_REL_ RWPC_FD SG_ 811 Warn_AsstDrSwSta_SBCM 1500;
BA_REL_ "GenSigTimeoutTime" BU_SG_REL_ WPC2_FD SG_ 811 Warn_AsstDrSwSta_SBCM 1500;
BA_REL_ "GenSigTimeoutTime" BU_SG_REL_ WPC_FD SG_ 811 Warn_AsstDrSwSta_SBCM 1500;
BA_REL_ "GenSigTimeoutTime" BU_SG_REL_ ATS_FD SG_ 811 DoorLock_AsstDrUnLkSta_SBCM 1500;
BA_REL_ "GenSigTimeoutTime" BU_SG_REL_ FCS_FD SG_ 811 DoorLock_AsstDrUnLkSta_SBCM 1500;
BA_REL_ "GenSigTimeoutTime" BU_SG_REL_ ATS_FD SG_ 811 AST_SEAWarn_LH 1500;
BA_REL_ "GenSigTimeoutTime" BU_SG_REL_ WPC_FD SG_ 789 CLU_ClusterUSM 1500;
BA_REL_ "GenSigTimeoutTime" BU_SG_REL_ WPC2_FD SG_ 789 CLU_ClusterUSM 1500;
BA_REL_ "GenSigTimeoutTime" BU_SG_REL_ GW_PSU_DRV_FD SG_ 849 IAU_FD_Crc4Val 1500;
BA_REL_ "GenSigTimeoutTime" BU_SG_REL_ WPC2_FD SG_ 849 IAU_DigitalKey2Opt 1500;
BA_REL_ "GenSigTimeoutTime" BU_SG_REL_ WPC_FD SG_ 849 IAU_DigitalKey2Opt 1500;
BA_REL_ "GenSigTimeoutTime" BU_SG_REL_ GW_PSU_DRV_FD SG_ 849 IAU_FD_AlvCnt4Val 1500;
BA_REL_ "GenSigTimeoutTime" BU_SG_REL_ BLTN_CAM_FD SG_ 849 IAU_ProfileIDRVal 1500;
BA_REL_ "GenSigTimeoutTime" BU_SG_REL_ GW_PSU_DRV_FD SG_ 849 IAU_ProfileIDRVal 1500;
BA_REL_ "GenSigTimeoutTime" BU_SG_REL_ GW_SAU_DRV_FD SG_ 849 IAU_ProfileIDRVal 1500;
BA_REL_ "GenSigTimeoutTime" BU_SG_REL_ RCM_FD SG_ 849 IAU_ProfileIDRVal 1500;
BA_REL_ "GenSigTimeoutTime" BU_SG_REL_ RWPC_FD SG_ 849 IAU_ProfileIDRVal 1500;
BA_REL_ "GenSigTimeoutTime" BU_SG_REL_ SGU_FD SG_ 849 IAU_ProfileIDRVal 1500;
BA_REL_ "GenSigTimeoutTime" BU_SG_REL_ WPC2_FD SG_ 849 IAU_ProfileIDRVal 1500;
BA_REL_ "GenSigTimeoutTime" BU_SG_REL_ WPC_FD SG_ 849 IAU_ProfileIDRVal 1500;
BA_REL_ "GenSigTimeoutTime" BU_SG_REL_ WPC2_FD SG_ 788 RWPC_IndSyncVal 1500;
BA_REL_ "GenSigTimeoutTime" BU_SG_REL_ WPC_FD SG_ 788 RWPC_IndSyncVal 1500;
BA_REL_ "GenSigTimeoutTime" BU_SG_REL_ ATS_FD SG_ 788 USM_ValCmdSta 1500;
BA_REL_ "GenSigTimeoutTime" BU_SG_REL_ CGW_CCU SG_ 788 USM_ValCmdSta 1500;
BA_REL_ "GenSigTimeoutTime" BU_SG_REL_ ATS_FD SG_ 788 WPC_PhnLftWrngRWPCSta 1500;
BA_REL_ "GenSigTimeoutTime" BU_SG_REL_ CGW_CCU SG_ 788 WPC_PhnLftWrngRWPCSta 1500;
BA_REL_ "GenSigTimeoutTime" BU_SG_REL_ ATS_FD SG_ 788 USM_ValCmdStaforATS 1500;
BA_REL_ "GenSigTimeoutTime" BU_SG_REL_ CGW_CCU SG_ 788 RWPC_SWVerMajor1 1500;
BA_REL_ "GenSigTimeoutTime" BU_SG_REL_ CGW_CCU SG_ 788 RWPC_SWVerMinor1 1500;
BA_REL_ "GenSigTimeoutTime" BU_SG_REL_ CGW_CCU SG_ 788 RWPC_SWVerMinor2 1500;
BA_REL_ "GenSigTimeoutTime" BU_SG_REL_ GW_PSU_DRV_FD SG_ 977 BDC_FD_Crc2Val 1500;
BA_REL_ "GenSigTimeoutTime" BU_SG_REL_ GW_PSU_DRV_FD SG_ 977 BDC_FD_AlvCnt2Val 1500;
BA_REL_ "GenSigTimeoutTime" BU_SG_REL_ DCM_FD SG_ 977 BCM_KeyInSta 1500;
BA_REL_ "GenSigTimeoutTime" BU_SG_REL_ GW_PSU_3RD_FD SG_ 977 BCM_KeyInSta 1500;
BA_REL_ "GenSigTimeoutTime" BU_SG_REL_ GW_PSU_AST_FD SG_ 977 BCM_KeyInSta 1500;
BA_REL_ "GenSigTimeoutTime" BU_SG_REL_ GW_PSU_DRV_FD SG_ 977 BCM_KeyInSta 1500;
BA_REL_ "GenSigTimeoutTime" BU_SG_REL_ GW_PSU_RL_FD SG_ 977 BCM_KeyInSta 1500;
BA_REL_ "GenSigTimeoutTime" BU_SG_REL_ GW_PSU_RR_FD SG_ 977 BCM_KeyInSta 1500;
BA_REL_ "GenSigTimeoutTime" BU_SG_REL_ GW_SAU_DRV_FD SG_ 977 BCM_KeyInSta 1500;
BA_REL_ "GenSigTimeoutTime" BU_SG_REL_ SGU_FD SG_ 977 BCM_KeyInSta 1500;
BA_REL_ "GenSigTimeoutTime" BU_SG_REL_ SHVU_3RD_FD SG_ 977 BCM_KeyInSta 1500;
BA_REL_ "GenSigTimeoutTime" BU_SG_REL_ SHVU_CCS_FD SG_ 977 BCM_KeyInSta 1500;
BA_REL_ "GenSigTimeoutTime" BU_SG_REL_ SHVU_FRNT_FD SG_ 977 BCM_KeyInSta 1500;
BA_REL_ "GenSigTimeoutTime" BU_SG_REL_ SHVU_REAR_FD SG_ 977 BCM_KeyInSta 1500;
BA_REL_ "GenSigTimeoutTime" BU_SG_REL_ SHVU_RL_FD SG_ 977 BCM_KeyInSta 1500;
BA_REL_ "GenSigTimeoutTime" BU_SG_REL_ SHVU_RR_FD SG_ 977 BCM_KeyInSta 1500;
BA_REL_ "GenSigTimeoutTime" BU_SG_REL_ ATS_FD SG_ 977 BCM_AccInSta 1500;
BA_REL_ "GenSigTimeoutTime" BU_SG_REL_ DCM_FD SG_ 977 BCM_AccInSta 1500;
BA_REL_ "GenSigTimeoutTime" BU_SG_REL_ FCS_FD SG_ 977 BCM_AccInSta 1500;
BA_REL_ "GenSigTimeoutTime" BU_SG_REL_ GW_PSU_3RD_FD SG_ 977 BCM_AccInSta 1500;
BA_REL_ "GenSigTimeoutTime" BU_SG_REL_ GW_PSU_AST_FD SG_ 977 BCM_AccInSta 1500;
BA_REL_ "GenSigTimeoutTime" BU_SG_REL_ GW_PSU_DRV_FD SG_ 977 BCM_AccInSta 1500;
BA_REL_ "GenSigTimeoutTime" BU_SG_REL_ GW_PSU_RL_FD SG_ 977 BCM_AccInSta 1500;
BA_REL_ "GenSigTimeoutTime" BU_SG_REL_ GW_PSU_RR_FD SG_ 977 BCM_AccInSta 1500;
BA_REL_ "GenSigTimeoutTime" BU_SG_REL_ GW_SAU_DRV_FD SG_ 977 BCM_AccInSta 1500;
BA_REL_ "GenSigTimeoutTime" BU_SG_REL_ SCM_FD SG_ 977 BCM_AccInSta 1500;
BA_REL_ "GenSigTimeoutTime" BU_SG_REL_ SGU_FD SG_ 977 BCM_AccInSta 1500;
BA_REL_ "GenSigTimeoutTime" BU_SG_REL_ SHVU_3RD_FD SG_ 977 BCM_AccInSta 1500;
BA_REL_ "GenSigTimeoutTime" BU_SG_REL_ SHVU_CCS_FD SG_ 977 BCM_AccInSta 1500;
BA_REL_ "GenSigTimeoutTime" BU_SG_REL_ SHVU_FRNT_FD SG_ 977 BCM_AccInSta 1500;
BA_REL_ "GenSigTimeoutTime" BU_SG_REL_ SHVU_REAR_FD SG_ 977 BCM_AccInSta 1500;
BA_REL_ "GenSigTimeoutTime" BU_SG_REL_ SHVU_RL_FD SG_ 977 BCM_AccInSta 1500;
BA_REL_ "GenSigTimeoutTime" BU_SG_REL_ SHVU_RR_FD SG_ 977 BCM_AccInSta 1500;
BA_REL_ "GenSigTimeoutTime" BU_SG_REL_ WPC2_FD SG_ 977 BCM_AccInSta 1500;
BA_REL_ "GenSigTimeoutTime" BU_SG_REL_ ATS_FD SG_ 977 BCM_Ign1InSta 1500;
BA_REL_ "GenSigTimeoutTime" BU_SG_REL_ DCM_FD SG_ 977 BCM_Ign1InSta 1500;
BA_REL_ "GenSigTimeoutTime" BU_SG_REL_ FCS_FD SG_ 977 BCM_Ign1InSta 1500;
BA_REL_ "GenSigTimeoutTime" BU_SG_REL_ GW_PSU_3RD_FD SG_ 977 BCM_Ign1InSta 1500;
BA_REL_ "GenSigTimeoutTime" BU_SG_REL_ GW_PSU_AST_FD SG_ 977 BCM_Ign1InSta 1500;
BA_REL_ "GenSigTimeoutTime" BU_SG_REL_ GW_PSU_DRV_FD SG_ 977 BCM_Ign1InSta 1500;
BA_REL_ "GenSigTimeoutTime" BU_SG_REL_ GW_PSU_RL_FD SG_ 977 BCM_Ign1InSta 1500;
BA_REL_ "GenSigTimeoutTime" BU_SG_REL_ GW_PSU_RR_FD SG_ 977 BCM_Ign1InSta 1500;
BA_REL_ "GenSigTimeoutTime" BU_SG_REL_ GW_SAU_DRV_FD SG_ 977 BCM_Ign1InSta 1500;
BA_REL_ "GenSigTimeoutTime" BU_SG_REL_ RCM_FD SG_ 977 BCM_Ign1InSta 1500;
BA_REL_ "GenSigTimeoutTime" BU_SG_REL_ SCM_FD SG_ 977 BCM_Ign1InSta 1500;
BA_REL_ "GenSigTimeoutTime" BU_SG_REL_ SGU_FD SG_ 977 BCM_Ign1InSta 1500;
BA_REL_ "GenSigTimeoutTime" BU_SG_REL_ SHVU_3RD_FD SG_ 977 BCM_Ign1InSta 1500;
BA_REL_ "GenSigTimeoutTime" BU_SG_REL_ SHVU_CCS_FD SG_ 977 BCM_Ign1InSta 1500;
BA_REL_ "GenSigTimeoutTime" BU_SG_REL_ SHVU_FRNT_FD SG_ 977 BCM_Ign1InSta 1500;
BA_REL_ "GenSigTimeoutTime" BU_SG_REL_ SHVU_REAR_FD SG_ 977 BCM_Ign1InSta 1500;
BA_REL_ "GenSigTimeoutTime" BU_SG_REL_ SHVU_RL_FD SG_ 977 BCM_Ign1InSta 1500;
BA_REL_ "GenSigTimeoutTime" BU_SG_REL_ SHVU_RR_FD SG_ 977 BCM_Ign1InSta 1500;
BA_REL_ "GenSigTimeoutTime" BU_SG_REL_ ATS_FD SG_ 977 BCM_Ign2InSta 1500;
BA_REL_ "GenSigTimeoutTime" BU_SG_REL_ DCM_FD SG_ 977 BCM_Ign2InSta 1500;
BA_REL_ "GenSigTimeoutTime" BU_SG_REL_ FCS_FD SG_ 977 BCM_Ign2InSta 1500;
BA_REL_ "GenSigTimeoutTime" BU_SG_REL_ GW_PSU_3RD_FD SG_ 977 BCM_Ign2InSta 1500;
BA_REL_ "GenSigTimeoutTime" BU_SG_REL_ GW_PSU_AST_FD SG_ 977 BCM_Ign2InSta 1500;
BA_REL_ "GenSigTimeoutTime" BU_SG_REL_ GW_PSU_DRV_FD SG_ 977 BCM_Ign2InSta 1500;
BA_REL_ "GenSigTimeoutTime" BU_SG_REL_ GW_PSU_RL_FD SG_ 977 BCM_Ign2InSta 1500;
BA_REL_ "GenSigTimeoutTime" BU_SG_REL_ GW_PSU_RR_FD SG_ 977 BCM_Ign2InSta 1500;
BA_REL_ "GenSigTimeoutTime" BU_SG_REL_ GW_SAU_DRV_FD SG_ 977 BCM_Ign2InSta 1500;
BA_REL_ "GenSigTimeoutTime" BU_SG_REL_ RCM_FD SG_ 977 BCM_Ign2InSta 1500;
BA_REL_ "GenSigTimeoutTime" BU_SG_REL_ SCM_FD SG_ 977 BCM_Ign2InSta 1500;
BA_REL_ "GenSigTimeoutTime" BU_SG_REL_ SGU_FD SG_ 977 BCM_Ign2InSta 1500;
BA_REL_ "GenSigTimeoutTime" BU_SG_REL_ SHVU_3RD_FD SG_ 977 BCM_Ign2InSta 1500;
BA_REL_ "GenSigTimeoutTime" BU_SG_REL_ SHVU_CCS_FD SG_ 977 BCM_Ign2InSta 1500;
BA_REL_ "GenSigTimeoutTime" BU_SG_REL_ SHVU_FRNT_FD SG_ 977 BCM_Ign2InSta 1500;
BA_REL_ "GenSigTimeoutTime" BU_SG_REL_ SHVU_REAR_FD SG_ 977 BCM_Ign2InSta 1500;
BA_REL_ "GenSigTimeoutTime" BU_SG_REL_ SHVU_RL_FD SG_ 977 BCM_Ign2InSta 1500;
BA_REL_ "GenSigTimeoutTime" BU_SG_REL_ SHVU_RR_FD SG_ 977 BCM_Ign2InSta 1500;
BA_REL_ "GenSigTimeoutTime" BU_SG_REL_ ATS_FD SG_ 977 BCM_GearPosPSta 1500;
BA_REL_ "GenSigTimeoutTime" BU_SG_REL_ GW_PSU_3RD_FD SG_ 977 BCM_GearPosPSta 1500;
BA_REL_ "GenSigTimeoutTime" BU_SG_REL_ GW_PSU_AST_FD SG_ 977 BCM_GearPosPSta 1500;
BA_REL_ "GenSigTimeoutTime" BU_SG_REL_ GW_PSU_DRV_FD SG_ 977 BCM_GearPosPSta 1500;
BA_REL_ "GenSigTimeoutTime" BU_SG_REL_ GW_PSU_RL_FD SG_ 977 BCM_GearPosPSta 1500;
BA_REL_ "GenSigTimeoutTime" BU_SG_REL_ GW_PSU_RR_FD SG_ 977 BCM_GearPosPSta 1500;
BA_REL_ "GenSigTimeoutTime" BU_SG_REL_ SCM_FD SG_ 977 BCM_GearPosPSta 1500;
BA_REL_ "GenSigTimeoutTime" BU_SG_REL_ SHVU_RL_FD SG_ 977 BCM_GearPosPSta 1500;
BA_REL_ "GenSigTimeoutTime" BU_SG_REL_ SHVU_RR_FD SG_ 977 BCM_GearPosPSta 1500;
BA_REL_ "GenSigTimeoutTime" BU_SG_REL_ RWPC_FD SG_ 977 BCM_SmkOptTyp 1500;
BA_REL_ "GenSigTimeoutTime" BU_SG_REL_ WPC2_FD SG_ 977 BCM_SmkOptTyp 1500;
BA_REL_ "GenSigTimeoutTime" BU_SG_REL_ WPC_FD SG_ 977 BCM_SmkOptTyp 1500;
BA_REL_ "GenSigTimeoutTime" BU_SG_REL_ RWPC_FD SG_ 914 WPC2_IndSyncVal 1500;
BA_REL_ "GenSigTimeoutTime" BU_SG_REL_ CGW_CCU SG_ 914 USM_CmdWPC2Sta 1500;
BA_REL_ "GenSigTimeoutTime" BU_SG_REL_ CGW_CCU SG_ 914 WPC2_PhnLftWrngSta 1500;
BA_REL_ "GenSigTimeoutTime" BU_SG_REL_ CGW_CCU SG_ 914 WPC2_OptSta 1500;
BA_REL_ "GenSigTimeoutTime" BU_SG_REL_ CGW_CCU SG_ 914 WPC2_SWVerMajor1 1500;
BA_REL_ "GenSigTimeoutTime" BU_SG_REL_ CGW_CCU SG_ 914 WPC2_SWVerMinor1 1500;
BA_REL_ "GenSigTimeoutTime" BU_SG_REL_ CGW_CCU SG_ 914 WPC2_SWVerMinor2 1500;
BA_REL_ "GenSigTimeoutTime" BU_SG_REL_ ARS_FD SG_ 2015 GST_ALL_Byte0 0;
BA_REL_ "GenSigTimeoutTime" BU_SG_REL_ ATS_FD SG_ 2015 GST_ALL_Byte0 0;
BA_REL_ "GenSigTimeoutTime" BU_SG_REL_ FCS_FD SG_ 2015 GST_ALL_Byte0 0;
BA_REL_ "GenSigTimeoutTime" BU_SG_REL_ GW_PSU_3RD_FD SG_ 2015 GST_ALL_Byte0 0;
BA_REL_ "GenSigTimeoutTime" BU_SG_REL_ GW_PSU_AST_FD SG_ 2015 GST_ALL_Byte0 0;
BA_REL_ "GenSigTimeoutTime" BU_SG_REL_ GW_PSU_DRV_FD SG_ 2015 GST_ALL_Byte0 0;
BA_REL_ "GenSigTimeoutTime" BU_SG_REL_ GW_PSU_RL_FD SG_ 2015 GST_ALL_Byte0 0;
BA_REL_ "GenSigTimeoutTime" BU_SG_REL_ GW_PSU_RR_FD SG_ 2015 GST_ALL_Byte0 0;
BA_REL_ "GenSigTimeoutTime" BU_SG_REL_ GW_SAU_DRV_FD SG_ 2015 GST_ALL_Byte0 0;
BA_REL_ "GenSigTimeoutTime" BU_SG_REL_ PSB_FD SG_ 2015 GST_ALL_Byte0 0;
BA_REL_ "GenSigTimeoutTime" BU_SG_REL_ RCM_FD SG_ 2015 GST_ALL_Byte0 0;
BA_REL_ "GenSigTimeoutTime" BU_SG_REL_ RCS_FD SG_ 2015 GST_ALL_Byte0 0;
BA_REL_ "GenSigTimeoutTime" BU_SG_REL_ RWPC_FD SG_ 2015 GST_ALL_Byte0 0;
BA_REL_ "GenSigTimeoutTime" BU_SG_REL_ SCM_FD SG_ 2015 GST_ALL_Byte0 0;
BA_REL_ "GenSigTimeoutTime" BU_SG_REL_ SGU_FD SG_ 2015 GST_ALL_Byte0 0;
BA_REL_ "GenSigTimeoutTime" BU_SG_REL_ SHVU_3RD_FD SG_ 2015 GST_ALL_Byte0 0;
BA_REL_ "GenSigTimeoutTime" BU_SG_REL_ SHVU_CCS_FD SG_ 2015 GST_ALL_Byte0 0;
BA_REL_ "GenSigTimeoutTime" BU_SG_REL_ SHVU_FRNT_FD SG_ 2015 GST_ALL_Byte0 0;
BA_REL_ "GenSigTimeoutTime" BU_SG_REL_ SHVU_REAR_FD SG_ 2015 GST_ALL_Byte0 0;
BA_REL_ "GenSigTimeoutTime" BU_SG_REL_ SHVU_RL_FD SG_ 2015 GST_ALL_Byte0 0;
BA_REL_ "GenSigTimeoutTime" BU_SG_REL_ SHVU_RR_FD SG_ 2015 GST_ALL_Byte0 0;
BA_REL_ "GenSigTimeoutTime" BU_SG_REL_ WPC2_FD SG_ 2015 GST_ALL_Byte0 0;
BA_REL_ "GenSigTimeoutTime" BU_SG_REL_ WPC_FD SG_ 2015 GST_ALL_Byte0 0;
BA_REL_ "GenSigTimeoutTime" BU_SG_REL_ ARS_FD SG_ 2015 GST_ALL_Byte2 0;
BA_REL_ "GenSigTimeoutTime" BU_SG_REL_ ATS_FD SG_ 2015 GST_ALL_Byte2 0;
BA_REL_ "GenSigTimeoutTime" BU_SG_REL_ FCS_FD SG_ 2015 GST_ALL_Byte2 0;
BA_REL_ "GenSigTimeoutTime" BU_SG_REL_ GW_PSU_3RD_FD SG_ 2015 GST_ALL_Byte2 0;
BA_REL_ "GenSigTimeoutTime" BU_SG_REL_ GW_PSU_AST_FD SG_ 2015 GST_ALL_Byte2 0;
BA_REL_ "GenSigTimeoutTime" BU_SG_REL_ GW_PSU_DRV_FD SG_ 2015 GST_ALL_Byte2 0;
BA_REL_ "GenSigTimeoutTime" BU_SG_REL_ GW_PSU_RL_FD SG_ 2015 GST_ALL_Byte2 0;
BA_REL_ "GenSigTimeoutTime" BU_SG_REL_ GW_PSU_RR_FD SG_ 2015 GST_ALL_Byte2 0;
BA_REL_ "GenSigTimeoutTime" BU_SG_REL_ GW_SAU_DRV_FD SG_ 2015 GST_ALL_Byte2 0;
BA_REL_ "GenSigTimeoutTime" BU_SG_REL_ PSB_FD SG_ 2015 GST_ALL_Byte2 0;
BA_REL_ "GenSigTimeoutTime" BU_SG_REL_ RCM_FD SG_ 2015 GST_ALL_Byte2 0;
BA_REL_ "GenSigTimeoutTime" BU_SG_REL_ RCS_FD SG_ 2015 GST_ALL_Byte2 0;
BA_REL_ "GenSigTimeoutTime" BU_SG_REL_ RWPC_FD SG_ 2015 GST_ALL_Byte2 0;
BA_REL_ "GenSigTimeoutTime" BU_SG_REL_ SCM_FD SG_ 2015 GST_ALL_Byte2 0;
BA_REL_ "GenSigTimeoutTime" BU_SG_REL_ SGU_FD SG_ 2015 GST_ALL_Byte2 0;
BA_REL_ "GenSigTimeoutTime" BU_SG_REL_ SHVU_3RD_FD SG_ 2015 GST_ALL_Byte2 0;
BA_REL_ "GenSigTimeoutTime" BU_SG_REL_ SHVU_CCS_FD SG_ 2015 GST_ALL_Byte2 0;
BA_REL_ "GenSigTimeoutTime" BU_SG_REL_ SHVU_FRNT_FD SG_ 2015 GST_ALL_Byte2 0;
BA_REL_ "GenSigTimeoutTime" BU_SG_REL_ SHVU_REAR_FD SG_ 2015 GST_ALL_Byte2 0;
BA_REL_ "GenSigTimeoutTime" BU_SG_REL_ SHVU_RL_FD SG_ 2015 GST_ALL_Byte2 0;
BA_REL_ "GenSigTimeoutTime" BU_SG_REL_ SHVU_RR_FD SG_ 2015 GST_ALL_Byte2 0;
BA_REL_ "GenSigTimeoutTime" BU_SG_REL_ WPC2_FD SG_ 2015 GST_ALL_Byte2 0;
BA_REL_ "GenSigTimeoutTime" BU_SG_REL_ WPC_FD SG_ 2015 GST_ALL_Byte2 0;
BA_REL_ "GenSigTimeoutTime" BU_SG_REL_ ARS_FD SG_ 2015 GST_ALL_Byte3 0;
BA_REL_ "GenSigTimeoutTime" BU_SG_REL_ ATS_FD SG_ 2015 GST_ALL_Byte3 0;
BA_REL_ "GenSigTimeoutTime" BU_SG_REL_ FCS_FD SG_ 2015 GST_ALL_Byte3 0;
BA_REL_ "GenSigTimeoutTime" BU_SG_REL_ GW_PSU_3RD_FD SG_ 2015 GST_ALL_Byte3 0;
BA_REL_ "GenSigTimeoutTime" BU_SG_REL_ GW_PSU_AST_FD SG_ 2015 GST_ALL_Byte3 0;
BA_REL_ "GenSigTimeoutTime" BU_SG_REL_ GW_PSU_DRV_FD SG_ 2015 GST_ALL_Byte3 0;
BA_REL_ "GenSigTimeoutTime" BU_SG_REL_ GW_PSU_RL_FD SG_ 2015 GST_ALL_Byte3 0;
BA_REL_ "GenSigTimeoutTime" BU_SG_REL_ GW_PSU_RR_FD SG_ 2015 GST_ALL_Byte3 0;
BA_REL_ "GenSigTimeoutTime" BU_SG_REL_ GW_SAU_DRV_FD SG_ 2015 GST_ALL_Byte3 0;
BA_REL_ "GenSigTimeoutTime" BU_SG_REL_ PSB_FD SG_ 2015 GST_ALL_Byte3 0;
BA_REL_ "GenSigTimeoutTime" BU_SG_REL_ RCM_FD SG_ 2015 GST_ALL_Byte3 0;
BA_REL_ "GenSigTimeoutTime" BU_SG_REL_ RCS_FD SG_ 2015 GST_ALL_Byte3 0;
BA_REL_ "GenSigTimeoutTime" BU_SG_REL_ RWPC_FD SG_ 2015 GST_ALL_Byte3 0;
BA_REL_ "GenSigTimeoutTime" BU_SG_REL_ SCM_FD SG_ 2015 GST_ALL_Byte3 0;
BA_REL_ "GenSigTimeoutTime" BU_SG_REL_ SGU_FD SG_ 2015 GST_ALL_Byte3 0;
BA_REL_ "GenSigTimeoutTime" BU_SG_REL_ SHVU_3RD_FD SG_ 2015 GST_ALL_Byte3 0;
BA_REL_ "GenSigTimeoutTime" BU_SG_REL_ SHVU_CCS_FD SG_ 2015 GST_ALL_Byte3 0;
BA_REL_ "GenSigTimeoutTime" BU_SG_REL_ SHVU_FRNT_FD SG_ 2015 GST_ALL_Byte3 0;
BA_REL_ "GenSigTimeoutTime" BU_SG_REL_ SHVU_REAR_FD SG_ 2015 GST_ALL_Byte3 0;
BA_REL_ "GenSigTimeoutTime" BU_SG_REL_ SHVU_RL_FD SG_ 2015 GST_ALL_Byte3 0;
BA_REL_ "GenSigTimeoutTime" BU_SG_REL_ SHVU_RR_FD SG_ 2015 GST_ALL_Byte3 0;
BA_REL_ "GenSigTimeoutTime" BU_SG_REL_ WPC2_FD SG_ 2015 GST_ALL_Byte3 0;
BA_REL_ "GenSigTimeoutTime" BU_SG_REL_ WPC_FD SG_ 2015 GST_ALL_Byte3 0;
BA_REL_ "GenSigTimeoutTime" BU_SG_REL_ ARS_FD SG_ 2015 GST_ALL_Byte4 0;
BA_REL_ "GenSigTimeoutTime" BU_SG_REL_ ATS_FD SG_ 2015 GST_ALL_Byte4 0;
BA_REL_ "GenSigTimeoutTime" BU_SG_REL_ FCS_FD SG_ 2015 GST_ALL_Byte4 0;
BA_REL_ "GenSigTimeoutTime" BU_SG_REL_ GW_PSU_3RD_FD SG_ 2015 GST_ALL_Byte4 0;
BA_REL_ "GenSigTimeoutTime" BU_SG_REL_ GW_PSU_AST_FD SG_ 2015 GST_ALL_Byte4 0;
BA_REL_ "GenSigTimeoutTime" BU_SG_REL_ GW_PSU_DRV_FD SG_ 2015 GST_ALL_Byte4 0;
BA_REL_ "GenSigTimeoutTime" BU_SG_REL_ GW_PSU_RL_FD SG_ 2015 GST_ALL_Byte4 0;
BA_REL_ "GenSigTimeoutTime" BU_SG_REL_ GW_PSU_RR_FD SG_ 2015 GST_ALL_Byte4 0;
BA_REL_ "GenSigTimeoutTime" BU_SG_REL_ GW_SAU_DRV_FD SG_ 2015 GST_ALL_Byte4 0;
BA_REL_ "GenSigTimeoutTime" BU_SG_REL_ PSB_FD SG_ 2015 GST_ALL_Byte4 0;
BA_REL_ "GenSigTimeoutTime" BU_SG_REL_ RCM_FD SG_ 2015 GST_ALL_Byte4 0;
BA_REL_ "GenSigTimeoutTime" BU_SG_REL_ RCS_FD SG_ 2015 GST_ALL_Byte4 0;
BA_REL_ "GenSigTimeoutTime" BU_SG_REL_ RWPC_FD SG_ 2015 GST_ALL_Byte4 0;
BA_REL_ "GenSigTimeoutTime" BU_SG_REL_ SCM_FD SG_ 2015 GST_ALL_Byte4 0;
BA_REL_ "GenSigTimeoutTime" BU_SG_REL_ SGU_FD SG_ 2015 GST_ALL_Byte4 0;
BA_REL_ "GenSigTimeoutTime" BU_SG_REL_ SHVU_3RD_FD SG_ 2015 GST_ALL_Byte4 0;
BA_REL_ "GenSigTimeoutTime" BU_SG_REL_ SHVU_CCS_FD SG_ 2015 GST_ALL_Byte4 0;
BA_REL_ "GenSigTimeoutTime" BU_SG_REL_ SHVU_FRNT_FD SG_ 2015 GST_ALL_Byte4 0;
BA_REL_ "GenSigTimeoutTime" BU_SG_REL_ SHVU_REAR_FD SG_ 2015 GST_ALL_Byte4 0;
BA_REL_ "GenSigTimeoutTime" BU_SG_REL_ SHVU_RL_FD SG_ 2015 GST_ALL_Byte4 0;
BA_REL_ "GenSigTimeoutTime" BU_SG_REL_ SHVU_RR_FD SG_ 2015 GST_ALL_Byte4 0;
BA_REL_ "GenSigTimeoutTime" BU_SG_REL_ WPC2_FD SG_ 2015 GST_ALL_Byte4 0;
BA_REL_ "GenSigTimeoutTime" BU_SG_REL_ WPC_FD SG_ 2015 GST_ALL_Byte4 0;
BA_REL_ "GenSigTimeoutTime" BU_SG_REL_ ARS_FD SG_ 2015 GST_ALL_Byte5 0;
BA_REL_ "GenSigTimeoutTime" BU_SG_REL_ ATS_FD SG_ 2015 GST_ALL_Byte5 0;
BA_REL_ "GenSigTimeoutTime" BU_SG_REL_ FCS_FD SG_ 2015 GST_ALL_Byte5 0;
BA_REL_ "GenSigTimeoutTime" BU_SG_REL_ GW_PSU_3RD_FD SG_ 2015 GST_ALL_Byte5 0;
BA_REL_ "GenSigTimeoutTime" BU_SG_REL_ GW_PSU_AST_FD SG_ 2015 GST_ALL_Byte5 0;
BA_REL_ "GenSigTimeoutTime" BU_SG_REL_ GW_PSU_DRV_FD SG_ 2015 GST_ALL_Byte5 0;
BA_REL_ "GenSigTimeoutTime" BU_SG_REL_ GW_PSU_RL_FD SG_ 2015 GST_ALL_Byte5 0;
BA_REL_ "GenSigTimeoutTime" BU_SG_REL_ GW_PSU_RR_FD SG_ 2015 GST_ALL_Byte5 0;
BA_REL_ "GenSigTimeoutTime" BU_SG_REL_ GW_SAU_DRV_FD SG_ 2015 GST_ALL_Byte5 0;
BA_REL_ "GenSigTimeoutTime" BU_SG_REL_ PSB_FD SG_ 2015 GST_ALL_Byte5 0;
BA_REL_ "GenSigTimeoutTime" BU_SG_REL_ RCM_FD SG_ 2015 GST_ALL_Byte5 0;
BA_REL_ "GenSigTimeoutTime" BU_SG_REL_ RCS_FD SG_ 2015 GST_ALL_Byte5 0;
BA_REL_ "GenSigTimeoutTime" BU_SG_REL_ RWPC_FD SG_ 2015 GST_ALL_Byte5 0;
BA_REL_ "GenSigTimeoutTime" BU_SG_REL_ SCM_FD SG_ 2015 GST_ALL_Byte5 0;
BA_REL_ "GenSigTimeoutTime" BU_SG_REL_ SGU_FD SG_ 2015 GST_ALL_Byte5 0;
BA_REL_ "GenSigTimeoutTime" BU_SG_REL_ SHVU_3RD_FD SG_ 2015 GST_ALL_Byte5 0;
BA_REL_ "GenSigTimeoutTime" BU_SG_REL_ SHVU_CCS_FD SG_ 2015 GST_ALL_Byte5 0;
BA_REL_ "GenSigTimeoutTime" BU_SG_REL_ SHVU_FRNT_FD SG_ 2015 GST_ALL_Byte5 0;
BA_REL_ "GenSigTimeoutTime" BU_SG_REL_ SHVU_REAR_FD SG_ 2015 GST_ALL_Byte5 0;
BA_REL_ "GenSigTimeoutTime" BU_SG_REL_ SHVU_RL_FD SG_ 2015 GST_ALL_Byte5 0;
BA_REL_ "GenSigTimeoutTime" BU_SG_REL_ SHVU_RR_FD SG_ 2015 GST_ALL_Byte5 0;
BA_REL_ "GenSigTimeoutTime" BU_SG_REL_ WPC2_FD SG_ 2015 GST_ALL_Byte5 0;
BA_REL_ "GenSigTimeoutTime" BU_SG_REL_ WPC_FD SG_ 2015 GST_ALL_Byte5 0;
BA_REL_ "GenSigTimeoutTime" BU_SG_REL_ ARS_FD SG_ 2015 GST_ALL_Byte6 0;
BA_REL_ "GenSigTimeoutTime" BU_SG_REL_ ATS_FD SG_ 2015 GST_ALL_Byte6 0;
BA_REL_ "GenSigTimeoutTime" BU_SG_REL_ FCS_FD SG_ 2015 GST_ALL_Byte6 0;
BA_REL_ "GenSigTimeoutTime" BU_SG_REL_ GW_PSU_3RD_FD SG_ 2015 GST_ALL_Byte6 0;
BA_REL_ "GenSigTimeoutTime" BU_SG_REL_ GW_PSU_AST_FD SG_ 2015 GST_ALL_Byte6 0;
BA_REL_ "GenSigTimeoutTime" BU_SG_REL_ GW_PSU_DRV_FD SG_ 2015 GST_ALL_Byte6 0;
BA_REL_ "GenSigTimeoutTime" BU_SG_REL_ GW_PSU_RL_FD SG_ 2015 GST_ALL_Byte6 0;
BA_REL_ "GenSigTimeoutTime" BU_SG_REL_ GW_PSU_RR_FD SG_ 2015 GST_ALL_Byte6 0;
BA_REL_ "GenSigTimeoutTime" BU_SG_REL_ GW_SAU_DRV_FD SG_ 2015 GST_ALL_Byte6 0;
BA_REL_ "GenSigTimeoutTime" BU_SG_REL_ PSB_FD SG_ 2015 GST_ALL_Byte6 0;
BA_REL_ "GenSigTimeoutTime" BU_SG_REL_ RCM_FD SG_ 2015 GST_ALL_Byte6 0;
BA_REL_ "GenSigTimeoutTime" BU_SG_REL_ RCS_FD SG_ 2015 GST_ALL_Byte6 0;
BA_REL_ "GenSigTimeoutTime" BU_SG_REL_ RWPC_FD SG_ 2015 GST_ALL_Byte6 0;
BA_REL_ "GenSigTimeoutTime" BU_SG_REL_ SCM_FD SG_ 2015 GST_ALL_Byte6 0;
BA_REL_ "GenSigTimeoutTime" BU_SG_REL_ SGU_FD SG_ 2015 GST_ALL_Byte6 0;
BA_REL_ "GenSigTimeoutTime" BU_SG_REL_ SHVU_3RD_FD SG_ 2015 GST_ALL_Byte6 0;
BA_REL_ "GenSigTimeoutTime" BU_SG_REL_ SHVU_CCS_FD SG_ 2015 GST_ALL_Byte6 0;
BA_REL_ "GenSigTimeoutTime" BU_SG_REL_ SHVU_FRNT_FD SG_ 2015 GST_ALL_Byte6 0;
BA_REL_ "GenSigTimeoutTime" BU_SG_REL_ SHVU_REAR_FD SG_ 2015 GST_ALL_Byte6 0;
BA_REL_ "GenSigTimeoutTime" BU_SG_REL_ SHVU_RL_FD SG_ 2015 GST_ALL_Byte6 0;
BA_REL_ "GenSigTimeoutTime" BU_SG_REL_ SHVU_RR_FD SG_ 2015 GST_ALL_Byte6 0;
BA_REL_ "GenSigTimeoutTime" BU_SG_REL_ WPC2_FD SG_ 2015 GST_ALL_Byte6 0;
BA_REL_ "GenSigTimeoutTime" BU_SG_REL_ WPC_FD SG_ 2015 GST_ALL_Byte6 0;
BA_REL_ "GenSigTimeoutTime" BU_SG_REL_ ARS_FD SG_ 2015 GST_ALL_Byte7 0;
BA_REL_ "GenSigTimeoutTime" BU_SG_REL_ ATS_FD SG_ 2015 GST_ALL_Byte7 0;
BA_REL_ "GenSigTimeoutTime" BU_SG_REL_ FCS_FD SG_ 2015 GST_ALL_Byte7 0;
BA_REL_ "GenSigTimeoutTime" BU_SG_REL_ GW_PSU_3RD_FD SG_ 2015 GST_ALL_Byte7 0;
BA_REL_ "GenSigTimeoutTime" BU_SG_REL_ GW_PSU_AST_FD SG_ 2015 GST_ALL_Byte7 0;
BA_REL_ "GenSigTimeoutTime" BU_SG_REL_ GW_PSU_DRV_FD SG_ 2015 GST_ALL_Byte7 0;
BA_REL_ "GenSigTimeoutTime" BU_SG_REL_ GW_PSU_RL_FD SG_ 2015 GST_ALL_Byte7 0;
BA_REL_ "GenSigTimeoutTime" BU_SG_REL_ GW_PSU_RR_FD SG_ 2015 GST_ALL_Byte7 0;
BA_REL_ "GenSigTimeoutTime" BU_SG_REL_ GW_SAU_DRV_FD SG_ 2015 GST_ALL_Byte7 0;
BA_REL_ "GenSigTimeoutTime" BU_SG_REL_ PSB_FD SG_ 2015 GST_ALL_Byte7 0;
BA_REL_ "GenSigTimeoutTime" BU_SG_REL_ RCM_FD SG_ 2015 GST_ALL_Byte7 0;
BA_REL_ "GenSigTimeoutTime" BU_SG_REL_ RCS_FD SG_ 2015 GST_ALL_Byte7 0;
BA_REL_ "GenSigTimeoutTime" BU_SG_REL_ RWPC_FD SG_ 2015 GST_ALL_Byte7 0;
BA_REL_ "GenSigTimeoutTime" BU_SG_REL_ SCM_FD SG_ 2015 GST_ALL_Byte7 0;
BA_REL_ "GenSigTimeoutTime" BU_SG_REL_ SGU_FD SG_ 2015 GST_ALL_Byte7 0;
BA_REL_ "GenSigTimeoutTime" BU_SG_REL_ SHVU_3RD_FD SG_ 2015 GST_ALL_Byte7 0;
BA_REL_ "GenSigTimeoutTime" BU_SG_REL_ SHVU_CCS_FD SG_ 2015 GST_ALL_Byte7 0;
BA_REL_ "GenSigTimeoutTime" BU_SG_REL_ SHVU_FRNT_FD SG_ 2015 GST_ALL_Byte7 0;
BA_REL_ "GenSigTimeoutTime" BU_SG_REL_ SHVU_REAR_FD SG_ 2015 GST_ALL_Byte7 0;
BA_REL_ "GenSigTimeoutTime" BU_SG_REL_ SHVU_RL_FD SG_ 2015 GST_ALL_Byte7 0;
BA_REL_ "GenSigTimeoutTime" BU_SG_REL_ SHVU_RR_FD SG_ 2015 GST_ALL_Byte7 0;
BA_REL_ "GenSigTimeoutTime" BU_SG_REL_ WPC2_FD SG_ 2015 GST_ALL_Byte7 0;
BA_REL_ "GenSigTimeoutTime" BU_SG_REL_ WPC_FD SG_ 2015 GST_ALL_Byte7 0;
BA_REL_ "GenSigTimeoutTime" BU_SG_REL_ ARS_FD SG_ 2015 GST_ALL_Byte1 0;
BA_REL_ "GenSigTimeoutTime" BU_SG_REL_ ATS_FD SG_ 2015 GST_ALL_Byte1 0;
BA_REL_ "GenSigTimeoutTime" BU_SG_REL_ FCS_FD SG_ 2015 GST_ALL_Byte1 0;
BA_REL_ "GenSigTimeoutTime" BU_SG_REL_ GW_PSU_3RD_FD SG_ 2015 GST_ALL_Byte1 0;
BA_REL_ "GenSigTimeoutTime" BU_SG_REL_ GW_PSU_AST_FD SG_ 2015 GST_ALL_Byte1 0;
BA_REL_ "GenSigTimeoutTime" BU_SG_REL_ GW_PSU_DRV_FD SG_ 2015 GST_ALL_Byte1 0;
BA_REL_ "GenSigTimeoutTime" BU_SG_REL_ GW_PSU_RL_FD SG_ 2015 GST_ALL_Byte1 0;
BA_REL_ "GenSigTimeoutTime" BU_SG_REL_ GW_PSU_RR_FD SG_ 2015 GST_ALL_Byte1 0;
BA_REL_ "GenSigTimeoutTime" BU_SG_REL_ GW_SAU_DRV_FD SG_ 2015 GST_ALL_Byte1 0;
BA_REL_ "GenSigTimeoutTime" BU_SG_REL_ PSB_FD SG_ 2015 GST_ALL_Byte1 0;
BA_REL_ "GenSigTimeoutTime" BU_SG_REL_ RCM_FD SG_ 2015 GST_ALL_Byte1 0;
BA_REL_ "GenSigTimeoutTime" BU_SG_REL_ RCS_FD SG_ 2015 GST_ALL_Byte1 0;
BA_REL_ "GenSigTimeoutTime" BU_SG_REL_ RWPC_FD SG_ 2015 GST_ALL_Byte1 0;
BA_REL_ "GenSigTimeoutTime" BU_SG_REL_ SCM_FD SG_ 2015 GST_ALL_Byte1 0;
BA_REL_ "GenSigTimeoutTime" BU_SG_REL_ SGU_FD SG_ 2015 GST_ALL_Byte1 0;
BA_REL_ "GenSigTimeoutTime" BU_SG_REL_ SHVU_3RD_FD SG_ 2015 GST_ALL_Byte1 0;
BA_REL_ "GenSigTimeoutTime" BU_SG_REL_ SHVU_CCS_FD SG_ 2015 GST_ALL_Byte1 0;
BA_REL_ "GenSigTimeoutTime" BU_SG_REL_ SHVU_FRNT_FD SG_ 2015 GST_ALL_Byte1 0;
BA_REL_ "GenSigTimeoutTime" BU_SG_REL_ SHVU_REAR_FD SG_ 2015 GST_ALL_Byte1 0;
BA_REL_ "GenSigTimeoutTime" BU_SG_REL_ SHVU_RL_FD SG_ 2015 GST_ALL_Byte1 0;
BA_REL_ "GenSigTimeoutTime" BU_SG_REL_ SHVU_RR_FD SG_ 2015 GST_ALL_Byte1 0;
BA_REL_ "GenSigTimeoutTime" BU_SG_REL_ WPC2_FD SG_ 2015 GST_ALL_Byte1 0;
BA_REL_ "GenSigTimeoutTime" BU_SG_REL_ WPC_FD SG_ 2015 GST_ALL_Byte1 0;
VAL_ 813 SBCM_DRV_FD_Crc1Val 0 "0x0x0~0xFFFF:CRCValue" 65535 "0x0x0~0xFFFF:CRCValue" ;
VAL_ 813 Latch_TypeOption_DRV 0 "Off" 1 "On" 2 "RESERVED" 3 "Error Indicator" ;
VAL_ 813 DRV_SWFailAlarm 0 "Off" 1 "On" 2 "RESERVED" 3 "Error Indicator" ;
VAL_ 813 USM_PwrDRApprOpnSetSta 0 "Default" 1 "Off" 2 "On" 3 "RESERVED" ;
VAL_ 813 USM_PwrDRApprOpnSetOpt 0 "Default" 1 "Off" 2 "On" 3 "RESERVED" ;
VAL_ 813 USM_PwrDRCloseByRKELockSta 0 "Default" 1 "Off" 2 "On" 3 "RESERVED" ;
VAL_ 813 USM_PwrDRCloseByRKELockOpt 0 "Default" 1 "Off" 2 "On" 3 "RESERVED" ;
VAL_ 813 USM_PwrDRCloseByBrakeSta 0 "Default" 1 "Off" 2 "On" 3 "RESERVED" ;
VAL_ 813 USM_PwrDRCloseByBrakeOpt 0 "Default" 1 "Off" 2 "On" 3 "RESERVED" ;
VAL_ 813 USM_PwrDRBuzzerSta 0 "Default" 1 "Off" 2 "On" 3 "RESERVED" ;
VAL_ 813 USM_PwrDRBuzzerOpt 0 "Default" 1 "Off" 2 "On" 3 "RESERVED" ;
VAL_ 813 PDS_TypeOption_DRV 0 "Off" 1 "All Door" 2 "Front Only" 3 "Rear Only" ;
VAL_ 813 C_DrvDoorApproachOpen 0 "Default" 1 "Approach Open Request" 2 "Approach Open Stop" 3 "RESERVED" ;
VAL_ 813 C_DrvDoorApproachClose 0 "Default" 1 "Approach Close Request" 2 "Approach Close Stop" 3 "RESERVED" ;
VAL_ 813 DoorLock_PDSLkSwSta_DRV 0 "Default" 1 "Lock" 2 "RESERVED" 3 "Error Indicator" ;
VAL_ 813 SBCM_DRV_DiagSta 0 "Default" 1 "Normal Operation" 2 "DRV Indicator Circuit Failure" 3 "RESERVED" ;
VAL_ 813 DoorLock_CtrlDrLkUnLkSwSta_SBCM 0 "Off" 1 "On" 2 "RESERVED" 3 "Error Indicator" ;
VAL_ 813 SBCM_PsvDrLkReq 0 "None" 1 "Lock" 2 "Passive Trunk Lock" 3 "RESERVED" ;
VAL_ 813 CDMAutoWashModeSet_SBCM 0 "Default" 1 "CDM Auto Wash Mode Off" 2 "CDM Auto Wash Mode On" 3 "RESERVED" 4 "RESERVED" 5 "RESERVED" 6 "RESERVED" 7 "Invalid" ;
VAL_ 813 USM_DrvGhostDoorSta 0 "Default" 1 "Off" 2 "On" 3 "RESERVED" ;
VAL_ 813 Mirror_LH_FoldingSta 0 "Off" 1 "Folding" 2 "RESERVED" 3 "Error Indicator" ;
VAL_ 813 Mirror_LH_UnfoldingSta 0 "Off" 1 "Unfolding" 2 "RESERVED" 3 "Error Indicator" ;
VAL_ 813 DRV_CrashMRActAlarm 0 "Off" 1 "On" 2 "RESERVED" 3 "Error Indicator" ;
VAL_ 813 AFH_DRV_FldUnFldSta 0 "Invalid" 1 "Fold" 2 "Unfold" 3 "Inprogress" ;
VAL_ 813 SBCM_DRV_FD_AlvCnt1Val 0 "0x0x0~0xFF:AlvCntValue" 255 "0x0x0~0xFF:AlvCntValue" ;
VAL_ 813 MirrorFldReq 0 "Default" 1 "Folding Request" 2 "Unfolding Request" 3 "RESERVED" ;
VAL_ 813 OMU_TypeOption_DRV 0 "Off" 1 "On" 2 "RESERVED" 3 "Error Indicator" ;
VAL_ 813 IMS_OSMirPlayBackSta_LH 0 "Stop" 1 "Play 1" 2 "Play 2" 3 "Play 3" 4 "SmartIMS" 5 "Profile 1" 6 "Profile 2" 7 "Guest" 8 "RESERVED" 9 "RESERVED" 10 "RESERVED" 11 "RESERVED" 12 "RESERVED" 13 "RESERVED" 14 "RESERVED" 15 "Error Indicator" ;
VAL_ 813 ECMMRR_PLUS 0 "0x0x0~0x7D:0~1.25 V" 125 "0x0x0~0x7D:0~1.25 V" 126 "0x7E~0xFE:RESERVED" 254 "0x7E~0xFE:RESERVED" 255 "RESERVED" ;
VAL_ 813 EHL_TxInfo_SBCM_DRV 0 "Default" 1 "EHL_DRV_Close" 2 "EHL_DRV_Half" 3 "EHL_DRV_Open" 4 "EHL_DRV_RetryFlag" 5 "EHL_DRV_ErrorIndicator" 6 "EHL_DRV_Opening" 7 "Invalid" ;
VAL_ 813 IMS_OSMirPlayBackSta_LH_New 0 "Stop" 1 "Play 1" 2 "Play 2" 3 "Play 3" 4 "Smart IMS" 5 "Profile 1" 6 "Profile 2" 7 "Profile 3" 8 "Profile 4" 9 "Profile 5" 10 "Profile 6" 11 "Profile 7" 12 "Profile 8" 13 "Profile 9" 14 "Guest" 15 "Error Indicator" ;
VAL_ 813 CDM_InsideOpnSwSta 0 "Off" 1 "On" 2 "RESERVED" 3 "Error Indicator" ;
VAL_ 813 CDM_TypeOption 0 "Off" 1 "On" 2 "On_2EA" 3 "Error Indicator" ;
VAL_ 813 CDM_ImmeChgSw_SBCM 0 "Default" 1 "Off" 2 "On" 3 "RESERVED" ;
VAL_ 813 CDM_FobSrchReq_DRV 0 "Off" 1 "On" 2 "RESERVED" 3 "Error Indicator" ;
VAL_ 813 CDM_OpnClsState_SBCM 0 "Default" 1 "Open" 2 "Close" 3 "RESERVED" ;
VAL_ 813 CDM_WarnMsg_SBCM 0 "Default" 1 "Normal" 2 "ChargeDoorErrorState" 3 "RESERVED" ;
VAL_ 813 CDM_AutoWashModeSta 0 "Default" 1 "CDM Auto Wash Mode Off (Ready)" 2 "CDM Auto Wash Mode Off (Error)" 3 "CDM Auto Wash Mode On" 4 "RESERVED" 5 "RESERVED" 6 "RESERVED" 7 "Invalid" ;
VAL_ 813 CDM_CmdStatus_SBCM 0 "Open (AVN)" 1 "Open (SMK)" 2 "Open (Sensor Switch)" 3 "Open (Command Hard Switch)" 4 "Open (Anti - Pinch)" 5 "Close (AVN)" 6 "Close (SMK)" 7 "Close (Assist Mode)" 8 "Close (Command Hard Switch)" 9 "Close (Connector)" 10 "Close (Gear Position)" 11 "Close (Time Over)" 12 "Close (Anti - Pinch)" 13 "Close (Sensor Switch)" 14 "Stall (Stop)" 15 "Invalid" ;
VAL_ 813 CDM_OutsideOpnSwSta 0 "Default" 1 "Push" 2 "RESERVED" 3 "Invalid" ;
VAL_ 813 PwrDRBuzzerOut_DRV 0 "OFF" 1 "Open" 2 "Close" 3 "Warning" ;
VAL_ 813 Warn_HoodSwSta_SBCM 0 "Off" 1 "On" 2 "RESERVED" 3 "Error Indicator" ;
VAL_ 813 Hood_TypeOption 0 "Off (Mechanical hood latch is applied)" 1 "On (E-Hood latch is applied)" 2 "RESERVED" 3 "Error Indicator" ;
VAL_ 813 SBCM_FrunkSta 0 "Default" 1 "Valid" 2 "RESERVED" 3 "Error Indicator" ;
VAL_ 813 Warn_HoodSwFullSta_SBCM 0 "Off" 1 "On" 2 "RESERVED" 3 "Error Indicator" ;
VAL_ 813 FrunkWarning_SBCM 0 "Off" 1 "On" 2 "RESERVED" 3 "Error Indicator" ;
VAL_ 813 SBCM_Longkey_DRVDrAtClsSwSta 0 "Default" 1 "Off" 2 "On" 3 "Error Indicator" ;
VAL_ 813 FrunkReleaseSwSta_SBCM 0 "Off" 1 "HalfRelease" 2 "FullRelease" 3 "SwitchError" ;
VAL_ 813 PwrDRClosingDRVDrSta 0 "Default" 1 "Close" 2 "Open" 3 "Stop(during Close)" 4 "Stop(during Open)" 5 "RESERVED" 6 "RESERVED" 7 "Invalid" ;
VAL_ 813 Drv_DrLkRetryFail_SBCM 0 "Normal" 1 "Fail" 2 "RESERVED" 3 "RESERVED" ;
VAL_ 813 CDM_GbtImmeChgSw_SBCM 0 "Default" 1 "Off" 2 "On" 3 "RESERVED" ;
VAL_ 813 CDM_GbtOpnClsState_SBCM 0 "Default" 1 "Open" 2 "Close" 3 "RESERVED" ;
VAL_ 813 CDM_GbtWarnMsg_SBCM 0 "Default" 1 "Normal" 2 "ChargeDoorErrorState" 3 "RESERVED" ;
VAL_ 813 CDM_GbtOutsideOpnSwSta 0 "Default" 1 "Push" 2 "RESERVED" 3 "Invalid" ;
VAL_ 813 DoorLock_DrvLkOutSta_SBCM 0 "Off" 1 "On" 2 "Not Used" 3 "Error Indicator" ;
VAL_ 813 FrunkEmergencySwSta_SBCM 0 "Off" 1 "On" 2 "Not Used" 3 "Error Indicator" ;
VAL_ 813 DRV_DetectObj_warn_LH 0 "Detect Left Warning OFF" 1 "Detect Left Warning ON" 2 "RESERVED" 3 "RESERVED" ;
VAL_ 813 PwrDROpenClosingDdvSdDRSta 0 "Default" 1 "Close" 2 "Open" 3 "Stop(during Close)" 4 "Stop(during Open)" 5 "RESERVED" 6 "RESERVED" 7 "Invalid" ;
VAL_ 813 PwrDRBuzzerOut_DRV_New 0 "OFF" 1 "Open" 2 "Close" 3 "Warning1" 4 "Warning2" ;
VAL_ 813 Coach_TypeOption_DRV 0 "Off" 1 "On" 2 "Not Used" 3 "Error Indicator" ;
VAL_ 813 PwrDrSta_Drv 0 "Unavailable" 1 "Available" 2 "RESERVED" 3 "Error Indicator" ;
VAL_ 813 PwrDrSta_DrvSd 0 "Unavailable" 1 "Available" 2 "RESERVED" 3 "Error Indicator" ;
VAL_ 813 USM_PwrDrOpnTypSta 0 "Default" 1 "Pop-up" 2 "Full Open" 3 "RESERVED" ;
VAL_ 813 DischrgDr_OpnClsState_SBCM 0 "Default" 1 "Open" 2 "Close" 3 "Invalid" ;
VAL_ 813 SBCM_FL_DoorAngle 0 "0° - 90°" 1 "0° - 90°" 2 "0° - 90°" 3 "0° - 90°" 4 "0° - 90°" 5 "0° - 90°" 6 "0° - 90°" 7 "0° - 90°" 8 "0° - 90°" 9 "0° - 90°" 10 "0° - 90°" 11 "0° - 90°" 12 "0° - 90°" 13 "0° - 90°" 14 "0° - 90°" 15 "0° - 90°" 16 "0° - 90°" 17 "0° - 90°" 18 "0° - 90°" 19 "0° - 90°" 20 "0° - 90°" 21 "0° - 90°" 22 "0° - 90°" 23 "0° - 90°" 24 "0° - 90°" 25 "0° - 90°" 26 "0° - 90°" 27 "0° - 90°" 28 "0° - 90°" 29 "0° - 90°" 30 "0° - 90°" 31 "0° - 90°" 32 "0° - 90°" 33 "0° - 90°" 34 "0° - 90°" 35 "0° - 90°" 36 "0° - 90°" 37 "0° - 90°" 38 "0° - 90°" 39 "0° - 90°" 40 "0° - 90°" 41 "0° - 90°" 42 "0° - 90°" 43 "0° - 90°" 44 "0° - 90°" 45 "0° - 90°" 46 "0° - 90°" 47 "0° - 90°" 48 "0° - 90°" 49 "0° - 90°" 50 "0° - 90°" 51 "0° - 90°" 52 "0° - 90°" 53 "0° - 90°" 54 "0° - 90°" 55 "0° - 90°" 56 "0° - 90°" 57 "0° - 90°" 58 "0° - 90°" 59 "0° - 90°" 60 "0° - 90°" 61 "0° - 90°" 62 "0° - 90°" 63 "0° - 90°" 64 "0° - 90°" 65 "0° - 90°" 66 "0° - 90°" 67 "0° - 90°" 68 "0° - 90°" 69 "0° - 90°" 70 "0° - 90°" 71 "0° - 90°" 72 "0° - 90°" 73 "0° - 90°" 74 "0° - 90°" 75 "0° - 90°" 76 "0° - 90°" 77 "0° - 90°" 78 "0° - 90°" 79 "0° - 90°" 80 "0° - 90°" 81 "0° - 90°" 82 "0° - 90°" 83 "0° - 90°" 84 "0° - 90°" 85 "0° - 90°" 86 "0° - 90°" 87 "0° - 90°" 88 "0° - 90°" 89 "0° - 90°" 90 "0° - 90°" 91 "Invalid" 92 "Invalid" 93 "Invalid" 94 "Invalid" 95 "Invalid" 96 "Invalid" 97 "Invalid" 98 "Invalid" 99 "Invalid" 100 "Unknown" 101 "Invalid" 102 "Invalid" 103 "Invalid" 104 "Invalid" 105 "Invalid" 106 "Invalid" 107 "Invalid" 108 "Invalid" 109 "Invalid" 110 "Invalid" 111 "Invalid" 112 "Invalid" 113 "Invalid" 114 "Invalid" 115 "Invalid" 116 "Invalid" 117 "Invalid" 118 "Invalid" 119 "Invalid" 120 "Invalid" 121 "Invalid" 122 "Invalid" 123 "Invalid" 124 "Invalid" 125 "Invalid" 126 "Invalid" 127 "Invalid" ;
VAL_ 813 SBCM_DoorType_DRV 0 "Two Door" 1 "Four Door" 2 "Not Used" 3 "Error Indicator" ;
VAL_ 813 CDM_DrType_DRV 0 "None" 1 "Electric" 2 "Manual" 3 "RESERVED" ;
VAL_ 813 DRVDoorPushAlarm 0 "Off" 1 "On" 2 "RESERVED" 3 "Error Indicator" ;
VAL_ 813 DRV_CrashUnlockCmd 0 "Off" 1 "Unlock(Crash)" ;
VAL_ 813 C_ApprOpenStatus 0 "Approach Open Off" 1 "Approach Open On" ;
VAL_ 813 DoorLock_DrvKeyLkSwSta_SBCM 0 "Off" 1 "Lock" 2 "RESERVED" 3 "Error Indicator" ;
VAL_ 813 DoorLock_DrvKeyUnLkSwSta_SBCM 0 "Off" 1 "Unlock" 2 "RESERVED" 3 "Error Indicator" ;
VAL_ 813 Warn_DrvDrSwSta_SBCM 0 "Close" 1 "Open" 2 "RESERVED" 3 "Error Indicator" ;
VAL_ 813 DoorLock_DrvDrUnLkSta_SBCM 0 "Lock" 1 "Unlock" 2 "RESERVED" 3 "Error Indicator" ;
VAL_ 813 DRV_SEAWarn_LH 0 "SEA Left Warning OFF" 1 "SEA Left Warning ON" 2 "RESERVED" 3 "RESERVED" ;
VAL_ 813 DRV_SEAWarn_RH 0 "SEA Right Warning OFF" 1 "SEA Right  Warning ON" 2 "RESERVED" 3 "RESERVED" ;
VAL_ 813 DRV_SEWWarn_LH 0 "SEW Left Warning OFF" 1 "SEW Left Warning ON" 2 "RESERVED" 3 "RESERVED" ;
VAL_ 813 DRV_SEWWarn_RH 0 "SEW Right Warning OFF" 1 "SEW Right Warning ON" 2 "RESERVED" 3 "RESERVED" ;
VAL_ 813 DRV_MRActivationAlarm 0 "Off" 1 "On" 2 "RESERVED" 3 "Error Indicator" ;
VAL_ 813 DRV_ReleaseWarn 0 "Release Warning OFF" 1 "Release Warning ON" 2 "RESERVED" 3 "RESERVED" ;
VAL_ 994 PDC_FD_Crc3Val 0 "0x0x0~0xFFFF:CRCValue" 65535 "0x0x0~0xFFFF:CRCValue" ;
VAL_ 994 PDC_FD_AlvCnt3Val 0 "0x0x0~0xFF:AlvCntValue" 255 "0x0x0~0xFF:AlvCntValue" ;
VAL_ 994 Warn_DrvDrSwSta 0 "Close" 1 "Open" 2 "Not Used" 3 "Error Indicator" ;
VAL_ 994 Warn_AsstDrSwSta 0 "Close" 1 "Open" 2 "Not Used" 3 "Error Indicator" ;
VAL_ 994 Warn_RrLftDrSwSta 0 "Close" 1 "Open" 2 "Not Used" 3 "Error Indicator" ;
VAL_ 994 Warn_RrRtDrSwSta 0 "Close" 1 "Open" 2 "Not Used" 3 "Error Indicator" ;
VAL_ 994 Warn_HoodSwSta 0 "Off" 1 "On" 2 "Not Used" 3 "Error Indicator" ;
VAL_ 994 DoorLock_DrvDrUnLkSta 0 "Lock" 1 "Unlock" 2 "Not Used" 3 "Error Indicator" ;
VAL_ 994 DoorLock_AsstDrUnLkSta 0 "Lock" 1 "Unlock" 2 "Not Used" 3 "Error Indicator" ;
VAL_ 994 DoorLock_RrLftDrUnLkSta 0 "Lock" 1 "Unlock" 2 "Not Used" 3 "Error Indicator" ;
VAL_ 994 DoorLock_RrRtDrUnLkSta 0 "Lock" 1 "Unlock" 2 "Not Used" 3 "Error Indicator" ;
VAL_ 994 DoorLock_DrvKeyLkSwSta 0 "Off" 1 "Lock" 2 "Not Used" 3 "Error Indicator" ;
VAL_ 994 DoorLock_DrvKeyUnLkSwSta 0 "Off" 1 "Unlock" 2 "Not Used" 3 "Error Indicator" ;
VAL_ 994 DoorLock_CtrlDrLkSwSta_ICU 0 "Off" 1 "On(Lock On)" 2 "Not Used" 3 "Error Indicator" ;
VAL_ 994 DoorLock_CtrlDrUnLkSwSta_ICU 0 "Off" 1 "On(Unlock On)" 2 "Not Used" 3 "Error Indicator" ;
VAL_ 994 DoorLock_CtrlDrLkUnLkSwSta_ICU 0 "Off" 1 "On" 2 "Not Used" 3 "Error Indicator" ;
VAL_ 994 C_CrashUnlockState 0 "Off" 1 "Unlock(Crash)" 2 "RESERVED" 3 "RESERVED" ;
VAL_ 994 Lamp_LedHdLmpSta 0 "LED Headlamp is in nornal condition" 1 "RESERVED" 2 "LED Fail" 3 "RESERVED" ;
VAL_ 994 Warn_ChaDrSwFrtSta 0 "Default" 1 "Close" 2 "Open" 3 "Error Indicator" ;
VAL_ 994 Warn_ChaDrSwRrSta 0 "Default" 1 "Close" 2 "Open" 3 "Error Indicator" ;
VAL_ 1242 CLU_Crc9Val 0 "0x0x0~0xFFFF:CRCValue" 65535 "0x0x0~0xFFFF:CRCValue" ;
VAL_ 1242 CLU_AlvCnt9Val 0 "0x0x0~0xFF:AlvCntValue" 255 "0x0x0~0xFF:AlvCntValue" ;
VAL_ 1242 USM_MdLmpClrSetReq 0 "Default" 1 "color 1" 2 "color 2" 3 "color 3" 4 "color 4" 5 "color 5" 6 "color 6" 7 "color 7" 8 "color 8" 9 "color 9" 10 "color 10" 11 "reserved" 12 "reserved" 13 "reserved" 14 "reserved" 15 "Invalid" ;
VAL_ 1242 USM_RrWiperRevSetReq 0 "Default" 1 "Rear Wiper(reverse) Off" 2 "Rear Wiper(reverse) On" 3 "Invalid" ;
VAL_ 1242 USM_RrStRemindSetReq 0 "Default" 1 "Off(Disable)" 2 "On(Enable)" 3 "Invalid" ;
VAL_ 1242 USM_RrWpcSetReq 0 "Default" 1 "Off(Disable)" 2 "On(Enable)" 3 "Invalid" ;
VAL_ 1242 USM_WpcSetReq 0 "Default" 1 "Off(Disable)" 2 "On(Enable)" 3 "Invalid" ;
VAL_ 1242 USM_SeqLmpSetReq 0 "Default" 1 "Off" 2 "On" 3 "Invalid" ;
VAL_ 1242 USM_UnlckWlcmSetReq 0 "Default Value" 1 "Off" 2 "On" 3 "Invalid" ;
VAL_ 1242 USM_SmrtWlcmSetReq 0 "Default Value" 1 "Off" 2 "On" 3 "Invalid" ;
VAL_ 1242 USM_UipSetReq 0 "Default(USM미구성)" 1 "Off(Disable)" 2 "On(Enable)" 3 "Invalid" ;
VAL_ 1242 USM_DigitalKeyEnblSetReq 0 "Default(미구성)" 1 "Disable" 2 "Enable" 3 "Invalid" ;
VAL_ 1242 USM_OwnerPhnRegSetReq 0 "Default(미구성)" 1 "Deleter" 2 "Register" 3 "Invalid" ;
VAL_ 1242 USM_NFCCard1RegSetReq 0 "Default(미구성)" 1 "Disable" 2 "Enable" 3 "Invalid" ;
VAL_ 1242 USM_NFCCard2RegSetReq 0 "Default(미구성)" 1 "Disable" 2 "Enable" 3 "Invalid" ;
VAL_ 1242 USM_ProcStpReq 0 "Default" 1 "StopReq" ;
VAL_ 1242 USM_PwrAutoOffTimeSetReq 0 "Default" 1 "Timer1" 2 "Timer2" 3 "Timer3" 4 "Timer4" 5 "Reserved" 6 "Reserved" 7 "Invalid" ;
VAL_ 1242 USM_RrStRemindSetReq_RestMode 0 "Default" 1 "Off(Disable)" 2 "On(Enable)" 3 "Invalid" 4 "Reserved" 5 "Reserved" 6 "Not Used" 7 "Error Indicator" ;
VAL_ 1242 USM_1stRrStRemindSetReq 0 "Default" 1 "Off(Disable)" 2 "On(Enable)" 3 "Invalid" ;
VAL_ 1242 USM_Wpc2SetReq 0 "Default" 1 "Off(Disable)" 2 "On(Enable)" 3 "Invalid" ;
VAL_ 811 SBCM_AST_FD_Crc1Val 0 "0x0x0~0xFFFF:CRCValue" 65535 "0x0x0~0xFFFF:CRCValue" ;
VAL_ 811 USM_AstGhostDoorSta 0 "Default" 1 "Off" 2 "On" 3 "RESERVED" ;
VAL_ 811 AST_SWFailAlarm 0 "Off" 1 "On" 2 "RESERVED" 3 "Error Indicator" ;
VAL_ 811 DoorLock_PDSLkSwSta_AST 0 "Lock" 1 "Unlock" 2 "RESERVED" 3 "Error Indicator" ;
VAL_ 811 PDS_TypeOption_AST 0 "Off" 1 "On" 2 "RESERVED" 3 "Error Indicator" ;
VAL_ 811 AFCU_AutoWashModeSta_SBCM_AST 0 "Default" 1 "AFCU Auto Wash Mode Off (Ready)" 2 "AFCU Auto Wash Mode Off (Error)" 3 "AFCU Auto Wash Mode On" 4 "RESERVED" 5 "RESERVED" 6 "RESERVED" 7 "Invalid" ;
VAL_ 811 CDM_AutoWashModeSta_SBCM_AST 0 "Default" 1 "CDM Auto Wash Mode Off (Ready)" 2 "CDM Auto Wash Mode Off (Error)" 3 "CDM Auto Wash Mode On" 4 "RESERVED" 5 "RESERVED" 6 "RESERVED" 7 "Invalid" ;
VAL_ 811 AFH_AST_FldUnFldSta 0 "Invalid" 1 "Fold" 2 "Unfold" 3 "Inprogress" ;
VAL_ 811 SBCM_AST_DiagSta 0 "Default" 1 "Normal Operation" 2 "AST Indicator Circuit Failure" 3 "RESERVED" ;
VAL_ 811 CDM_TypeOption_AST 0 "Off" 1 "On" 2 "On_2EA" 3 "Error Indicator" ;
VAL_ 811 CDM_ImmeChgSw_AST 0 "Default" 1 "Off" 2 "On" 3 "RESERVED" ;
VAL_ 811 CDM_FobSrchReq_AST 0 "Off" 1 "On" 2 "RESERVED" 3 "Error Indicator" ;
VAL_ 811 CDM_OpnClsState_AST 0 "Default" 1 "Open" 2 "Close" 3 "RESERVED" ;
VAL_ 811 CDM_WarnMsg_AST 0 "Default" 1 "Normal" 2 "ChargeDoorErrorState" 3 "RESERVED" ;
VAL_ 811 Mirror_RH_FoldingSta 0 "Off" 1 "Folding" 2 "RESERVED" 3 "Error Indicator" ;
VAL_ 811 Mirror_RH_UnfoldingSta 0 "Off" 1 "Unfolding" 2 "RESERVED" 3 "Error Indicator" ;
VAL_ 811 CDM_CmdStatus_AST 0 "Open (AVN)" 1 "Open (SMK)" 2 "Open (Sensor Switch)" 3 "Open (Command Hard Switch)" 4 "Open (Anti - Pinch)" 5 "Close (AVN)" 6 "Close (SMK)" 7 "Close (Assist Mode)" 8 "Close (Command Hard Switch)" 9 "Close (Connector)" 10 "Close (Gear Position)" 11 "Close (Time Over)" 12 "Close (Anti - Pinch)" 13 "Close (Sensor Switch)" 14 "Stall (Stop)" 15 "Invalid" ;
VAL_ 811 SBCM_AST_FD_AlvCnt1Val 0 "0x0x0~0xFF:AlvCntValue" 255 "0x0x0~0xFF:AlvCntValue" ;
VAL_ 811 AST_CrashMRActAlarm 0 "Off" 1 "On" 2 "RESERVED" 3 "Error Indicator" ;
VAL_ 811 PwrDRBuzzerOut_AST 0 "OFF" 1 "Open" 2 "Close" 3 "Warning" ;
VAL_ 811 IMS_OSMirPlayBackSta_RH 0 "Stop" 1 "Play 1" 2 "Play 2" 3 "Play 3" 4 "Smart IMS" 5 "Profile 1" 6 "Profile 2" 7 "Guest" 8 "RESERVED" 9 "RESERVED" 10 "RESERVED" 11 "RESERVED" 12 "RESERVED" 13 "RESERVED" 14 "RESERVED" 15 "Error Indicator" ;
VAL_ 811 PwrDRClosingASTDrSta 0 "Default" 1 "Close" 2 "Open" 3 "Stop(during Close)" 4 "Stop(during Open)" 5 "RESERVED" 6 "RESERVED" 7 "Invalid" ;
VAL_ 811 CDM_OutsideOpnSwSta_AST 0 "Default" 1 "Push" 2 "RESERVED" 3 "Invalid" ;
VAL_ 811 SBCM_Longkey_ASTDrAtClsSwSta 0 "Default" 1 "Off" 2 "On" 3 "Error Indicator" ;
VAL_ 811 Hood_TypeOption_AST 0 "Off (Mechanical hood latch is applied)" 1 "On (E-Hood latch is applied)" 2 "RESERVED" 3 "Error Indicator" ;
VAL_ 811 Warn_HoodSwSta_AST 0 "Off" 1 "On" 2 "RESERVED" 3 "Error Indicator" ;
VAL_ 811 FrunkWarning_AST 0 "Off" 1 "On" 2 "RESERVED" 3 "Error Indicator" ;
VAL_ 811 SBCM_FrunkSta_AST 0 "Default" 1 "Valid" 2 "RESERVED" 3 "Error Indicator" ;
VAL_ 811 IMS_OSMirPlayBackSta_RH_New 0 "Stop" 1 "Play 1" 2 "Play 2" 3 "Play 3" 4 "Smart IMS" 5 "Profile 1" 6 "Profile 2" 7 "Profile 3" 8 "Profile 4" 9 "Profile 5" 10 "Profile 6" 11 "Profile 7" 12 "Profile 8" 13 "Profile 9" 14 "Guest" 15 "Error Indicator" ;
VAL_ 811 Ast_DrLkRetryFail_SBCM 0 "Normal" 1 "Fail" 2 "RESERVED" 3 "RESERVED" ;
VAL_ 811 DoorLock_AstLkOutSta_SBCM 0 "Off" 1 "On" 2 "Not Used" 3 "Error Indicator" ;
VAL_ 811 FrunkReleaseSwSta_SBCM_AST 0 "Off" 1 "HalfRelease" 2 "FullRelease" 3 "SwitchError" ;
VAL_ 811 FrunkInsideRelSwSta_SBCM_AST 0 "Off" 1 "On" 2 "Not Used" 3 "Error Indicator" ;
VAL_ 811 FrunkEmergencySwSta_SBCM_AST 0 "Off" 1 "On" 2 "Not Used" 3 "Error Indicator" ;
VAL_ 811 PwrDrSta_Ast 0 "Unavailable" 1 "Available" 2 "RESERVED" 3 "Error Indicator" ;
VAL_ 811 PwrDrSta_AstSd 0 "Unavailable" 1 "Available" 2 "RESERVED" 3 "Error Indicator" ;
VAL_ 811 DischrgDr_OpnClsState_SBCM_AST 0 "Default" 1 "Open" 2 "Close" 3 "Invalid" ;
VAL_ 811 AST_DetectObj_warn_LH 0 "Detect Left Warning OFF" 1 "Detect Left Warning ON" 2 "RESERVED" 3 "RESERVED" ;
VAL_ 811 PwrDROpenClosingAstSdDRSta 0 "Default" 1 "Close" 2 "Open" 3 "Stop(during Close)" 4 "Stop(during Open)" 5 "RESERVED" 6 "RESERVED" 7 "Invalid" ;
VAL_ 811 PwrDRBuzzerOut_AST_New 0 "OFF" 1 "Open" 2 "Close" 3 "Warning1" 4 "Warning2" ;
VAL_ 811 SBCM_FR_DoorAngle 0 "0° - 90°" 1 "0° - 90°" 2 "0° - 90°" 3 "0° - 90°" 4 "0° - 90°" 5 "0° - 90°" 6 "0° - 90°" 7 "0° - 90°" 8 "0° - 90°" 9 "0° - 90°" 10 "0° - 90°" 11 "0° - 90°" 12 "0° - 90°" 13 "0° - 90°" 14 "0° - 90°" 15 "0° - 90°" 16 "0° - 90°" 17 "0° - 90°" 18 "0° - 90°" 19 "0° - 90°" 20 "0° - 90°" 21 "0° - 90°" 22 "0° - 90°" 23 "0° - 90°" 24 "0° - 90°" 25 "0° - 90°" 26 "0° - 90°" 27 "0° - 90°" 28 "0° - 90°" 29 "0° - 90°" 30 "0° - 90°" 31 "0° - 90°" 32 "0° - 90°" 33 "0° - 90°" 34 "0° - 90°" 35 "0° - 90°" 36 "0° - 90°" 37 "0° - 90°" 38 "0° - 90°" 39 "0° - 90°" 40 "0° - 90°" 41 "0° - 90°" 42 "0° - 90°" 43 "0° - 90°" 44 "0° - 90°" 45 "0° - 90°" 46 "0° - 90°" 47 "0° - 90°" 48 "0° - 90°" 49 "0° - 90°" 50 "0° - 90°" 51 "0° - 90°" 52 "0° - 90°" 53 "0° - 90°" 54 "0° - 90°" 55 "0° - 90°" 56 "0° - 90°" 57 "0° - 90°" 58 "0° - 90°" 59 "0° - 90°" 60 "0° - 90°" 61 "0° - 90°" 62 "0° - 90°" 63 "0° - 90°" 64 "0° - 90°" 65 "0° - 90°" 66 "0° - 90°" 67 "0° - 90°" 68 "0° - 90°" 69 "0° - 90°" 70 "0° - 90°" 71 "0° - 90°" 72 "0° - 90°" 73 "0° - 90°" 74 "0° - 90°" 75 "0° - 90°" 76 "0° - 90°" 77 "0° - 90°" 78 "0° - 90°" 79 "0° - 90°" 80 "0° - 90°" 81 "0° - 90°" 82 "0° - 90°" 83 "0° - 90°" 84 "0° - 90°" 85 "0° - 90°" 86 "0° - 90°" 87 "0° - 90°" 88 "0° - 90°" 89 "0° - 90°" 90 "0° - 90°" 91 "Invalid" 92 "Invalid" 93 "Invalid" 94 "Invalid" 95 "Invalid" 96 "Invalid" 97 "Invalid" 98 "Invalid" 99 "Invalid" 100 "Unknown" 101 "Invalid" 102 "Invalid" 103 "Invalid" 104 "Invalid" 105 "Invalid" 106 "Invalid" 107 "Invalid" 108 "Invalid" 109 "Invalid" 110 "Invalid" 111 "Invalid" 112 "Invalid" 113 "Invalid" 114 "Invalid" 115 "Invalid" 116 "Invalid" 117 "Invalid" 118 "Invalid" 119 "Invalid" 120 "Invalid" 121 "Invalid" 122 "Invalid" 123 "Invalid" 124 "Invalid" 125 "Invalid" 126 "Invalid" 127 "Invalid" ;
VAL_ 811 EHL_TxInfo_SBCM_AST 0 "Default" 1 "EHL_AST_Close" 2 "EHL_AST_Half" 3 "EHL_AST_Open" 4 "EHL_AST_RetryFlag" 5 "EHL_AST_ErrorIndicator" 6 "EHL_AST_Opening" 7 "Invalid" ;
VAL_ 811 CDM_DrType_AST 0 "None" 1 "Electric" 2 "Manual" 3 "RESERVED" ;
VAL_ 811 ASTDoorPushAlarm 0 "Off" 1 "On" 2 "RESERVED" 3 "Error Indicator" ;
VAL_ 811 AST_CrashUnlockCmd 0 "Off" 1 "Unlock (Crash)" ;
VAL_ 811 DoorLock_CtrlDrLkSwSta_SBCM 0 "Off" 1 "On (Lock On)" 2 "RESERVED" 3 "Error Indicator" ;
VAL_ 811 DoorLock_CtrlDrUnLkSwSta_SBCM 0 "Off" 1 "On (Unlock On)" 2 "RESERVED" 3 "Error Indicator" ;
VAL_ 811 Warn_AsstDrSwSta_SBCM 0 "Close" 1 "Open" 2 "RESERVED" 3 "Error Indicator" ;
VAL_ 811 DoorLock_AsstDrUnLkSta_SBCM 0 "Lock" 1 "Unlock" 2 "RESERVED" 3 "Error Indicator" ;
VAL_ 811 AST_SEAWarn_RH 0 "SEA Right Warning OFF" 1 "SEA Right Warning ON" 2 "RESERVED" 3 "RESERVED" ;
VAL_ 811 AST_SEAWarn_LH 0 "SEA Left Warning OFF" 1 "SEA Left Warning ON" 2 "RESERVED" 3 "RESERVED" ;
VAL_ 811 AST_SEWWarn_LH 0 "SEW Left Warning OFF" 1 "SEW Left Warning ON" 2 "RESERVED" 3 "RESERVED" ;
VAL_ 811 AST_SEWWarn_RH 0 "SEW Right Warning OFF" 1 "SEW Right Warning ON" 2 "RESERVED" 3 "RESERVED" ;
VAL_ 811 AST_MRActivationAlarm 0 "Off" 1 "On" 2 "RESERVED" 3 "Error Indicator" ;
VAL_ 811 AST_ReleaseWarn 0 "Release Warning OFF" 1 "Release Warning ON" 2 "RESERVED" 3 "RESERVED" ;
VAL_ 789 CLU_Crc20Val 0 "0x0x0~0xFFFF:CRCValue" 65535 "0x0x0~0xFFFF:CRCValue" ;
VAL_ 789 CLU_AlvCnt20Val 0 "0x0x0~0xFF:AlvCntValue" 255 "0x0x0~0xFF:AlvCntValue" ;
VAL_ 789 CLU_SndType 0 "Cluster applied speaker" 1 "Cluster applied buzzer" 2 "Not used" 3 "Error Indicator" ;
VAL_ 789 USM_AdasHDPSetReq 0 "Default" 1 "OFF" 2 "ON" 3 "INVALID" ;
VAL_ 789 CLU_ClusterUSM 0 "Default" 1 "Cluster not applied USM" 2 "Cluster applied USM" 3 "Reserved" ;
VAL_ 849 IAU_FD_Crc4Val 0 "0x0x0~0xFFFF:CRCValue" 65535 "0x0x0~0xFFFF:CRCValue" ;
VAL_ 849 IAU_DISPWrng 0 "None" 1 "Auth_Fail2 (DigitalKey)" 2 "ReAuth_Warning" 3 "IAU Error" 4 "DigitalKey Saved" 5 "Auth_Fail2 (FP)" 6 "Auth_Fail2 (DigitalKey or FP)" 7 "BiometricKey Saved" 8 "DigitalKey and BiometricKey Saved" 9 "WPCNFC_PreStartAuth_Success" 10 "Reserved" 11 "Reserved" 12 "Reserved" 13 "Reserved" 14 "ReAuth_forRSPA" 15 "Invalid" ;
VAL_ 849 IAU_DigitalKey2Opt 0 "Default (Not applied)" 1 "Digital Key Light (NFC)" 2 "Digital Key Medium (NFC/BLE)" 3 "Digital Key Full (NFC/BLE/UWB)" 4 "Reserved" 5 "Reserved" 6 "Reserved" 7 "invalid" ;
VAL_ 849 IAUwFRULearnState 0 "Default (Normal)" 1 "Learning" 2 "Neutralizing" 3 "Invalid" ;
VAL_ 849 IAUwFPMLearnState 0 "Default(Normal)" 1 "Learning" 2 "Neutralizing" 3 "Invalid" ;
VAL_ 849 IAU_ValetDigitalkey 0 "Default" 1 "Valet Digitalkey" 2 "Resereved" 3 "invalid" ;
VAL_ 849 IAU_DigitalKeyNumberOpt 0 "Max8" 1 "Max16" 2 "Max16 with Grouping" 3 "RESERVED" 4 "RESERVED" 5 "RESERVED" 6 "RESERVED" 7 "Invalid" ;
VAL_ 849 IAU_eSEReprogramSta 0 "Default" 1 "Updating" 2 "RESERVED" 3 "Invalid" ;
VAL_ 849 IAU_DKOwnerSwapOption 0 "Default" 1 "Not applied" 2 "Applied" 3 "Invalid" ;
VAL_ 849 IAU_DgtKeyGrpPrflRval2 0 "Default" 1 "Group index 0x0" 2 "Group index 0x1" 3 "Group index 0x2" 4 "Group index 0x3" 5 "Group index 0x4" 6 "Group index 0x5" 7 "Group index 0x6" 8 "Group index 0x7" 9 "Group index 0x8" 10 "Group index 0x9" 11 "Group index 0xA" 12 "Group index 0xB" 13 "Group index 0xC" 14 "Group index 0xD" 15 "Group index 0xE" 16 "Group index 0xF" 17 "RESERVED" 18 "RESERVED" 19 "RESERVED" 20 "RESERVED" 21 "RESERVED" 22 "RESERVED" 23 "RESERVED" 24 "RESERVED" 25 "RESERVED" 26 "RESERVED" 27 "RESERVED" 28 "RESERVED" 29 "RESERVED" 30 "RESERVED" 31 "Invalid" ;
VAL_ 849 IAU_StartIdentifiedProfile 0 "Default" 1 "Profile 1" 2 "Profile 2" 3 "Reserved" 4 "Reserved" 5 "Reserved" 6 "Reserved" 7 "Invalid" ;
VAL_ 849 IAU_DigitalKeyProfileRval2 0 "Default" 1 "1st digital key (owner)" 2 "2nd digital key" 3 "3rd digital key" 4 "4th digital key" 5 "5th digital key" 6 "6th digital key" 7 "7th digital key" 8 "8th digital key" 9 "9th digital key" 10 "10th digital key" 11 "11th digital key" 12 "12th digital key" 13 "13th digital key" 14 "14th digital key" 15 "15th digital key" 16 "16th digital key" 17 "reserved" 18 "reserved" 19 "reserved" 20 "reserved" 21 "reserved" 22 "reserved" 23 "reserved" 24 "reserved" 25 "reserved" 26 "reserved" 27 "reserved" 28 "reserved" 29 "reserved" 30 "reserved" 31 "Invalid" ;
VAL_ 849 IAU_NFCCard1SN 0 "0x0x00000000~0xFFFFFFFF:" 2147483647 "0x0x00000000~0xFFFFFFFF:" ;
VAL_ 849 IAU_FD_AlvCnt4Val 0 "0x0x0~0xFF:AlvCntValue" 255 "0x0x0~0xFF:AlvCntValue" ;
VAL_ 849 IAU_StartIdentifiedProfile_Ext 0 "Default" 1 "Profile1" 2 "Profile2" 3 "Profile3" 4 "Profile4" 5 "Profile5" 6 "Profile6" 7 "Profile7" 8 "Profile8" 9 "Profile9" 10 "RESERVED" 11 "RESERVED" 12 "RESERVED" 13 "RESERVED" 14 "RESERVED" 15 "INVALID" ;
VAL_ 849 RSPA_UWBRspaExtRngSta 0 "Initial" 1 "Out of range of RSPA remote control Region" 2 "In the range of RSPA remote control region" 3 "Reserved" ;
VAL_ 849 RSPA_CanFltSta 0 "Default" 1 "RSPA CAN Error" 2 "Not Used" 3 "Error Indicator" ;
VAL_ 849 RSPA_BLESigErrSta 0 "Default" 1 "Signal Invalid" 2 "In Progress" 3 "Error Indicator" ;
VAL_ 849 RSPA_ConStat 0 "Normal Status" 1 "Fail Status" 2 "Reserved" 3 "Reserved" ;
VAL_ 849 IAU_ProfileIDRVal 0 "Default" 1 "Guest" 2 "Profile1" 3 "Profile2" 4 "Profile3" 5 "Profile4" 6 "Profile5" 7 "Profile6" 8 "Profile7" 9 "Profile8" 10 "Profile9" 11 "RESERVED" 12 "RESERVED" 13 "RESERVED" 14 "RESERVED" 15 "INVALID" ;
VAL_ 849 IAU_DigitalKeyProcessingSta 0 "None" 1 "DeviceOnWPC" 2 "DeviceRegistering" 3 "PhoneRegistered" 4 "All Phone Key Deleted" 5 "NFCCard1Registered" 6 "Server Registering" 7 "NFCCard1Deleted" 8 "BLE Searching" 9 "Owner Phone key Deleted" 10 "Valet Off Searching" 11 "Server Registering Fail" 12 "All Digital Keys in group Deleted" 15 "Invalid" ;
VAL_ 849 IAU_DigitalKeyExit 0 "Normal" 1 "Check System" 2 "NFC Not Detected" 3 "Fob Not Detected" 4 "Canceled by User (Timeout)" 5 "Device not Available" 6 "ProcessFail" 7 "Check Card Save" 8 "Certificate Update" 9 "Valet Off Fail" 10 "CardNotAvailable" 11 "DigitalKeyDisabled" 12 "Retry After Parking" 13 "Check Password" 14 "P position fail (not P)" 15 "Invalid" ;
VAL_ 849 IAU_DigitalKeyEnblRVal 0 "Default" 1 "Disable" 2 "Enable" 3 "Invalid" ;
VAL_ 849 IAU_OwnerPhnRegRVal 0 "Default" 1 "Disable" 2 "Enable" 3 "Invalid" ;
VAL_ 849 IAU_NFCCard1RegRVal 0 "Default" 1 "Disable" 2 "Enable" 3 "Invalid" ;
VAL_ 849 IAU_NFCCard2RegRVal 0 "Default" 1 "Disable" 2 "Enable" 3 "Invalid" ;
VAL_ 788 RWPC_FD_Crc1Val 0 "0x0x0~0xFFFF:CRCValue" 65535 "0x0x0~0xFFFF:CRCValue" ;
VAL_ 788 RWPC_IndSyncVal 0 "default" 1 "off" 2 "1st sync" 3 "2nd sync" 4 "3rd sync" 5 "error off" 6 "error on" 7 "reserved" ;
VAL_ 788 RWPC_ResetOpSta 0 "Normal" 1 "Reset Complete" 2 "Reset Fail" 3 "RESERVED" ;
VAL_ 788 RWPC_FD_AlvCnt1Val 0 "0x0x0~0xFF:AlvCntValue" 255 "0x0x0~0xFF:AlvCntValue" ;
VAL_ 788 USM_ValCmdSta 0 "Default" 1 "Off(Disable)" 2 "On(Enable)" 3 "Invalid" ;
VAL_ 788 WPC_PhnLftWrngRWPCSta 0 "Off" 1 "Cellphone on the pad" 2 "Charging" 3 "Charging complete" 4 "Cellphone reminder" 5 "Error" 6 "NFC Card detected" 7 "Invalid" ;
VAL_ 788 USM_ValCmdStaforATS 0 "Default" 1 "Off(Disable)" 2 "On(Enable)" 3 "Invalid" ;
VAL_ 788 RWPC_SWVerMajor1 0 "0x0x0~0x7F:ASCII Code Value (HEX)" 127 "0x0x0~0x7F:ASCII Code Value (HEX)" ;
VAL_ 788 RWPC_SWVerMinor1 0 "0x0x0~0x7F:ASCII Code Value (HEX)" 127 "0x0x0~0x7F:ASCII Code Value (HEX)" ;
VAL_ 788 RWPC_SWVerMinor2 0 "0x0x0~0x7F:ASCII Code Value (HEX)" 127 "0x0x0~0x7F:ASCII Code Value (HEX)" ;
VAL_ 977 BDC_FD_Crc2Val 0 "0x0x0~0xFFFF:CRCValue" 65535 "0x0x0~0xFFFF:CRCValue" ;
VAL_ 977 BDC_FD_AlvCnt2Val 0 "0x0x0~0xFF:AlvCntValue" 255 "0x0x0~0xFF:AlvCntValue" ;
VAL_ 977 BCM_KeyInSta 0 "Off (Key removed)" 1 "On (Key inserted)" 2 "Not Used" 3 "Error Indicator" ;
VAL_ 977 BCM_AccInSta 0 "Acc Off" 1 "Acc On" 2 "Not Used" 3 "Error Indicator" ;
VAL_ 977 BCM_Ign1InSta 0 "IGN1 Off" 1 "IGN1 On" 2 "Not Used" 3 "Error Indicator" ;
VAL_ 977 BCM_Ign2InSta 0 "IGN2 Off" 1 "IGN2 On" 2 "Not Used" 3 "Error Indicator" ;
VAL_ 977 IBU_HDPSpprtSWVer 0 "Not Support (Init)" 1 "SW Version" 2 "SW Version" 3 "SW Version" 4 "SW Version" 5 "SW Version" 6 "SW Version" 7 "SW Version" 8 "SW Version" 9 "SW Version" 10 "SW Version" 11 "SW Version" 12 "SW Version" 13 "SW Version" 14 "SW Version" 15 "SW Version" 16 "SW Version" 17 "SW Version" 18 "SW Version" 19 "SW Version" 20 "SW Version" 21 "SW Version" 22 "SW Version" 23 "SW Version" 24 "SW Version" 25 "SW Version" 26 "SW Version" 27 "SW Version" 28 "SW Version" 29 "SW Version" 30 "SW Version" 31 "SW Version" 32 "SW Version" 33 "SW Version" 34 "SW Version" 35 "SW Version" 36 "SW Version" 37 "SW Version" 38 "SW Version" 39 "SW Version" 40 "SW Version" 41 "SW Version" 42 "SW Version" 43 "SW Version" 44 "SW Version" 45 "SW Version" 46 "SW Version" 47 "SW Version" 48 "SW Version" 49 "SW Version" 50 "SW Version" 51 "SW Version" 52 "SW Version" 53 "SW Version" 54 "SW Version" 55 "SW Version" 56 "SW Version" 57 "SW Version" 58 "SW Version" 59 "SW Version" 60 "SW Version" 61 "SW Version" 62 "SW Version" 63 "Error Indicator" ;
VAL_ 977 IBU_HDPSpprtRdy 0 "Normal" 1 "ADAS Message Not Recognized" 2 "RESERVED" 3 "RESERVED" ;
VAL_ 977 BCM_GearPosPSta 0 "Off" 1 "P" 2 "Not Used" 3 "Error Indicator" ;
VAL_ 977 BCM_SmkOptTyp 0 "Non SMK Option" 1 "SMK Option" 2 "Not Used" 3 "Error Indicator" ;
VAL_ 977 BDC_ResetOpSta 0 "Normal" 1 "Reset Complete" 2 "Reset Fail" 3 "RESERVED" ;
VAL_ 977 IBU_SWVerMajor1 0 "0x0x0~0x7F:ASCII Code Value (HEX)" 127 "0x0x0~0x7F:ASCII Code Value (HEX)" ;
VAL_ 977 IBU_SWVerMinor1 0 "0x0x0~0x7F:ASCII Code Value (HEX)" 127 "0x0x0~0x7F:ASCII Code Value (HEX)" ;
VAL_ 977 IBU_SWVerMinor2 0 "0x0x0~0x7F:ASCII Code Value (HEX)" 127 "0x0x0~0x7F:ASCII Code Value (HEX)" ;
VAL_ 977 BDC_PlatformVerType 0 "Default(Not Defined)" 1 "A" 2 "B" 3 "C" 4 "Not Used" 5 "Not Used" 6 "Not Used" 7 "Not Used" 8 "Not Used" 9 "Not Used" 10 "Not Used" 11 "Not Used" 12 "Not Used" 13 "Not Used" 14 "Not Used" 15 "Invalid" ;
VAL_ 977 BDC_PlatformVerDate 0 "Default(Not Defined)" 1 "2301" 2 "2302" 3 "2303" 4 "2304" 5 "2305" 6 "0x6~0xFE:YYMM(2306~)" 254 "0x6~0xFE:YYMM(2306~)" 255 "Invalid" ;
VAL_ 914 WPC2_FD_Crc1Val 0 "0x0x0~0xFFFF:CRCValue" 65535 "0x0x0~0xFFFF:CRCValue" ;
VAL_ 914 WPC2_IndSyncVal 0 "default" 1 "off" 2 "1st sync" 3 "2nd sync" 4 "3rd sync" 5 "error off" 6 "error on" 7 "reserved" ;
VAL_ 914 WPC2_ResetOpSta 0 "Normal" 1 "Reset Complete" 2 "Reset Fail" 3 "RESERVED" ;
VAL_ 914 WPC2_FD_AlvCnt1Val 0 "0x0x0~0xFF:AlvCntValue" 255 "0x0x0~0xFF:AlvCntValue" ;
VAL_ 914 USM_CmdWPC2Sta 0 "Default" 1 "Off(Disable)" 2 "On(Enable)" 3 "Invalid" ;
VAL_ 914 WPC2_PhnLftWrngSta 0 "Off" 1 "Cellphone on the pad" 2 "Charging" 3 "Charging complete" 4 "Cellphone reminder" 5 "Error" 6 "NFC Card detected" 7 "Invalid" ;
VAL_ 914 WPC2_OptSta 0 "Default" 1 "Apply" 2 "RESERVED" 3 "Invalid" ;
VAL_ 914 WPC2_SWVerMajor1 0 "0x0x0~0x7F:ASCII Code Value (HEX)" 127 "0x0x0~0x7F:ASCII Code Value (HEX)" ;
VAL_ 914 WPC2_SWVerMinor1 0 "0x0x0~0x7F:ASCII Code Value (HEX)" 127 "0x0x0~0x7F:ASCII Code Value (HEX)" ;
VAL_ 914 WPC2_SWVerMinor2 0 "0x0x0~0x7F:ASCII Code Value (HEX)" 127 "0x0x0~0x7F:ASCII Code Value (HEX)" ;
